VERSION "2021.24.4"

NS_ :

BS_:

BU_: VEH CH Receiver X

BO_ 22 DI_bmsRequest: 1 VEH
 SG_ DI_bmsOpenContactorsRequest : 4|1@1+ (1,0) [0|1] ""  Receiver
 SG_ DI_bmsRequestInterfaceVersion : 0|4@1+ (1,0) [0|15] ""  Receiver

BO_ 470 DIR_limits: 8 Vector__XXX
 SG_ DIR_pstgDisableSW3PS : 63|1@1+ (1,0) [0|0] "" Vector__XXX
 SG_ DIR_pstgDisableHW3PS : 62|1@1+ (1,0) [0|0] "" Vector__XXX
 SG_ DIR_currentLimit : 46|16@1+ (0.1,0) [0|0] "" Vector__XXX
 SG_ DIR_magnetFluxError : 38|8@1- (8e-05,0) [0|0] "" Vector__XXX
 SG_ DIR_statorTempFromResist : 30|8@1+ (1,-40) [0|0] "" Vector__XXX
 SG_ DIR_limitStatorHousingTemp : 29|1@1+ (1,0) [0|0] "" Vector__XXX
 SG_ DIR_limitUnitSpinDownLearning : 28|1@1+ (1,0) [0|0] "" Vector__XXX
 SG_ DIR_limithvDcCableTemp : 27|1@1+ (1,0) [0|0] "" Vector__XXX
 SG_ DIR_limitRotorTemp : 26|1@1+ (1,0) [0|0] "" Vector__XXX
 SG_ DIR_limitposDcBusbarTemp : 25|1@1+ (1,0) [0|0] "" Vector__XXX
 SG_ DIR_limitnegDcBusbarTemp : 24|1@1+ (1,0) [0|0] "" Vector__XXX
 SG_ DIR_limitdcLinkCapTemp : 23|1@1+ (1,0) [0|0] "" Vector__XXX
 SG_ DIR_limitphaseOutLugTemp : 22|1@1+ (1,0) [0|0] "" Vector__XXX
 SG_ DIR_limitphaseOutBusBarWeldTemp : 21|1@1+ (1,0) [0|0] "" Vector__XXX
 SG_ DIR_limitphaseOutBusbarTemp : 20|1@1+ (1,0) [0|0] "" Vector__XXX
 SG_ DIR_limitClutch : 19|1@1+ (1,0) [0|0] "" Vector__XXX
 SG_ DIR_limitStatorFrequency : 18|1@1+ (1,0) [0|0] "" Vector__XXX
 SG_ DIR_limitOilPumpFluidTemp : 17|1@1+ (1,0) [0|0] "" Vector__XXX
 SG_ DIR_limitShockTorque : 16|1@1+ (1,0) [0|0] "" Vector__XXX
 SG_ DIR_limitUnitGPO : 15|1@1+ (1,0) [0|0] "" Vector__XXX
 SG_ DIR_limitDiff : 14|1@1+ (1,0) [0|0] "" Vector__XXX
 SG_ DIR_limitMotorSpeed : 13|1@1+ (1,0) [0|0] "" Vector__XXX
 SG_ DIR_limitDcCapTemp : 12|1@1+ (1,0) [0|0] "" Vector__XXX
 SG_ DIR_limitBaseSpeed : 11|1@1+ (1,0) [0|0] "" Vector__XXX
 SG_ DIR_limitTCRegen : 10|1@1+ (1,0) [0|0] "" Vector__XXX
 SG_ DIR_limitTCDrive : 9|1@1+ (1,0) [0|0] "" Vector__XXX
 SG_ DIR_limitMotorVoltage : 8|1@1+ (1,0) [0|0] "" Vector__XXX
 SG_ DIR_limitMotorCurrent : 7|1@1+ (1,0) [0|0] "" Vector__XXX
 SG_ DIR_limitDischargePower : 6|1@1+ (1,0) [0|0] "" Vector__XXX
 SG_ DIR_limitDeltaFluidTemp : 5|1@1+ (1,0) [0|0] "" Vector__XXX
 SG_ DIR_limitUnitLimp : 4|1@1+ (1,0) [0|0] "" Vector__XXX
 SG_ DIR_limitPoleTemp : 3|1@1+ (1,0) [0|0] "" Vector__XXX
 SG_ DIR_limitStatorTemp : 2|1@1+ (1,0) [0|0] "" Vector__XXX
 SG_ DIR_limitInverterTemp : 1|1@1+ (1,0) [0|0] "" Vector__XXX
 SG_ DIR_limitPCBTemp : 0|1@1+ (1,0) [0|0] "" Vector__XXX

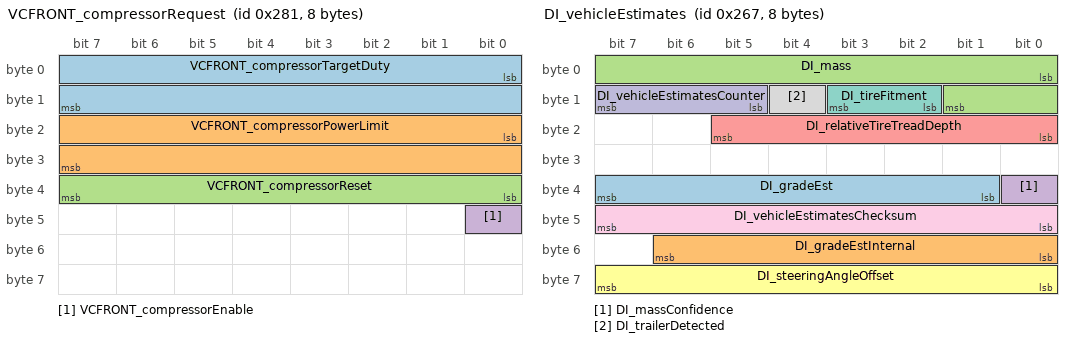
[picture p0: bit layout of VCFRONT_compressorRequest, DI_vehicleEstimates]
BO_ 641 VCFRONT_compressorRequest: 8 VEH
 SG_ VCFRONT_compressorTargetDuty : 0|16@1+ (0.1,0) [0|100] "%"  Receiver
 SG_ VCFRONT_compressorPowerLimit : 16|16@1+ (1,0) [0|65534] "W"  Receiver
 SG_ VCFRONT_compressorReset : 32|8@1+ (1,0) [0|255] ""  Receiver
 SG_ VCFRONT_compressorEnable : 40|1@1+ (1,0) [0|1] ""  Receiver

BO_ 603 APP_status: 8 Vector__XXX
 SG_ APP_statusChecksum : 56|8@1+ (1,0) [0|0] "" Vector__XXX
 SG_ APP_statusCounter : 52|4@1+ (1,0) [0|0] "" Vector__XXX
 SG_ APP_suspendResumeAvailable : 51|1@1+ (1,0) [0|0] "" Vector__XXX
 SG_ APP_uiEthFailoverDisabled : 50|1@1+ (1,0) [0|0] "" Vector__XXX
 SG_ APP_autonomySystemHealth : 49|1@1+ (1,0) [0|0] "" Vector__XXX
 SG_ APP_autoparkVersionIdentifier : 47|2@1+ (1,0) [0|0] "" Vector__XXX
 SG_ APP_sentryState : 44|3@1+ (1,0) [0|0] "" Vector__XXX
 SG_ APP_summonVersionIdentifier : 42|2@1+ (1,0) [0|0] "" Vector__XXX
 SG_ APP_socOperatingMode : 40|2@1+ (1,0) [0|0] "" Vector__XXX
 SG_ APP_DDAWSystemStatus : 37|3@1+ (1,0) [0|0] "" Vector__XXX
 SG_ APP_sendingBUCStream : 35|1@1+ (1,0) [0|0] "" Vector__XXX
 SG_ APP_unifiedObjectStackSupported : 33|2@1+ (1,0) [0|0] "" Vector__XXX
 SG_ APP_excessiveAccelPedalWarning : 32|1@1+ (1,0) [0|0] "" Vector__XXX
 SG_ APP_fsdRevokeCount : 29|3@1+ (1,0) [0|0] "" Vector__XXX
 SG_ APP_teslaVisionUnsupportedReason : 26|3@1+ (1,0) [0|0] "" Vector__XXX
 SG_ APP_teslaVisionSupported : 24|2@1+ (1,0) [0|0] "" Vector__XXX
 SG_ APP_fsdRevokeStrikeoutCount : 21|3@1+ (1,0) [0|0] "" Vector__XXX
 SG_ APP_fsdSuspendState : 19|2@1+ (1,0) [0|0] "" Vector__XXX
 SG_ APP_summonUnavailableReason : 14|5@1+ (1,0) [0|0] "" Vector__XXX
 SG_ APP_allowApActivationWithBrake : 13|1@1+ (1,0) [0|0] "" Vector__XXX
 SG_ APP_clipRecordingStatus : 10|3@1+ (1,0) [0|0] "" Vector__XXX
 SG_ APP_factorySummonStatus : 6|4@1+ (1,0) [0|0] "" Vector__XXX
 SG_ APP_cameraHeaterRequest : 5|1@1+ (1,0) [0|0] "" Vector__XXX
 SG_ APP_fusedState : 3|2@1+ (1,0) [0|0] "" Vector__XXX
 SG_ APP_watchdogState : 0|3@1+ (1,0) [0|0] "" Vector__XXX

BO_ 615 DI_vehicleEstimates: 8 VEH
 SG_ DI_gradeEst : 33|7@1- (1,0) [-40|40] "%"  Receiver
 SG_ DI_gradeEstInternal : 48|7@1- (1,0) [-40|40] "%"  Receiver
 SG_ DI_mass : 0|10@1+ (5,1900) [1900|7010] "kg"  Receiver
 SG_ DI_massConfidence : 32|1@1+ (1,0) [0|1] ""  Receiver
 SG_ DI_relativeTireTreadDepth : 16|6@1- (0.2,0) [-6.2|6.2] "mm"  Receiver
 SG_ DI_steeringAngleOffset : 56|8@1- (0.2,0) [-25.6|25.4] "Deg"  Receiver
 SG_ DI_tireFitment : 10|2@1+ (1,0) [0|3] ""  Receiver
 SG_ DI_trailerDetected : 12|1@1+ (1,0) [0|1] ""  Receiver
 SG_ DI_vehicleEstimatesChecksum : 40|8@1+ (1,0) [0|255] ""  Receiver
 SG_ DI_vehicleEstimatesCounter : 13|3@1+ (1,0) [0|7] ""  Receiver

BO_ 322 VCLEFT_liftgateStatus: 8 Vector__XXX
 SG_ VCLEFT_liftgateLatchRequest m0 : 61|3@1+ (1,0) [0|0] "" Vector__XXX
 SG_ VCLEFT_liftgateAboveCrossoverAng m0 : 59|1@1+ (1,0) [0|0] "" Vector__XXX
 SG_ VCLEFT_liftgateCloseWarnChimeReq m0 : 56|1@1+ (1,0) [0|0] "" Vector__XXX
 SG_ VCLEFT_liftgateGeofenceState m0 : 48|2@1+ (1,0) [0|0] "" Vector__XXX
 SG_ VCLEFT_liftgateNewSaveHeight m0 : 40|8@1+ (1,0) [0|0] "" Vector__XXX
 SG_ VCLEFT_liftgateNewHeightNudge m0 : 39|1@1+ (1,0) [0|0] "" Vector__XXX
 SG_ VCLEFT_liftgateHeight m1 : 38|8@1+ (1,0) [0|0] "" Vector__XXX
 SG_ VCLEFT_liftgateRequestSource m0 : 35|4@1+ (1,0) [0|0] "" Vector__XXX
 SG_ VCLEFT_liftgateStaticStrutMode m0 : 32|3@1+ (1,0) [0|0] "" Vector__XXX
 SG_ VCLEFT_liftgateSpeed m1 : 28|10@1- (0.1,0) [0|0] "" Vector__XXX
 SG_ VCLEFT_liftgateEstimatedStrutTem m0 : 24|8@1+ (1,-60) [0|0] "" Vector__XXX
 SG_ VCLEFT_liftgatePhysicalChimeRequ m0 : 21|3@1+ (1,0) [0|0] "" Vector__XXX
 SG_ VCLEFT_liftgatePosition m1 : 21|7@1- (1,46) [0|0] "" Vector__XXX
 SG_ VCLEFT_liftgateUIChimeRequest m0 : 18|3@1+ (1,0) [0|0] "" Vector__XXX
 SG_ VCLEFT_liftgatePositionCalibrate m0 : 17|1@1+ (1,0) [0|0] "" Vector__XXX
 SG_ VCLEFT_liftgateMvmntNotAllowedCo m0 : 14|3@1+ (1,0) [0|0] "" Vector__XXX
 SG_ VCLEFT_liftgateStrutCurrent m1 : 11|10@1- (0.1,0) [0|0] "" Vector__XXX
 SG_ VCLEFT_liftgateStoppingCondition m0 : 10|4@1+ (1,0) [0|0] "" Vector__XXX
 SG_ VCLEFT_liftgateState m0 : 3|4@1+ (1,0) [0|0] "" Vector__XXX
 SG_ VCLEFT_liftgateStrutDutyCycle m1 : 3|8@1- (1,0) [0|0] "" Vector__XXX
 SG_ VCLEFT_liftgateStatusIndex M : 0|2@1+ (1,0) [0|0] "" Vector__XXX

BO_ 537 VCSEC_TPMSData: 7 CH
 SG_ VCSEC_TPMSDataIndex M : 0|3@1+ (1,0) [0|5] ""  Receiver
 SG_ VCSEC_TPMSPressureFL m5 : 16|8@1+ (0.025,0) [0|6.375] "bar" X
 SG_ VCSEC_TPMSPressureFR m5 : 24|8@1+ (0.025,0) [0|6.375] "bar" X
 SG_ VCSEC_TPMSPressureRL m5 : 32|8@1+ (0.025,0) [0|6.375] "bar" X
 SG_ VCSEC_TPMSPressureRR m5 : 40|8@1+ (0.025,0) [0|6.375] "bar" X
 SG_ VCSEC_TPMSPressure0 m0 : 16|8@1+ (0.05,-1) [-1|11.75] "bar" X
 SG_ VCSEC_TPMSPressure1 m1 : 16|8@1+ (0.05,-1) [-1|11.75] "bar" X
 SG_ VCSEC_TPMSPressure2 m2 : 16|8@1+ (0.05,-1) [-1|11.75] "bar" X
 SG_ VCSEC_TPMSPressure3 m3 : 16|8@1+ (0.05,-1) [-1|11.75] "bar" X
 SG_ VCSEC_TPMSTemperature0 m0 : 24|8@1+ (1,-40) [-40|215] "C" X
 SG_ VCSEC_TPMSTemperature1 m1 : 24|8@1+ (1,-40) [-40|215] "C" X
 SG_ VCSEC_TPMSTemperature2 m2 : 24|8@1+ (1,-40) [-40|215] "C" X
 SG_ VCSEC_TPMSTemperature3 m3 : 24|8@1+ (1,-40) [-40|215] "C" X
 SG_ VCSEC_TPMSBatVoltage0 m0 : 32|8@1+ (0.01,1.5) [1.5|4.04] "V" X
 SG_ VCSEC_TPMSBatVoltage1 m1 : 32|8@1+ (0.01,1.5) [1.5|4.04] "V" X
 SG_ VCSEC_TPMSBatVoltage2 m2 : 32|8@1+ (0.01,1.5) [1.5|4.04] "V" X
 SG_ VCSEC_TPMSBatVoltage3 m3 : 32|8@1+ (0.01,1.5) [1.5|4.04] "V" X

BO_ 1066 VCSEC_TPMSConnectionData: 8 Vector__XXX
 SG_ VCSEC_TPMSSensorPresence3 : 62|2@1+ (1,0) [0|0] "" Vector__XXX
 SG_ VCSEC_TPMSSensorPresence2 : 60|2@1+ (1,0) [0|0] "" Vector__XXX
 SG_ VCSEC_TPMSSensorPresence1 : 58|2@1+ (1,0) [0|0] "" Vector__XXX
 SG_ VCSEC_TPMSSensorPresence0 : 56|2@1+ (1,0) [0|0] "" Vector__XXX
 SG_ VCSEC_TPMSConnectionTypeDesired3 : 54|2@1+ (1,0) [0|0] "" Vector__XXX
 SG_ VCSEC_TPMSConnectionTypeCurrent3 : 52|2@1+ (1,0) [0|0] "" Vector__XXX
 SG_ VCSEC_TPMSRSSI3 : 45|7@1+ (1,-127) [0|0] "" Vector__XXX
 SG_ VCSEC_TPMSSensorState3 : 42|3@1+ (1,0) [0|0] "" Vector__XXX
 SG_ VCSEC_TPMSConnectionTypeDesired2 : 40|2@1+ (1,0) [0|0] "" Vector__XXX
 SG_ VCSEC_TPMSConnectionTypeCurrent2 : 38|2@1+ (1,0) [0|0] "" Vector__XXX
 SG_ VCSEC_TPMSRSSI2 : 31|7@1+ (1,-127) [0|0] "" Vector__XXX
 SG_ VCSEC_TPMSSensorState2 : 28|3@1+ (1,0) [0|0] "" Vector__XXX
 SG_ VCSEC_TPMSConnectionTypeDesired1 : 26|2@1+ (1,0) [0|0] "" Vector__XXX
 SG_ VCSEC_TPMSConnectionTypeCurrent1 : 24|2@1+ (1,0) [0|0] "" Vector__XXX
 SG_ VCSEC_TPMSRSSI1 : 17|7@1+ (1,-127) [0|0] "" Vector__XXX
 SG_ VCSEC_TPMSSensorState1 : 14|3@1+ (1,0) [0|0] "" Vector__XXX
 SG_ VCSEC_TPMSConnectionTypeDesired0 : 12|2@1+ (1,0) [0|0] "" Vector__XXX
 SG_ VCSEC_TPMSConnectionTypeCurrent0 : 10|2@1+ (1,0) [0|0] "" Vector__XXX
 SG_ VCSEC_TPMSRSSI0 : 3|7@1+ (1,-127) [0|0] "" Vector__XXX
 SG_ VCSEC_TPMSSensorState0 : 0|3@1+ (1,0) [0|0] "" Vector__XXX

BO_ 994 VCLEFT_lightStatus: 8 Vector__XXX
 SG_ VCLEFT_tailLightOutageStatus : 51|1@1+ (1,0) [0|0] "" Vector__XXX
 SG_ VCLEFT_reverseTrailerLightStatus : 49|2@1+ (1,0) [0|0] "" Vector__XXX
 SG_ VCLEFT_rideHeightSensorFault : 48|1@1+ (1,0) [0|0] "" Vector__XXX
 SG_ VCLEFT_trailerDetected : 46|2@1+ (1,0) [0|0] "" Vector__XXX
 SG_ VCLEFT_rearRideHeight : 36|8@1- (1,0) [0|0] "" Vector__XXX
 SG_ VCLEFT_frontRideHeight : 28|8@1- (1,0) [0|0] "" Vector__XXX
 SG_ VCLEFT_fogTrailerLightStatus : 26|2@1+ (1,0) [0|0] "" Vector__XXX
 SG_ VCLEFT_tailTrailerLightStatus : 24|2@1+ (1,0) [0|0] "" Vector__XXX
 SG_ VCLEFT_brakeTrailerLightStatus : 22|2@1+ (1,0) [0|0] "" Vector__XXX
 SG_ VCLEFT_rightTrnTrailerLightStatu : 20|2@1+ (1,0) [0|0] "" Vector__XXX
 SG_ VCLEFT_leftTurnTrailerLightStatu : 18|2@1+ (1,0) [0|0] "" Vector__XXX
 SG_ VCLEFT_RRMapLightSwitchPressed : 17|1@1+ (1,0) [0|0] "" Vector__XXX
 SG_ VCLEFT_RLMapLightSwitchPressed : 16|1@1+ (1,0) [0|0] "" Vector__XXX
 SG_ VCLEFT_FRMapLightSwitchPressed : 15|1@1+ (1,0) [0|0] "" Vector__XXX
 SG_ VCLEFT_FLMapLightSwitchPressed : 14|1@1+ (1,0) [0|0] "" Vector__XXX
 SG_ VCLEFT_RRMapLightStatus : 12|2@1+ (1,0) [0|0] "" Vector__XXX
 SG_ VCLEFT_RLMapLightStatus : 10|2@1+ (1,0) [0|0] "" Vector__XXX
 SG_ VCLEFT_FRMapLightStatus : 8|2@1+ (1,0) [0|0] "" Vector__XXX
 SG_ VCLEFT_FLMapLightStatus : 6|2@1+ (1,0) [0|0] "" Vector__XXX
 SG_ VCLEFT_turnSignalStatus : 4|2@1+ (1,0) [0|0] "" Vector__XXX
 SG_ VCLEFT_tailLightStatus : 2|2@1+ (1,0) [0|0] "" Vector__XXX
 SG_ VCLEFT_brakeLightStatus : 0|2@1+ (1,0) [0|0] "" Vector__XXX

BO_ 513 VCFRONT_loggingAndVitals10Hz: 8 Vector__XXX
 SG_ VCFRONT_frunkSwitchGroupState m1 : 62|2@1+ (1,0) [0|0] "" Vector__XXX
 SG_ VCFRONT_ccrExvState m3 : 59|4@1+ (1,0) [0|0] "" Vector__XXX
 SG_ VCFRONT_recircExvState m2 : 59|4@1+ (1,0) [0|0] "" Vector__XXX
 SG_ VCFRONT_frunkStateDBG m1 : 58|4@1+ (1,0) [0|0] "" Vector__XXX
 SG_ VCFRONT_thermalHvPowerBudget m0 : 57|7@1+ (0.2,0) [0|0] "" Vector__XXX
 SG_ VCFRONT_compSleepRequest m0 : 56|1@1+ (1,0) [0|0] "" Vector__XXX
 SG_ VCFRONT_cclExvState m3 : 55|4@1+ (1,0) [0|0] "" Vector__XXX
 SG_ VCFRONT_compLiqPumpOutState m1 : 55|3@1+ (1,0) [0|0] "" Vector__XXX
 SG_ VCFRONT_evapExvState m2 : 55|4@1+ (1,0) [0|0] "" Vector__XXX
 SG_ VCFRONT_hpReqTransScavenge m1 : 54|1@1+ (1,0) [0|0] "" Vector__XXX
 SG_ VCFRONT_chillerExvState m2 : 51|4@1+ (1,0) [0|0] "" Vector__XXX
 SG_ VCFRONT_hpReqCoolantMode m1 : 51|3@1+ (1,0) [0|0] "" Vector__XXX
 SG_ VCFRONT_lccExvState m3 : 51|4@1+ (1,0) [0|0] "" Vector__XXX
 SG_ VCFRONT_hpBatteryLoadType m1 : 49|2@1+ (1,0) [0|0] "" Vector__XXX
 SG_ VCFRONT_hpCabinLoadType m1 : 47|2@1+ (1,0) [0|0] "" Vector__XXX
 SG_ VCFRONT_pressureRefrigLiquid m0 : 47|9@1+ (0.08,0) [0|0] "" Vector__XXX
 SG_ VCFRONT_hpQuietModeEnabled m1 : 46|1@1+ (1,0) [0|0] "" Vector__XXX
 SG_ VCFRONT_hpBlendType m1 : 44|2@1+ (1,0) [0|0] "" Vector__XXX
 SG_ VCFRONT_ccrExvFlow m2 : 43|8@1+ (0.5,0) [0|0] "" Vector__XXX
 SG_ VCFRONT_ccrExvFlowTarget m3 : 43|8@1+ (0.5,0) [0|0] "" Vector__XXX
 SG_ VCFRONT_hpDominantLoad m1 : 41|3@1+ (1,0) [0|0] "" Vector__XXX
 SG_ VCFRONT_activeLouverOpenPosTarg m0 : 40|7@1+ (1,0) [0|0] "" Vector__XXX
 SG_ VCFRONT_hpLowSideHX m1 : 39|2@1+ (1,0) [0|0] "" Vector__XXX
 SG_ VCFRONT_hpHighSideHX m1 : 37|2@1+ (1,0) [0|0] "" Vector__XXX
 SG_ VCFRONT_solenoidEngaged m1 : 36|1@1+ (1,0) [0|0] "" Vector__XXX
 SG_ VCFRONT_cclExvFlow m2 : 35|8@1+ (0.5,0) [0|0] "" Vector__XXX
 SG_ VCFRONT_cclExvFlowTarget m3 : 35|8@1+ (0.5,0) [0|0] "" Vector__XXX
 SG_ VCFRONT_compFaultSeverity m1 : 34|2@1+ (1,0) [0|0] "" Vector__XXX
 SG_ VCFRONT_coolantValveMode m1 : 32|2@1+ (1,0) [0|0] "" Vector__XXX
 SG_ VCFRONT_exvFlowTarget m0 : 32|8@1+ (0.5,0) [0|0] "" Vector__XXX
 SG_ VCFRONT_lccExvFlow m2 : 27|8@1+ (0.5,0) [0|0] "" Vector__XXX
 SG_ VCFRONT_lccExvFlowTarget m3 : 27|8@1+ (0.5,0) [0|0] "" Vector__XXX
 SG_ VCFRONT_compDemandChiller m1 : 25|7@1+ (1,0) [0|0] "" Vector__XXX
 SG_ VCFRONT_radiatorFanRPMActual m0 : 24|8@1+ (40,0) [0|0] "" Vector__XXX
 SG_ VCFRONT_solenoidEvapState m1 : 23|2@1+ (1,0) [0|0] "" Vector__XXX
 SG_ VCFRONT_exvState m1 : 19|4@1+ (1,0) [0|0] "" Vector__XXX
 SG_ VCFRONT_recircExvFlow m2 : 19|8@1+ (0.5,0) [0|0] "" Vector__XXX
 SG_ VCFRONT_recircExvFlowTarget m3 : 19|8@1+ (0.5,0) [0|0] "" Vector__XXX
 SG_ VCFRONT_pumpPowertrainRPMActual m0 : 16|8@1+ (30,0) [0|0] "" Vector__XXX
 SG_ VCFRONT_compDemandEvap m1 : 12|7@1+ (1,0) [0|0] "" Vector__XXX
 SG_ VCFRONT_evapExvFlow m2 : 11|8@1+ (0.5,0) [0|0] "" Vector__XXX
 SG_ VCFRONT_evapExvFlowTarget m3 : 11|8@1+ (0.5,0) [0|0] "" Vector__XXX
 SG_ VCFRONT_compressorState m1 : 10|2@1+ (1,0) [0|0] "" Vector__XXX
 SG_ VCFRONT_pumpBatteryRPMActual m0 : 8|8@1+ (30,0) [0|0] "" Vector__XXX
 SG_ VCFRONT_chillerExvFlow m2 : 3|8@1+ (0.5,0) [0|0] "" Vector__XXX
 SG_ VCFRONT_chillerExvFlowTarget m3 : 3|8@1+ (0.5,0) [0|0] "" Vector__XXX
 SG_ VCFRONT_fanDemand m1 : 3|7@1+ (1,0) [0|0] "" Vector__XXX
 SG_ VCFRONT_loggingAndVitals10HzIndex M : 0|3@1+ (1,0) [0|0] "" Vector__XXX

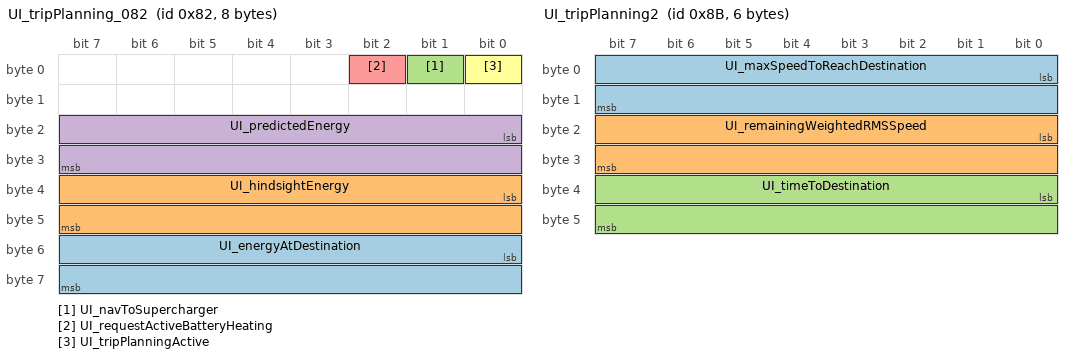
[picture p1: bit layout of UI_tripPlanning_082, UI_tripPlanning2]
BO_ 130 UI_tripPlanning_082: 8 VEH
 SG_ UI_energyAtDestination : 48|16@1- (0.01,0) [-327.67|327.67] "kWh" X
 SG_ UI_hindsightEnergy : 32|16@1- (0.01,0) [-327.67|327.67] "kWh" X
 SG_ UI_navToSupercharger : 1|1@1+ (1,0) [0|1] "" X
 SG_ UI_predictedEnergy : 16|16@1- (0.01,0) [-327.67|327.67] "kWh" X
 SG_ UI_requestActiveBatteryHeating : 2|1@1+ (1,0) [0|1] "" X
 SG_ UI_tripPlanningActive : 0|1@1+ (1,0) [0|1] "" X

BO_ 139 UI_tripPlanning2: 6 VEH
 SG_ UI_maxSpeedToReachDestination : 0|16@1+ (0.01,0) [0|655.34] "m/s" X
 SG_ UI_remainingWeightedRMSSpeed : 16|16@1+ (0.01,0) [0|655.34] "m/s" X
 SG_ UI_timeToDestination : 32|16@1+ (1,0) [0|65534] "s" X

BO_ 680 EPBL_status: 8 Vector__XXX
 SG_ EPBL_statusChecksum : 56|8@1+ (1,0) [0|0] "" Vector__XXX
 SG_ EPBL_statusCounter : 52|4@1+ (1,0) [0|0] "" Vector__XXX
 SG_ EPBL_blockDrive : 51|1@1+ (1,0) [0|0] "" Vector__XXX
 SG_ EPBL_bothDisconnected : 50|1@1+ (1,0) [0|0] "" Vector__XXX
 SG_ EPBL_winchModeAvailable : 49|1@1+ (1,0) [0|0] "" Vector__XXX
 SG_ EPBL_hornRequest : 48|1@1+ (1,0) [0|0] "" Vector__XXX
 SG_ EPBL_okToPark : 47|1@1+ (1,0) [0|0] "" Vector__XXX
 SG_ EPBL_espPowerRequest : 46|1@1+ (1,0) [0|0] "" Vector__XXX
 SG_ EPBL_showStalkFaultedOnUi : 45|1@1+ (1,0) [0|0] "" Vector__XXX
 SG_ EPBL_autonomyBehavior : 43|2@1+ (1,0) [0|0] "" Vector__XXX
 SG_ EPBL_uiWinchModeLvStatus : 33|2@1+ (1,0) [0|0] "" Vector__XXX
 SG_ EPBL_showUiGearShifter : 32|1@1+ (1,0) [0|0] "" Vector__XXX
 SG_ EPBL_brakeDiscWipeRequest : 30|2@1+ (1,0) [0|0] "" Vector__XXX
 SG_ EPBL_uiParkAvailable : 28|2@1+ (1,0) [0|0] "" Vector__XXX
 SG_ EPBL_cdpRequest : 27|1@1+ (1,0) [0|0] "" Vector__XXX
 SG_ EPBL_winchModePending : 26|1@1+ (1,0) [0|0] "" Vector__XXX
 SG_ EPBL_winchModePermissive : 25|1@1+ (1,0) [0|0] "" Vector__XXX
 SG_ EPBL_updateMode : 24|1@1+ (1,0) [0|0] "" Vector__XXX
 SG_ EPBL_winchModeActive : 23|1@1+ (1,0) [0|0] "" Vector__XXX
 SG_ EPBL_uiWinchModeMiscBlocking : 22|1@1+ (1,0) [0|0] "" Vector__XXX
 SG_ EPBL_requestUserConfirmation : 21|1@1+ (1,0) [0|0] "" Vector__XXX
 SG_ EPBL_brakeConfirmedPressed : 20|1@1+ (1,0) [0|0] "" Vector__XXX
 SG_ EPBL_epbConfigMismatch : 19|1@1+ (1,0) [0|0] "" Vector__XXX
 SG_ EPBL_brakeLight : 18|1@1+ (1,0) [0|0] "" Vector__XXX
 SG_ EPBL_summonEnabled : 17|1@1+ (1,0) [0|0] "" Vector__XXX
 SG_ EPBL_redundantBrakingEnabled : 16|1@1+ (1,0) [0|0] "" Vector__XXX
 SG_ EPBL_contactorCycleNotNeededForWinchEntry : 15|1@1+ (1,0) [0|0] "" Vector__XXX
 SG_ EPBL_telltale : 12|3@1+ (1,0) [0|0] "" Vector__XXX
 SG_ EPBL_chimeRequest : 9|3@1+ (1,0) [0|0] "" Vector__XXX
 SG_ EPBL_systemCdpAvailable : 8|1@1+ (1,0) [0|0] "" Vector__XXX
 SG_ EPBL_driverIsLeavingAnySpeed : 7|1@1+ (1,0) [0|0] "" Vector__XXX
 SG_ EPBL_driverIsLeaving : 6|1@1+ (1,0) [0|0] "" Vector__XXX
 SG_ EPBL_freeRollModeStatus : 4|2@1+ (1,0) [0|0] "" Vector__XXX
 SG_ EPBL_systemStatus : 0|4@1+ (1,0) [0|0] "" Vector__XXX

BO_ 1029 VIN_info: 8 VEH
 SG_ VIN_infoIndex M : 0|8@1+ (1,0) [0|255] "" X
 SG_ VIN_B405 m17 : 8|56@1+ (1,0) [0|7.2057594038E+016] "" X
 SG_ VIN_C405 m18 : 8|56@1+ (1,0) [0|7.2057594038E+016] "" X
 SG_ VIN_A405 m16 : 8|56@1+ (1,0) [0|7.2057594038E+016] "" X

BO_ 1025 BMS_brickVoltages: 8 VEH
 SG_ BMS_brickIndex M : 0|8@1+ (1,0) [0|0] ""  Receiver
 SG_ BMS_brickStatus : 8|8@1+ (1,0) [0|0] ""  Receiver
 SG_ BMS_brick0 m0 : 16|16@1+ (0.0001,0) [0|0] "V"  Receiver
 SG_ BMS_brick1 m0 : 32|16@1+ (0.0001,0) [0|0] "V"  Receiver
 SG_ BMS_brick2 m0 : 48|16@1+ (0.0001,0) [0|0] "V"  Receiver
 SG_ BMS_brick3 m1 : 16|16@1+ (0.0001,0) [0|0] "V"  Receiver
 SG_ BMS_brick4 m1 : 32|16@1+ (0.0001,0) [0|0] "V"  Receiver
 SG_ BMS_brick5 m1 : 48|16@1+ (0.0001,0) [0|0] "V"  Receiver
 SG_ BMS_brick6 m2 : 16|16@1+ (0.0001,0) [0|0] "V"  Receiver
 SG_ BMS_brick7 m2 : 32|16@1+ (0.0001,0) [0|0] "V"  Receiver
 SG_ BMS_brick8 m2 : 48|16@1+ (0.0001,0) [0|0] "V"  Receiver
 SG_ BMS_brick9 m3 : 16|16@1+ (0.0001,0) [0|0] "V"  Receiver
 SG_ BMS_brick10 m3 : 32|16@1+ (0.0001,0) [0|0] "V"  Receiver
 SG_ BMS_brick11 m3 : 48|16@1+ (0.0001,0) [0|0] "V"  Receiver
 SG_ BMS_brick12 m4 : 16|16@1+ (0.0001,0) [0|0] "V"  Receiver
 SG_ BMS_brick13 m4 : 32|16@1+ (0.0001,0) [0|0] "V"  Receiver
 SG_ BMS_brick14 m4 : 48|16@1+ (0.0001,0) [0|0] "V"  Receiver
 SG_ BMS_brick15 m5 : 16|16@1+ (0.0001,0) [0|0] "V"  Receiver
 SG_ BMS_brick16 m5 : 32|16@1+ (0.0001,0) [0|0] "V"  Receiver
 SG_ BMS_brick17 m5 : 48|16@1+ (0.0001,0) [0|0] "V"  Receiver
 SG_ BMS_brick18 m6 : 16|16@1+ (0.0001,0) [0|0] "V"  Receiver
 SG_ BMS_brick19 m6 : 32|16@1+ (0.0001,0) [0|0] "V"  Receiver
 SG_ BMS_brick20 m6 : 48|16@1+ (0.0001,0) [0|0] "V"  Receiver
 SG_ BMS_brick21 m7 : 16|16@1+ (0.0001,0) [0|0] "V"  Receiver
 SG_ BMS_brick22 m7 : 32|16@1+ (0.0001,0) [0|0] "V"  Receiver
 SG_ BMS_brick23 m7 : 48|16@1+ (0.0001,0) [0|0] "V"  Receiver
 SG_ BMS_brick24 m8 : 16|16@1+ (0.0001,0) [0|0] "V"  Receiver
 SG_ BMS_brick25 m8 : 32|16@1+ (0.0001,0) [0|0] "V"  Receiver
 SG_ BMS_brick26 m8 : 48|16@1+ (0.0001,0) [0|0] "V"  Receiver
 SG_ BMS_brick27 m9 : 16|16@1+ (0.0001,0) [0|0] "V"  Receiver
 SG_ BMS_brick28 m9 : 32|16@1+ (0.0001,0) [0|0] "V"  Receiver
 SG_ BMS_brick29 m9 : 48|16@1+ (0.0001,0) [0|0] "V"  Receiver
 SG_ BMS_brick30 m10 : 16|16@1+ (0.0001,0) [0|0] "V"  Receiver
 SG_ BMS_brick31 m10 : 32|16@1+ (0.0001,0) [0|0] "V"  Receiver
 SG_ BMS_brick32 m10 : 48|16@1+ (0.0001,0) [0|0] "V"  Receiver
 SG_ BMS_brick34 m11 : 16|16@1+ (0.0001,0) [0|0] "V"  Receiver
 SG_ BMS_brick33 m11 : 32|16@1+ (0.0001,0) [0|0] "V"  Receiver
 SG_ BMS_brick35 m11 : 48|16@1+ (0.0001,0) [0|0] "V"  Receiver
 SG_ BMS_brick36 m12 : 16|16@1+ (0.0001,0) [0|0] "V"  Receiver
 SG_ BMS_brick37 m12 : 32|16@1+ (0.0001,0) [0|0] "V"  Receiver
 SG_ BMS_brick38 m12 : 48|16@1+ (0.0001,0) [0|0] "V"  Receiver
 SG_ BMS_brick39 m13 : 16|16@1+ (0.0001,0) [0|0] "V"  Receiver
 SG_ BMS_brick40 m13 : 32|16@1+ (0.0001,0) [0|0] "V"  Receiver
 SG_ BMS_brick41 m13 : 48|16@1+ (0.0001,0) [0|0] "V"  Receiver
 SG_ BMS_brick42 m14 : 16|16@1+ (0.0001,0) [0|0] "V"  Receiver
 SG_ BMS_brick43 m14 : 32|16@1+ (0.0001,0) [0|0] "V"  Receiver
 SG_ BMS_brick44 m14 : 48|16@1+ (0.0001,0) [0|0] "V"  Receiver
 SG_ BMS_brick45 m15 : 16|16@1+ (0.0001,0) [0|0] "V"  Receiver
 SG_ BMS_brick46 m15 : 32|16@1+ (0.0001,0) [0|0] "V"  Receiver
 SG_ BMS_brick47 m15 : 48|16@1+ (0.0001,0) [0|0] "V"  Receiver
 SG_ BMS_brick48 m16 : 16|16@1+ (0.0001,0) [0|0] "V"  Receiver
 SG_ BMS_brick49 m16 : 32|16@1+ (0.0001,0) [0|0] "V"  Receiver
 SG_ BMS_brick50 m16 : 48|16@1+ (0.0001,0) [0|0] "V"  Receiver
 SG_ BMS_brick51 m17 : 16|16@1+ (0.0001,0) [0|0] "V"  Receiver
 SG_ BMS_brick52 m17 : 32|16@1+ (0.0001,0) [0|0] "V"  Receiver
 SG_ BMS_brick53 m17 : 48|16@1+ (0.0001,0) [0|0] "V"  Receiver
 SG_ BMS_brick54 m18 : 16|16@1+ (0.0001,0) [0|0] "V"  Receiver
 SG_ BMS_brick55 m18 : 32|16@1+ (0.0001,0) [0|0] "V"  Receiver
 SG_ BMS_brick56 m18 : 48|16@1+ (0.0001,0) [0|0] "V"  Receiver
 SG_ BMS_brick57 m19 : 16|16@1+ (0.0001,0) [0|0] "V"  Receiver
 SG_ BMS_brick58 m19 : 32|16@1+ (0.0001,0) [0|0] "V"  Receiver
 SG_ BMS_brick59 m19 : 48|16@1+ (0.0001,0) [0|0] "V"  Receiver
 SG_ BMS_brick60 m20 : 16|16@1+ (0.0001,0) [0|0] "V"  Receiver
 SG_ BMS_brick61 m20 : 32|16@1+ (0.0001,0) [0|0] "V"  Receiver
 SG_ BMS_brick62 m20 : 48|16@1+ (0.0001,0) [0|0] "V"  Receiver
 SG_ BMS_brick63 m21 : 16|16@1+ (0.0001,0) [0|0] "V"  Receiver
 SG_ BMS_brick64 m21 : 32|16@1+ (0.0001,0) [0|0] "V"  Receiver
 SG_ BMS_brick65 m21 : 48|16@1+ (0.0001,0) [0|0] "V"  Receiver
 SG_ BMS_brick66 m22 : 16|16@1+ (0.0001,0) [0|0] "V"  Receiver
 SG_ BMS_brick67 m22 : 32|16@1+ (0.0001,0) [0|0] "V"  Receiver
 SG_ BMS_brick68 m22 : 48|16@1+ (0.0001,0) [0|0] "V"  Receiver
 SG_ BMS_brick69 m23 : 16|16@1+ (0.0001,0) [0|0] "V"  Receiver
 SG_ BMS_brick70 m23 : 32|16@1+ (0.0001,0) [0|0] "V"  Receiver
 SG_ BMS_brick71 m23 : 48|16@1+ (0.0001,0) [0|0] "V"  Receiver
 SG_ BMS_brick72 m24 : 16|16@1+ (0.0001,0) [0|0] "V"  Receiver
 SG_ BMS_brick73 m24 : 32|16@1+ (0.0001,0) [0|0] "V"  Receiver
 SG_ BMS_brick74 m24 : 48|16@1+ (0.0001,0) [0|0] "V"  Receiver
 SG_ BMS_brick75 m25 : 16|16@1+ (0.0001,0) [0|0] "V"  Receiver
 SG_ BMS_brick76 m25 : 32|16@1+ (0.0001,0) [0|0] "V"  Receiver
 SG_ BMS_brick77 m25 : 48|16@1+ (0.0001,0) [0|0] "V"  Receiver
 SG_ BMS_brick78 m26 : 16|16@1+ (0.0001,0) [0|0] "V"  Receiver
 SG_ BMS_brick79 m26 : 32|16@1+ (0.0001,0) [0|0] "V"  Receiver
 SG_ BMS_brick80 m26 : 48|16@1+ (0.0001,0) [0|0] "V"  Receiver
 SG_ BMS_brick81 m27 : 16|16@1+ (0.0001,0) [0|0] "V"  Receiver
 SG_ BMS_brick82 m27 : 32|16@1+ (0.0001,0) [0|0] "V"  Receiver
 SG_ BMS_brick83 m27 : 48|16@1+ (0.0001,0) [0|0] "V"  Receiver
 SG_ BMS_brick84 m28 : 16|16@1+ (0.0001,0) [0|0] "V"  Receiver
 SG_ BMS_brick85 m28 : 32|16@1+ (0.0001,0) [0|0] "V"  Receiver
 SG_ BMS_brick86 m28 : 48|16@1+ (0.0001,0) [0|0] "V"  Receiver
 SG_ BMS_brick87 m29 : 16|16@1+ (0.0001,0) [0|0] "V"  Receiver
 SG_ BMS_brick88 m29 : 32|16@1+ (0.0001,0) [0|0] "V"  Receiver
 SG_ BMS_brick89 m29 : 48|16@1+ (0.0001,0) [0|0] "V"  Receiver
 SG_ BMS_brick90 m30 : 16|16@1+ (0.0001,0) [0|0] "V"  Receiver
 SG_ BMS_brick91 m30 : 32|16@1+ (0.0001,0) [0|0] "V"  Receiver
 SG_ BMS_brick92 m30 : 48|16@1+ (0.0001,0) [0|0] "V"  Receiver
 SG_ BMS_brick93 m31 : 16|16@1+ (0.0001,0) [0|0] "V"  Receiver
 SG_ BMS_brick94 m31 : 32|16@1+ (0.0001,0) [0|0] "V"  Receiver
 SG_ BMS_brick95 m31 : 48|16@1+ (0.0001,0) [0|0] "V"  Receiver
 SG_ BMS_brick96 m32 : 16|16@1+ (0.0001,0) [0|0] "V"  Receiver
 SG_ BMS_brick97 m32 : 32|16@1+ (0.0001,0) [0|0] "V"  Receiver
 SG_ BMS_brick98 m32 : 48|16@1+ (0.0001,0) [0|0] "V"  Receiver
 SG_ BMS_brick99 m33 : 16|16@1+ (0.0001,0) [0|0] "V"  Receiver
 SG_ BMS_brick100 m33 : 32|16@1+ (0.0001,0) [0|0] "V"  Receiver
 SG_ BMS_brick101 m33 : 48|16@1+ (0.0001,0) [0|0] "V"  Receiver
 SG_ BMS_brick102 m34 : 16|16@1+ (0.0001,0) [0|0] "V"  Receiver
 SG_ BMS_brick103 m34 : 32|16@1+ (0.0001,0) [0|0] "V"  Receiver
 SG_ BMS_brick104 m34 : 48|16@1+ (0.0001,0) [0|0] "V"  Receiver
 SG_ BMS_brick105 m35 : 16|16@1+ (0.0001,0) [0|0] "V"  Receiver
 SG_ BMS_brick106 m35 : 32|16@1+ (0.0001,0) [0|0] "V"  Receiver
 SG_ BMS_brick107 m35 : 48|16@1+ (0.0001,0) [0|0] "V"  Receiver

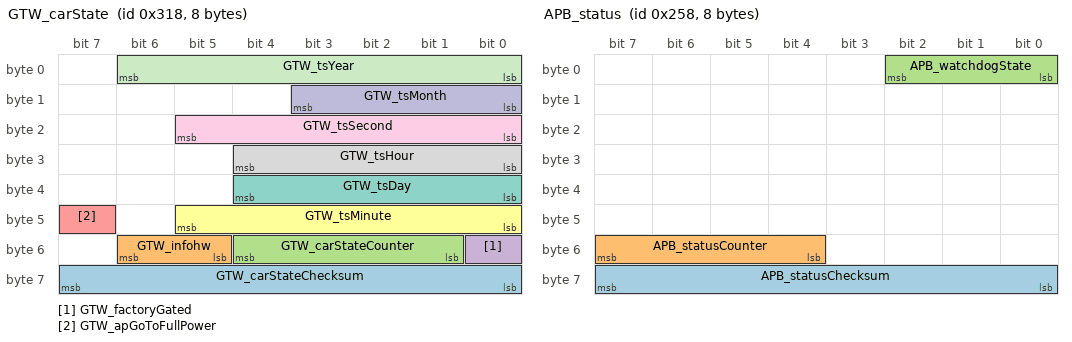
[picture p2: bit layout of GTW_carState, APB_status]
BO_ 792 GTW_carState: 8 Vector__XXX
 SG_ GTW_carStateChecksum : 56|8@1+ (1,0) [0|0] "" Vector__XXX
 SG_ GTW_infohw : 53|2@1+ (1,0) [0|0] "" Vector__XXX
 SG_ GTW_carStateCounter : 49|4@1+ (1,0) [0|0] "" Vector__XXX
 SG_ GTW_factoryGated : 48|1@1+ (1,0) [0|0] "" Vector__XXX
 SG_ GTW_apGoToFullPower : 47|1@1+ (1,0) [0|0] "" Vector__XXX
 SG_ GTW_tsMinute : 40|6@1+ (1,0) [0|0] "" Vector__XXX
 SG_ GTW_tsDay : 32|5@1+ (1,0) [0|0] "" Vector__XXX
 SG_ GTW_tsHour : 24|5@1+ (1,0) [0|0] "" Vector__XXX
 SG_ GTW_tsSecond : 16|6@1+ (1,0) [0|0] "" Vector__XXX
 SG_ GTW_tsMonth : 8|4@1+ (1,0) [0|0] "" Vector__XXX
 SG_ GTW_tsYear : 0|7@1+ (1,2000) [0|0] "" Vector__XXX

BO_ 1320 GTW_time: 4 Vector__XXX
 SG_ GTW_timeSecs : 7|32@0+ (1,0) [0|0] "" Vector__XXX

BO_ 600 APB_status: 8 CH
 SG_ APB_statusChecksum: 56|8@1+ (1,0) [0|0] "" X
 SG_ APB_statusCounter: 52|4@1+ (1,0) [0|0] "" X
 SG_ APB_watchdogState: 0|3@1+ (1,0) [0|0] "" X

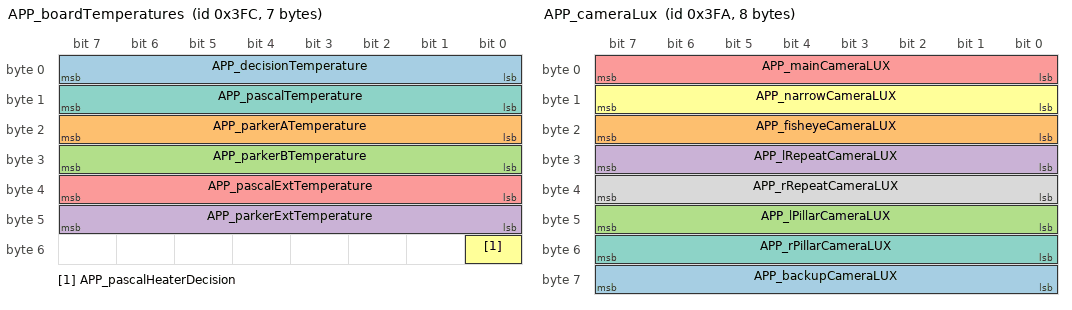
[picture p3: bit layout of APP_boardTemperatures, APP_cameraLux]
BO_ 1020 APP_boardTemperatures: 7 CH
 SG_ APP_decisionTemperature: 0|8@1+ (1,-128) [0|0] "C" X
 SG_ APP_parkerATemperature: 16|8@1+ (1,-128) [0|0] "C" X
 SG_ APP_parkerBTemperature: 24|8@1+ (1,-128) [0|0] "C" X
 SG_ APP_parkerExtTemperature: 40|8@1+ (1,-128) [0|0] "C" X
 SG_ APP_pascalExtTemperature: 32|8@1+ (1,-128) [0|0] "C" X
 SG_ APP_pascalHeaterDecision: 48|1@1+ (1,0) [0|0] "" X
 SG_ APP_pascalTemperature: 8|8@1+ (1,-128) [0|0] "C" X

BO_ 1012 APP_camCalibrationStatus: 6 CH
 SG_ APP_cameraPosition M: 0|4@1+ (1,0) [0|0] "" X
 SG_ APP_mainCamExtPitchCal m1: 8|9@1+ (0.05,-12.5) [0|0] "deg" X
 SG_ APP_mainCamExtYawCal m1: 17|9@1+ (0.05,-12.5) [0|0] "deg" X
 SG_ APP_mainCalibTime m1: 26|7@1+ (1,0) [0|0] "min" X
 SG_ APP_mainCalibProgress m1: 33|7@1+ (1,0) [0|0] "percent" X
 SG_ APP_mainCalibrated m1: 40|1@1+ (1,0) [0|0] "" X
 SG_ APP_narrowCamExtPitchCal m2: 8|9@1+ (0.05,-12.5) [0|0] "deg" X
 SG_ APP_narrowCamExtYawCal m2: 17|9@1+ (0.05,-12.5) [0|0] "deg" X
 SG_ APP_narrowCalibTime m2: 26|7@1+ (1,0) [0|0] "min" X
 SG_ APP_narrowCalibProgress m2: 33|7@1+ (1,0) [0|0] "percent" X
 SG_ APP_narrowCalibrated m2: 40|1@1+ (1,0) [0|0] "" X
 SG_ APP_fisheyeCamExtPitchCal m3: 8|9@1+ (0.05,-12.5) [0|0] "deg" X
 SG_ APP_fisheyeCamExtYawCal m3: 17|9@1+ (0.05,-12.5) [0|0] "deg" X
 SG_ APP_fisheyeCalibTime m3: 26|7@1+ (1,0) [0|0] "min" X
 SG_ APP_fisheyeCalibProgress m3: 33|7@1+ (1,0) [0|0] "percent" X
 SG_ APP_fisheyeCalibrated m3: 40|1@1+ (1,0) [0|0] "" X
 SG_ APP_lPillarCamExtPitchCal m4: 8|9@1+ (0.05,-12.5) [0|0] "deg" X
 SG_ APP_lPillarCamExtYawCal m4: 17|9@1+ (0.05,-12.5) [0|0] "deg" X
 SG_ APP_lPillarCalibTime m4: 26|7@1+ (1,0) [0|0] "min" X
 SG_ APP_lPillarCalibProgress m4: 33|7@1+ (1,0) [0|0] "percent" X
 SG_ APP_lPillarCalibrated m4: 40|1@1+ (1,0) [0|0] "" X
 SG_ APP_rPillarCamExtPitchCal m5: 8|9@1+ (0.05,-12.5) [0|0] "deg" X
 SG_ APP_rPillarCamExtYawCal m5: 17|9@1+ (0.05,-12.5) [0|0] "deg" X
 SG_ APP_rPillarCalibTime m5: 26|7@1+ (1,0) [0|0] "min" X
 SG_ APP_rPillarCalibProgress m5: 33|7@1+ (1,0) [0|0] "percent" X
 SG_ APP_rPillarCalibrated m5: 40|1@1+ (1,0) [0|0] "" X
 SG_ APP_lRepeatCamExtPitchCal m6: 8|9@1+ (0.05,-12.5) [0|0] "deg" X
 SG_ APP_lRepeatCamExtYawCal m6: 17|9@1+ (0.05,-12.5) [0|0] "deg" X
 SG_ APP_lRepeatCalibTime m6: 26|7@1+ (1,0) [0|0] "min" X
 SG_ APP_lRepeatCalibProgress m6: 33|7@1+ (1,0) [0|0] "percent" X
 SG_ APP_lRepeatCalibrated m6: 40|1@1+ (1,0) [0|0] "" X
 SG_ APP_rRepeatCamExtPitchCal m7: 8|9@1+ (0.05,-12.5) [0|0] "deg" X
 SG_ APP_rRepeatCamExtYawCal m7: 17|9@1+ (0.05,-12.5) [0|0] "deg" X
 SG_ APP_rRepeatCalibTime m7: 26|7@1+ (1,0) [0|0] "min" X
 SG_ APP_rRepeatCalibProgress m7: 33|7@1+ (1,0) [0|0] "percent" X
 SG_ APP_rRepeatCalibrated m7: 40|1@1+ (1,0) [0|0] "" X
 SG_ APP_backupCamExtPitchCal m8: 8|9@1+ (0.05,-12.5) [0|0] "deg" X
 SG_ APP_backupCamExtYawCal m8: 17|9@1+ (0.05,-12.5) [0|0] "deg" X
 SG_ APP_backupCalibTime m8: 26|7@1+ (1,0) [0|0] "min" X
 SG_ APP_backupCalibProgress m8: 33|7@1+ (1,0) [0|0] "percent" X
 SG_ APP_backupCalibrated m8: 40|1@1+ (1,0) [0|0] "" X

BO_ 1018 APP_cameraLux: 8 CH
 SG_ APP_backupCameraLUX: 56|8@1+ (50,0) [0|0] "lux" X
 SG_ APP_fisheyeCameraLUX: 16|8@1+ (50,0) [0|0] "lux" X
 SG_ APP_lPillarCameraLUX: 40|8@1+ (50,0) [0|0] "lux" X
 SG_ APP_lRepeatCameraLUX: 24|8@1+ (50,0) [0|0] "lux" X
 SG_ APP_mainCameraLUX: 0|8@1+ (50,0) [0|0] "lux" X
 SG_ APP_narrowCameraLUX: 8|8@1+ (50,0) [0|0] "lux" X
 SG_ APP_rPillarCameraLUX: 48|8@1+ (50,0) [0|0] "lux" X
 SG_ APP_rRepeatCameraLUX: 32|8@1+ (50,0) [0|0] "lux" X

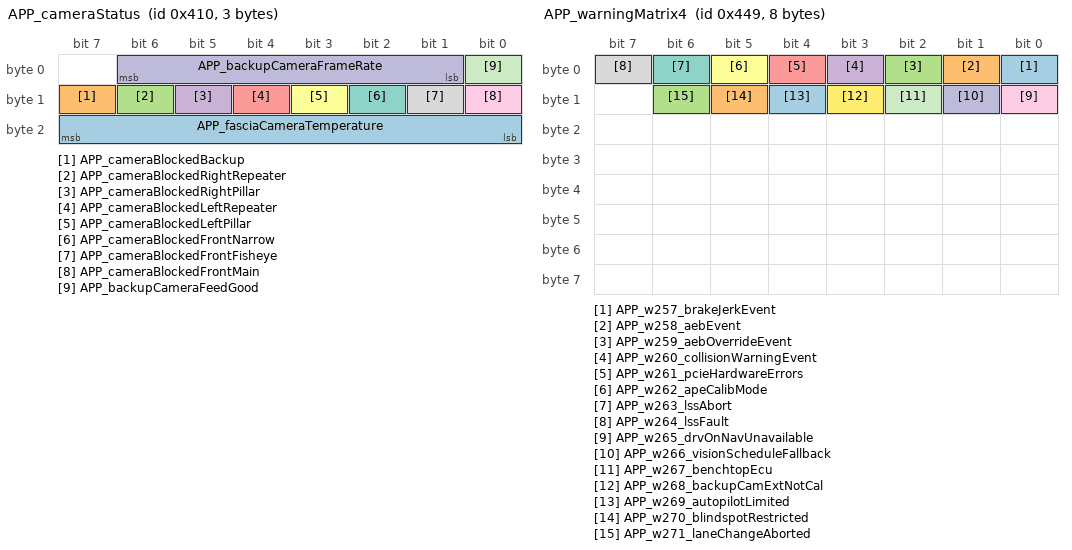
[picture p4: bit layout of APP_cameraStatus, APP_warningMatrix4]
BO_ 1040 APP_cameraStatus: 3 Vector__XXX
 SG_ APP_fasciaCameraTemperature : 16|8@1+ (1,-60) [0|0] "" Vector__XXX
 SG_ APP_cameraBlockedBackup : 15|1@1+ (1,0) [0|0] "" Vector__XXX
 SG_ APP_cameraBlockedRightRepeater : 14|1@1+ (1,0) [0|0] "" Vector__XXX
 SG_ APP_cameraBlockedRightPillar : 13|1@1+ (1,0) [0|0] "" Vector__XXX
 SG_ APP_cameraBlockedLeftRepeater : 12|1@1+ (1,0) [0|0] "" Vector__XXX
 SG_ APP_cameraBlockedLeftPillar : 11|1@1+ (1,0) [0|0] "" Vector__XXX
 SG_ APP_cameraBlockedFrontNarrow : 10|1@1+ (1,0) [0|0] "" Vector__XXX
 SG_ APP_cameraBlockedFrontFisheye : 9|1@1+ (1,0) [0|0] "" Vector__XXX
 SG_ APP_cameraBlockedFrontMain : 8|1@1+ (1,0) [0|0] "" Vector__XXX
 SG_ APP_backupCameraFrameRate : 1|6@1+ (1,0) [0|0] "" Vector__XXX
 SG_ APP_backupCameraFeedGood : 0|1@1+ (1,0) [0|0] "" Vector__XXX

BO_ 1353 APP_info: 8 Vector__XXX
 SG_ APP_bootCount m3 : 8|32@1+ (1,0) [0|0] "" Vector__XXX
 SG_ APP_buildType m0 : 8|8@1+ (1,0) [0|0] "" Vector__XXX
 SG_ APP_infoAppApGitHashBytes m2 : 8|56@1+ (1,0) [0|0] "" Vector__XXX
 SG_ APP_infoAppFwGitHashBytes m1 : 8|56@1+ (1,0) [0|0] "" Vector__XXX
 SG_ APP_infoIndex M : 0|8@1+ (1,0) [0|0] "" Vector__XXX

BO_ 601 APP_status_259: 8 Vector__XXX
 SG_ APP_statusChecksum : 56|8@1+ (1,0) [0|0] "" Vector__XXX
 SG_ APP_statusCounter : 52|4@1+ (1,0) [0|0] "" Vector__XXX
 SG_ APP_suspendResumeAvailable : 51|1@1+ (1,0) [0|0] "" Vector__XXX
 SG_ APP_uiEthFailoverDisabled : 50|1@1+ (1,0) [0|0] "" Vector__XXX
 SG_ APP_autonomySystemHealth : 49|1@1+ (1,0) [0|0] "" Vector__XXX
 SG_ APP_autoparkVersionIdentifier : 47|2@1+ (1,0) [0|0] "" Vector__XXX
 SG_ APP_sentryState : 44|3@1+ (1,0) [0|0] "" Vector__XXX
 SG_ APP_summonVersionIdentifier : 42|2@1+ (1,0) [0|0] "" Vector__XXX
 SG_ APP_socOperatingMode : 40|2@1+ (1,0) [0|0] "" Vector__XXX
 SG_ APP_DDAWSystemStatus : 37|3@1+ (1,0) [0|0] "" Vector__XXX
 SG_ APP_sendingBUCStream : 35|1@1+ (1,0) [0|0] "" Vector__XXX
 SG_ APP_unifiedObjectStackSupported : 33|2@1+ (1,0) [0|0] "" Vector__XXX
 SG_ APP_excessiveAccelPedalWarning : 32|1@1+ (1,0) [0|0] "" Vector__XXX
 SG_ APP_fsdRevokeCount : 29|3@1+ (1,0) [0|0] "" Vector__XXX
 SG_ APP_teslaVisionUnsupportedReason : 26|3@1+ (1,0) [0|0] "" Vector__XXX
 SG_ APP_teslaVisionSupported : 24|2@1+ (1,0) [0|0] "" Vector__XXX
 SG_ APP_fsdRevokeStrikeoutCount : 21|3@1+ (1,0) [0|0] "" Vector__XXX
 SG_ APP_fsdSuspendState : 19|2@1+ (1,0) [0|0] "" Vector__XXX
 SG_ APP_summonUnavailableReason : 14|5@1+ (1,0) [0|0] "" Vector__XXX
 SG_ APP_allowApActivationWithBrake : 13|1@1+ (1,0) [0|0] "" Vector__XXX
 SG_ APP_clipRecordingStatus : 10|3@1+ (1,0) [0|0] "" Vector__XXX
 SG_ APP_factorySummonStatus : 6|4@1+ (1,0) [0|0] "" Vector__XXX
 SG_ APP_cameraHeaterRequest : 5|1@1+ (1,0) [0|0] "" Vector__XXX
 SG_ APP_fusedState : 3|2@1+ (1,0) [0|0] "" Vector__XXX
 SG_ APP_watchdogState : 0|3@1+ (1,0) [0|0] "" Vector__XXX

BO_ 809 APP_warningMatrix0: 8 CH
 SG_ APP_w001_DEPRECATED: 0|1@1+ (1,0) [0|0] "" X
 SG_ APP_w002_ldwDisabled: 1|1@1+ (1,0) [0|0] "" X
 SG_ APP_w003_isaDisabled: 2|1@1+ (1,0) [0|0] "" X
 SG_ APP_w004_accDisabled: 3|1@1+ (1,0) [0|0] "" X
 SG_ APP_w005_fcwCancelled: 4|1@1+ (1,0) [0|0] "" X
 SG_ APP_w006_aebCancelled: 5|1@1+ (1,0) [0|0] "" X
 SG_ APP_w007_ahlbDisabled: 6|1@1+ (1,0) [0|0] "" X
 SG_ APP_w008_parkDisabled: 7|1@1+ (1,0) [0|0] "" X
 SG_ APP_w009_aebFault: 8|1@1+ (1,0) [0|0] "" X
 SG_ APP_w010_radcCalibIssue: 9|1@1+ (1,0) [0|0] "" X
 SG_ APP_w011_scaEvent: 10|1@1+ (1,0) [0|0] "" X
 SG_ APP_w012_Cam_BootFailure: 11|1@1+ (1,0) [0|0] "" X
 SG_ APP_w013_Cam_Watchdog: 12|1@1+ (1,0) [0|0] "" X
 SG_ APP_w014_swAssert: 13|1@1+ (1,0) [0|0] "" X
 SG_ APP_w015_Camera_Failsafes: 14|1@1+ (1,0) [0|0] "" X
 SG_ APP_w016_aeb_e_event: 15|1@1+ (1,0) [0|0] "" X
 SG_ APP_w017_Cam_Msg_MIA: 16|1@1+ (1,0) [0|0] "" X
 SG_ APP_w018_ECU_Power_Issue: 17|1@1+ (1,0) [0|0] "" X
 SG_ APP_w019_ECU_Stack_Overflow: 18|1@1+ (1,0) [0|0] "" X
 SG_ APP_w020_ECU_checkstopError: 19|1@1+ (1,0) [0|0] "" X
 SG_ APP_w021_ECU_Temperature_Issue: 20|1@1+ (1,0) [0|0] "" X
 SG_ APP_w022_ECU_EEPROM_Failure: 21|1@1+ (1,0) [0|0] "" X
 SG_ APP_w023_ECU_Cam_Statemismatc: 22|1@1+ (1,0) [0|0] "" X
 SG_ APP_w024_ECU_Watchdog_Reset: 23|1@1+ (1,0) [0|0] "" X
 SG_ APP_w025_LC_Steering_Override: 24|1@1+ (1,0) [0|0] "" X
 SG_ APP_w026_ECU_timingIssue: 25|1@1+ (1,0) [0|0] "" X
 SG_ APP_w027_ECU_Reset_Fault: 26|1@1+ (1,0) [0|0] "" X
 SG_ APP_w028_spi_rx_error: 27|1@1+ (1,0) [0|0] "" X
 SG_ APP_w029_spi_tx_error: 28|1@1+ (1,0) [0|0] "" X
 SG_ APP_w030_Heater_Issue: 29|1@1+ (1,0) [0|0] "" X
 SG_ APP_w031_canRxError: 30|1@1+ (1,0) [0|0] "" X
 SG_ APP_w032_canTxError: 31|1@1+ (1,0) [0|0] "" X
 SG_ APP_w033_gtwMia: 32|1@1+ (1,0) [0|0] "" X
 SG_ APP_w034_sccmMia: 33|1@1+ (1,0) [0|0] "" X
 SG_ APP_w035_espMia: 34|1@1+ (1,0) [0|0] "" X
 SG_ APP_w036_bdyMia: 35|1@1+ (1,0) [0|0] "" X
 SG_ APP_w037_camTacIssue: 36|1@1+ (1,0) [0|0] "" X
 SG_ APP_w038_camFailure: 37|1@1+ (1,0) [0|0] "" X
 SG_ APP_w039_sdm_rcm_Mia: 38|1@1+ (1,0) [0|0] "" X
 SG_ APP_w040_autopilotAngleSaturated: 39|1@1+ (1,0) [0|0] "" X
 SG_ APP_w041_autopilotRateSaturated: 40|1@1+ (1,0) [0|0] "" X
 SG_ APP_w042_autopilotAborting: 41|1@1+ (1,0) [0|0] "" X
 SG_ APP_w043_camLongRunTime: 42|1@1+ (1,0) [0|0] "" X
 SG_ APP_w044_appMobileyeFailure: 43|1@1+ (1,0) [0|0] "" X
 SG_ APP_w045_radMia: 44|1@1+ (1,0) [0|0] "" X
 SG_ APP_w046_eepromRecordAbsent: 45|1@1+ (1,0) [0|0] "" X
 SG_ APP_w047_edrEvent: 46|1@1+ (1,0) [0|0] "" X
 SG_ APP_w048_APP_Features_Disabled: 47|1@1+ (1,0) [0|0] "" X
 SG_ APP_w049_eyeqVersionMismatch: 48|1@1+ (1,0) [0|0] "" X
 SG_ APP_w050_aeb_event: 49|1@1+ (1,0) [0|0] "" X
 SG_ APP_w051_radcEcuIssue: 50|1@1+ (1,0) [0|0] "" X
 SG_ APP_w052_radcSensorIssue: 51|1@1+ (1,0) [0|0] "" X
 SG_ APP_w053_radcCommIssue: 52|1@1+ (1,0) [0|0] "" X
 SG_ APP_w054_camAutofix: 53|1@1+ (1,0) [0|0] "" X
 SG_ APP_w055_radcVersionMismatch: 54|1@1+ (1,0) [0|0] "" X
 SG_ APP_w056_diMia: 55|1@1+ (1,0) [0|0] "" X
 SG_ APP_w057_mcuMia: 56|1@1+ (1,0) [0|0] "" X
 SG_ APP_w058_epbMia: 57|1@1+ (1,0) [0|0] "" X
 SG_ APP_w059_parkMia: 58|1@1+ (1,0) [0|0] "" X
 SG_ APP_w060_fcw_event: 59|1@1+ (1,0) [0|0] "" X
 SG_ APP_w061_airSuspensionMia: 60|1@1+ (1,0) [0|0] "" X
 SG_ APP_w062_radcAlignment: 61|1@1+ (1,0) [0|0] "" X
 SG_ APP_w063_parkVersionMismatch: 62|1@1+ (1,0) [0|0] "" X
 SG_ APP_w064_epasMia: 63|1@1+ (1,0) [0|0] "" X

BO_ 873 APP_warningMatrix1: 8 CH
 SG_ APP_w065_deserializerOvercurrent: 0|1@1+ (1,0) [0|0] "" X
 SG_ APP_w066_deserializerLockLost: 1|1@1+ (1,0) [0|0] "" X
 SG_ APP_w067_steeringAlignment: 2|1@1+ (1,0) [0|0] "" X
 SG_ APP_w068_vlInconsistency: 3|1@1+ (1,0) [0|0] "" X
 SG_ APP_w069_apcSpaceMasked: 4|1@1+ (1,0) [0|0] "" X
 SG_ APP_w070_apcIncompleteCal: 5|1@1+ (1,0) [0|0] "" X
 SG_ APP_w071_selfparkStarted: 6|1@1+ (1,0) [0|0] "" X
 SG_ APP_w072_selfparkComplete: 7|1@1+ (1,0) [0|0] "" X
 SG_ APP_w073_issueEscalatedLDW: 8|1@1+ (1,0) [0|0] "" X
 SG_ APP_w074_inPathStationaryObst: 9|1@1+ (1,0) [0|0] "" X
 SG_ APP_w075_scMia: 10|1@1+ (1,0) [0|0] "" X
 SG_ APP_w076_mobilEyeSetC: 11|1@1+ (1,0) [0|0] "" X
 SG_ APP_w077_pmmActive: 12|1@1+ (1,0) [0|0] "" X
 SG_ APP_w078_pmmActive2: 13|1@1+ (1,0) [0|0] "" X
 SG_ APP_w079_edrAvailable: 14|1@1+ (1,0) [0|0] "" X
 SG_ APP_w080_accFailedActivation: 15|1@1+ (1,0) [0|0] "" X
 SG_ APP_w081_pmmActiveBraking: 16|1@1+ (1,0) [0|0] "" X
 SG_ APP_w082_inPathFSviolation: 17|1@1+ (1,0) [0|0] "" X
 SG_ APP_w083_inPathRADObject: 18|1@1+ (1,0) [0|0] "" X
 SG_ APP_w084_pmmIPSO: 19|1@1+ (1,0) [0|0] "" X
 SG_ APP_w085_pmmSteering: 20|1@1+ (1,0) [0|0] "" X
 SG_ APP_w086_robCollision: 21|1@1+ (1,0) [0|0] "" X
 SG_ APP_w087_DEPRECATED: 22|1@1+ (1,0) [0|0] "" X
 SG_ APP_w088_DEPRECATED: 23|1@1+ (1,0) [0|0] "" X
 SG_ APP_w089_DEPRECATED: 24|1@1+ (1,0) [0|0] "" X
 SG_ APP_w090_DEPRECATED: 25|1@1+ (1,0) [0|0] "" X
 SG_ APP_w091_DEPRECATED: 26|1@1+ (1,0) [0|0] "" X
 SG_ APP_w092_DEPRECATED: 27|1@1+ (1,0) [0|0] "" X
 SG_ APP_w093_DEPRECATED: 28|1@1+ (1,0) [0|0] "" X
 SG_ APP_w094_DEPRECATED: 29|1@1+ (1,0) [0|0] "" X
 SG_ APP_w095_DEPRECATED: 30|1@1+ (1,0) [0|0] "" X
 SG_ APP_w096_DEPRECATED: 31|1@1+ (1,0) [0|0] "" X
 SG_ APP_w097_DEPRECATED: 32|1@1+ (1,0) [0|0] "" X
 SG_ APP_w098_DEPRECATED: 33|1@1+ (1,0) [0|0] "" X
 SG_ APP_w099_DEPRECATED: 34|1@1+ (1,0) [0|0] "" X
 SG_ APP_w100_DEPRECATED: 35|1@1+ (1,0) [0|0] "" X
 SG_ APP_w101_DEPRECATED: 36|1@1+ (1,0) [0|0] "" X
 SG_ APP_w102_DEPRECATED: 37|1@1+ (1,0) [0|0] "" X
 SG_ APP_w103_robExperimentalAEB: 38|1@1+ (1,0) [0|0] "" X
 SG_ APP_w104_DEPRECATED: 39|1@1+ (1,0) [0|0] "" X
 SG_ APP_w105_DEPRECATED: 40|1@1+ (1,0) [0|0] "" X
 SG_ APP_w106_torsionBarOffset: 41|1@1+ (1,0) [0|0] "" X

BO_ 1065 APP_warningMatrix2: 8 CH
 SG_ APP_w129_mainCamExtNotCal: 0|1@1+ (1,0) [0|0] "" X
 SG_ APP_w130_narrowCamExtNotCal: 1|1@1+ (1,0) [0|0] "" X
 SG_ APP_w131_mainCamCalSaved: 2|1@1+ (1,0) [0|0] "" X
 SG_ APP_w132_narrowCamCalSaved: 3|1@1+ (1,0) [0|0] "" X
 SG_ APP_w133_mainCamInitFault: 4|1@1+ (1,0) [0|0] "" X
 SG_ APP_w134_narrowCamInitFault: 5|1@1+ (1,0) [0|0] "" X
 SG_ APP_w135_fisheyeCamInitFault: 6|1@1+ (1,0) [0|0] "" X
 SG_ APP_w136_lPillarCamInitFault: 7|1@1+ (1,0) [0|0] "" X
 SG_ APP_w137_rPillarCamInitFault: 8|1@1+ (1,0) [0|0] "" X
 SG_ APP_w138_lRepeatCamInitFault: 9|1@1+ (1,0) [0|0] "" X
 SG_ APP_w139_rRepeatCamInitFault: 10|1@1+ (1,0) [0|0] "" X
 SG_ APP_w140_backupCamInitFault: 11|1@1+ (1,0) [0|0] "" X
 SG_ APP_w141_ECU_Thermal_Issue: 12|1@1+ (1,0) [0|0] "" X
 SG_ APP_w142_fwdCamPitchProblem: 13|1@1+ (1,0) [0|0] "" X
 SG_ APP_w143_IDF_event: 14|1@1+ (1,0) [0|0] "" X
 SG_ APP_w144_fanctrldError: 15|1@1+ (1,0) [0|0] "" X
 SG_ APP_w145_camSelfCalIssue: 16|1@1+ (1,0) [0|0] "" X
 SG_ APP_w146_telemetryProblem: 17|1@1+ (1,0) [0|0] "" X
 SG_ APP_w147_selfieCamInitFault: 18|1@1+ (1,0) [0|0] "" X
 SG_ APP_w148_overlayActive: 19|1@1+ (1,0) [0|0] "" X
 SG_ APP_w149_diskFull: 20|1@1+ (1,0) [0|0] "" X
 SG_ APP_w150_diMiaPartyBus: 21|1@1+ (1,0) [0|0] "" X
 SG_ APP_w151_epasMiaPartyBus: 22|1@1+ (1,0) [0|0] "" X
 SG_ APP_w152_espMiaPartyBus: 23|1@1+ (1,0) [0|0] "" X
 SG_ APP_w153_rcmMiaPartyBus: 24|1@1+ (1,0) [0|0] "" X
 SG_ APP_w154_vcleftMiaPartyBus: 25|1@1+ (1,0) [0|0] "" X
 SG_ APP_w155_vcrightMiaPartyBus: 26|1@1+ (1,0) [0|0] "" X
 SG_ APP_w156_epblMiaVehBus: 27|1@1+ (1,0) [0|0] "" X
 SG_ APP_w157_sccmMiaVehBus: 28|1@1+ (1,0) [0|0] "" X
 SG_ APP_w158_vcfrontMiaVehBus: 29|1@1+ (1,0) [0|0] "" X
 SG_ APP_w159_vcleftMiaVehBus: 30|1@1+ (1,0) [0|0] "" X
 SG_ APP_w160_vcrightMiaVehBus: 31|1@1+ (1,0) [0|0] "" X
 SG_ APP_w161_backupCameraUnavailable: 32|1@1+ (1,0) [0|0] "" X
 SG_ APP_w162_mainCameraTypeError: 33|1@1+ (1,0) [0|0] "" X
 SG_ APP_w163_narrowCameraTypeError: 34|1@1+ (1,0) [0|0] "" X
 SG_ APP_w164_fisheyeCameraTypeError: 35|1@1+ (1,0) [0|0] "" X
 SG_ APP_w165_lPillarCameraTypeError: 36|1@1+ (1,0) [0|0] "" X
 SG_ APP_w166_rPillarCameraTypeError: 37|1@1+ (1,0) [0|0] "" X
 SG_ APP_w167_lRepeatCameraTypeError: 38|1@1+ (1,0) [0|0] "" X
 SG_ APP_w168_rRepeatCameraTypeError: 39|1@1+ (1,0) [0|0] "" X
 SG_ APP_w169_backupCameraTypeError: 40|1@1+ (1,0) [0|0] "" X
 SG_ APP_w170_selfieCameraTypeError: 41|1@1+ (1,0) [0|0] "" X
 SG_ APP_w171_appHighCoolantFlowReq: 42|1@1+ (1,0) [0|0] "" X
 SG_ APP_w172_fisheyeCamExtNotCal: 43|1@1+ (1,0) [0|0] "" X
 SG_ APP_w173_lPillarCamExtNotCal: 44|1@1+ (1,0) [0|0] "" X
 SG_ APP_w174_rPillarCamExtNotCal: 45|1@1+ (1,0) [0|0] "" X
 SG_ APP_w175_lRepeatCamExtNotCal: 46|1@1+ (1,0) [0|0] "" X
 SG_ APP_w176_rRepeatCamExtNotCal: 47|1@1+ (1,0) [0|0] "" X
 SG_ APP_w177_fisheyeCamCalSaved: 48|1@1+ (1,0) [0|0] "" X
 SG_ APP_w178_lPillarCamCalSaved: 49|1@1+ (1,0) [0|0] "" X
 SG_ APP_w179_rPillarCamCalSaved: 50|1@1+ (1,0) [0|0] "" X
 SG_ APP_w180_lRepeatCamCalSaved: 51|1@1+ (1,0) [0|0] "" X
 SG_ APP_w181_rRepeatCamCalSaved: 52|1@1+ (1,0) [0|0] "" X
 SG_ APP_w182_mainCameraStreamExit: 53|1@1+ (1,0) [0|0] "" X
 SG_ APP_w183_narrowCameraStreamExit: 54|1@1+ (1,0) [0|0] "" X
 SG_ APP_w184_fisheyeCameraStreamExit: 55|1@1+ (1,0) [0|0] "" X
 SG_ APP_w185_lPillarCameraStreamExit: 56|1@1+ (1,0) [0|0] "" X
 SG_ APP_w186_rPillarCameraStreamExit: 57|1@1+ (1,0) [0|0] "" X
 SG_ APP_w187_lRepeatCameraStreamExit: 58|1@1+ (1,0) [0|0] "" X
 SG_ APP_w188_rRepeatCameraStreamExit: 59|1@1+ (1,0) [0|0] "" X
 SG_ APP_w189_backupCameraStreamExit: 60|1@1+ (1,0) [0|0] "" X
 SG_ APP_w190_selfieCameraStreamExit: 61|1@1+ (1,0) [0|0] "" X
 SG_ APP_w191_autopilotAborting: 62|1@1+ (1,0) [0|0] "" X
 SG_ APP_w192_emergencySpeakerFail: 63|1@1+ (1,0) [0|0] "" X

BO_ 1081 APP_warningMatrix3: 8 CH
 SG_ APP_w193_camWindshieldUnclean: 0|1@1+ (1,0) [0|0] "" X
 SG_ APP_w194_accDriverResumeRqrd: 1|1@1+ (1,0) [0|0] "" X
 SG_ APP_w195_scwUnavailable: 2|1@1+ (1,0) [0|0] "" X
 SG_ APP_w196_stopSignWarning: 3|1@1+ (1,0) [0|0] "" X
 SG_ APP_w197_redLightWarning: 4|1@1+ (1,0) [0|0] "" X
 SG_ APP_w198_tsrUnavailable: 5|1@1+ (1,0) [0|0] "" X
 SG_ APP_w199_apcAbort: 6|1@1+ (1,0) [0|0] "" X
 SG_ APP_w200_lcSlowdown: 7|1@1+ (1,0) [0|0] "" X
 SG_ APP_w201_lcAborting: 8|1@1+ (1,0) [0|0] "" X
 SG_ APP_w202_scwNoisyEnvironment: 9|1@1+ (1,0) [0|0] "" X
 SG_ APP_w203_apcActivation: 10|1@1+ (1,0) [0|0] "" X
 SG_ APP_w204_apcFinalFront: 11|1@1+ (1,0) [0|0] "" X
 SG_ APP_w205_apcFinalRear: 12|1@1+ (1,0) [0|0] "" X
 SG_ APP_w206_autosteerNotEnabled: 13|1@1+ (1,0) [0|0] "" X
 SG_ APP_w207_autosteerUnavailable: 14|1@1+ (1,0) [0|0] "" X
 SG_ APP_w208_rackDetected: 15|1@1+ (1,0) [0|0] "" X
 SG_ APP_w209_autoSummonRequest: 16|1@1+ (1,0) [0|0] "" X
 SG_ APP_w210_camObstrcted: 17|1@1+ (1,0) [0|0] "" X
 SG_ APP_w211_accNoSeatBelt: 18|1@1+ (1,0) [0|0] "" X
 SG_ APP_w212_lcUnavailableStrikeOut: 19|1@1+ (1,0) [0|0] "" X
 SG_ APP_w213_autosteerStruckOut: 20|1@1+ (1,0) [0|0] "" X
 SG_ APP_w214_driverNotIntracting: 21|1@1+ (1,0) [0|0] "" X
 SG_ APP_w215_contDriverNotIntracting: 22|1@1+ (1,0) [0|0] "" X
 SG_ APP_w216_driverOverriding: 23|1@1+ (1,0) [0|0] "" X
 SG_ APP_w217_lcUnavailableSpeeding: 24|1@1+ (1,0) [0|0] "" X
 SG_ APP_w218_lcSpeedExceededLimit: 25|1@1+ (1,0) [0|0] "" X
 SG_ APP_w219_lcTempUnavailableSpeed: 26|1@1+ (1,0) [0|0] "" X
 SG_ APP_w220_lcTempUnavailableRoad: 27|1@1+ (1,0) [0|0] "" X
 SG_ APP_w221_accRadarBlind: 28|1@1+ (1,0) [0|0] "" X
 SG_ APP_w222_accCameraBlind: 29|1@1+ (1,0) [0|0] "" X
 SG_ APP_w223_accObjectInPath: 30|1@1+ (1,0) [0|0] "" X
 SG_ APP_w224_accCameraCalibration: 31|1@1+ (1,0) [0|0] "" X
 SG_ APP_w225_lcDegradedVisSpeedLmt: 32|1@1+ (1,0) [0|0] "" X
 SG_ APP_w226_lcCamCalNeededSpeedLmt: 33|1@1+ (1,0) [0|0] "" X
 SG_ APP_w227_virtualWallBlocked: 34|1@1+ (1,0) [0|0] "" X
 SG_ APP_w228_DEPRECATED: 35|1@1+ (1,0) [0|0] "" X
 SG_ APP_w229_alcUltrasoundDamaged: 36|1@1+ (1,0) [0|0] "" X
 SG_ APP_w230_alcUltrasoundBlocked: 37|1@1+ (1,0) [0|0] "" X

BO_ 1097 APP_warningMatrix4: 8 CH
 SG_ APP_w257_brakeJerkEvent: 0|1@1+ (1,0) [0|0] "" X
 SG_ APP_w258_aebEvent: 1|1@1+ (1,0) [0|0] "" X
 SG_ APP_w259_aebOverrideEvent: 2|1@1+ (1,0) [0|0] "" X
 SG_ APP_w260_collisionWarningEvent: 3|1@1+ (1,0) [0|0] "" X
 SG_ APP_w261_pcieHardwareErrors: 4|1@1+ (1,0) [0|0] "" X
 SG_ APP_w262_apeCalibMode: 5|1@1+ (1,0) [0|0] "" X
 SG_ APP_w263_lssAbort: 6|1@1+ (1,0) [0|0] "" X
 SG_ APP_w264_lssFault: 7|1@1+ (1,0) [0|0] "" X
 SG_ APP_w265_drvOnNavUnavailable: 8|1@1+ (1,0) [0|0] "" X
 SG_ APP_w266_visionScheduleFallback: 9|1@1+ (1,0) [0|0] "" X
 SG_ APP_w267_benchtopEcu: 10|1@1+ (1,0) [0|0] "" X
 SG_ APP_w268_backupCamExtNotCal: 11|1@1+ (1,0) [0|0] "" X
 SG_ APP_w269_autopilotLimited: 12|1@1+ (1,0) [0|0] "" X
 SG_ APP_w270_blindspotRestricted: 13|1@1+ (1,0) [0|0] "" X
 SG_ APP_w271_laneChangeAborted: 14|1@1+ (1,0) [0|0] "" X

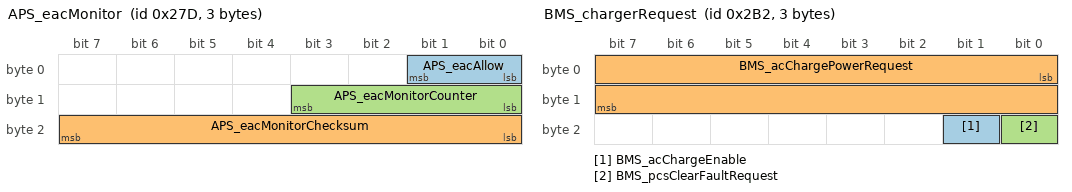
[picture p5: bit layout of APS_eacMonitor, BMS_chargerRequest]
BO_ 637 APS_eacMonitor: 3 VEH
 SG_ APS_eacAllow: 0|2@1+ (1,0) [0|0] "" X
 SG_ APS_eacMonitorChecksum: 16|8@1+ (1,0) [0|0] "" X
 SG_ APS_eacMonitorCounter: 8|4@1+ (1,0) [0|0] "" X

BO_ 970 DAS_gpsStatus: 8 Vector__XXX
 SG_ DAS_gpsRawxEnabled m0 : 62|1@1+ (1,0) [0|0] "" Vector__XXX
 SG_ DAS_gpsNmeaDispatchFailureCount m1 : 60|4@1+ (5,0) [0|0] "" Vector__XXX
 SG_ DAS_gpsFixTypeHardware m0 : 59|3@1+ (1,0) [0|0] "" Vector__XXX
 SG_ DAS_gnssAvgInstantaneousCnorBdsLowBand m3 : 58|6@1+ (1,0) [0|0] "" Vector__XXX
 SG_ DAS_gpsWheelsOffMotionDetected m0 : 58|1@1+ (1,0) [0|0] "" Vector__XXX
 SG_ DAS_gpsRejectingSatData m0 : 57|1@1+ (1,0) [0|0] "" Vector__XXX
 SG_ DAS_gpsPreviousPositionDeltaSw m1 : 54|6@1+ (3,0) [0|0] "" Vector__XXX
 SG_ DAS_gnssAvgInstantaneousCnorGalLowBand m3 : 52|6@1+ (1,0) [0|0] "" Vector__XXX
 SG_ DAS_gpsPreviousPositionDeltaHw m1 : 48|6@1+ (3,0) [0|0] "" Vector__XXX
 SG_ DAS_gpsSatsInUseSoftwareSocB m2 : 48|4@1+ (1,0) [0|0] "" Vector__XXX
 SG_ DAS_gnssAvgInstantaneousCnorGpsLowBand m3 : 46|6@1+ (1,0) [0|0] "" Vector__XXX
 SG_ DAS_gpsFixTypeSoftwareSocB m2 : 45|3@1+ (1,0) [0|0] "" Vector__XXX
 SG_ DAS_gpsRedundancyActive m2 : 44|1@1+ (1,0) [0|0] "" Vector__XXX
 SG_ DAS_gpsSolutionSoc m2 : 42|2@1+ (1,0) [0|0] "" Vector__XXX
 SG_ DAS_gnssAvgInstantCnorBdsSocB m3 : 40|6@1+ (1,0) [0|0] "" Vector__XXX
 SG_ DAS_gpsAutomaticGainControl m1 : 40|8@1+ (32,0) [0|0] "" Vector__XXX
 SG_ DAS_gpsToMcuSource m2 : 39|3@1+ (1,0) [0|0] "" Vector__XXX
 SG_ DAS_gpsSolutionFallback m2 : 38|1@1+ (1,0) [0|0] "" Vector__XXX
 SG_ DAS_gnssAvgInstantCnorGpsSocB m3 : 34|6@1+ (1,0) [0|0] "" Vector__XXX
 SG_ DAS_gpsReceiverNoiseLevel m1 : 34|6@1+ (8,0) [0|0] "" Vector__XXX
 SG_ DAS_gnssConstellationsState m1 : 32|2@1+ (1,0) [0|0] "" Vector__XXX
 SG_ DAS_gpsAccuracyVertical m2 : 32|6@1+ (1,0) [0|0] "" Vector__XXX
 SG_ DAS_gnssAvgInstantaneousCnorBds m3 : 28|6@1+ (1,0) [0|0] "" Vector__XXX
 SG_ DAS_gpsInvalidMsgPercentage m1 : 28|4@1+ (6,0) [0|0] "" Vector__XXX
 SG_ DAS_gpsAccuracyHorizontal m2 : 26|6@1+ (1,0) [0|0] "" Vector__XXX
 SG_ DAS_gpsSpoofDetectorState m1 : 26|2@1+ (1,0) [0|0] "" Vector__XXX
 SG_ DAS_gpsWheeltickPulsePeriod m0 : 25|32@1+ (1,0) [0|0] "" Vector__XXX
 SG_ DAS_gpsJammingState m1 : 24|2@1+ (1,0) [0|0] "" Vector__XXX
 SG_ DAS_gnssAvgInstantaneousCnorGal m3 : 22|6@1+ (1,0) [0|0] "" Vector__XXX
 SG_ DAS_gpsResetReason m2 : 22|4@1+ (1,0) [0|0] "" Vector__XXX
 SG_ DAS_gpsCWJammingInidcator m1 : 19|5@1+ (8,0) [0|0] "" Vector__XXX
 SG_ DAS_gnssAvgInstantaneousCnorGps m3 : 16|6@1+ (1,0) [0|0] "" Vector__XXX
 SG_ DAS_gnssMaxInstantaneousCnorBds m2 : 16|6@1+ (1,0) [0|0] "" Vector__XXX
 SG_ DAS_gpsFixTypeSoftware m1 : 16|3@1+ (1,0) [0|0] "" Vector__XXX
 SG_ DAS_gnssNumSatsBds m3 : 12|4@1+ (1,0) [0|0] "" Vector__XXX
 SG_ DAS_gpsSatsInUseSoftware m1 : 12|4@1+ (1,0) [0|0] "" Vector__XXX
 SG_ DAS_gpsSoftwareFastStartReady m1 : 11|1@1+ (1,0) [0|0] "" Vector__XXX
 SG_ DAS_gnssMaxInstantaneousCnorGal m2 : 10|6@1+ (1,0) [0|0] "" Vector__XXX
 SG_ DAS_gpsSoftwareUsed m1 : 10|1@1+ (1,0) [0|0] "" Vector__XXX
 SG_ DAS_gpsSoftwareConfigured m1 : 9|1@1+ (1,0) [0|0] "" Vector__XXX
 SG_ DAS_gpsWheeltickCounter m0 : 9|16@1+ (1,0) [0|0] "" Vector__XXX
 SG_ DAS_gnssNumSatsGal m3 : 8|4@1+ (1,0) [0|0] "" Vector__XXX
 SG_ DAS_gpsNavStatusMia m1 : 8|1@1+ (1,0) [0|0] "" Vector__XXX
 SG_ DAS_gpsEsfRawMia m1 : 7|1@1+ (1,0) [0|0] "" Vector__XXX
 SG_ DAS_gpsEsfMeasMia m1 : 6|1@1+ (1,0) [0|0] "" Vector__XXX
 SG_ DAS_gpsRxmSfrbxMia m1 : 5|1@1+ (1,0) [0|0] "" Vector__XXX
 SG_ DAS_gpsSatsInUseHardware m0 : 5|4@1+ (1,0) [0|0] "" Vector__XXX
 SG_ DAS_gnssMaxInstantaneousCnorGps m2 : 4|6@1+ (1,0) [0|0] "" Vector__XXX
 SG_ DAS_gnssNumSatsGps m3 : 4|4@1+ (1,0) [0|0] "" Vector__XXX
 SG_ DAS_gpsRxmRawxMia m1 : 4|1@1+ (1,0) [0|0] "" Vector__XXX
 SG_ DAS_gpsTransportModeState m0 : 4|1@1+ (1,0) [0|0] "" Vector__XXX
 SG_ DAS_gpsStatusMultiplexer M : 0|4@1+ (1,0) [0|0] "" Vector__XXX

BO_ 811 APS_warningMatrix0: 8 CH
 SG_ APS_w001_DEPRECATED: 0|1@1+ (1,0) [0|0] "" X
 SG_ APS_w002_ldwDisabled: 1|1@1+ (1,0) [0|0] "" X
 SG_ APS_w003_isaDisabled: 2|1@1+ (1,0) [0|0] "" X
 SG_ APS_w004_accDisabled: 3|1@1+ (1,0) [0|0] "" X
 SG_ APS_w005_fcwCancelled: 4|1@1+ (1,0) [0|0] "" X
 SG_ APS_w006_aebCancelled: 5|1@1+ (1,0) [0|0] "" X
 SG_ APS_w007_ahlbDisabled: 6|1@1+ (1,0) [0|0] "" X
 SG_ APS_w008_parkDisabled: 7|1@1+ (1,0) [0|0] "" X
 SG_ APS_w009_aebFault: 8|1@1+ (1,0) [0|0] "" X
 SG_ APS_w010_radcCalibIssue: 9|1@1+ (1,0) [0|0] "" X
 SG_ APS_w011_scaEvent: 10|1@1+ (1,0) [0|0] "" X
 SG_ APS_w012_Cam_BootFailure: 11|1@1+ (1,0) [0|0] "" X
 SG_ APS_w013_Cam_Watchdog: 12|1@1+ (1,0) [0|0] "" X
 SG_ APS_w014_swAssert: 13|1@1+ (1,0) [0|0] "" X
 SG_ APS_w015_Camera_Failsafes: 14|1@1+ (1,0) [0|0] "" X
 SG_ APS_w016_aeb_e_event: 15|1@1+ (1,0) [0|0] "" X
 SG_ APS_w017_Cam_Msg_MIA: 16|1@1+ (1,0) [0|0] "" X
 SG_ APS_w018_ECU_Power_Issue: 17|1@1+ (1,0) [0|0] "" X
 SG_ APS_w019_ECU_Stack_Overflow: 18|1@1+ (1,0) [0|0] "" X
 SG_ APS_w020_ECU_checkstopError: 19|1@1+ (1,0) [0|0] "" X
 SG_ APS_w021_ECU_Temperature_Issue: 20|1@1+ (1,0) [0|0] "" X
 SG_ APS_w022_ECU_EEPROM_Failure: 21|1@1+ (1,0) [0|0] "" X
 SG_ APS_w023_ECU_Cam_Statemismatc: 22|1@1+ (1,0) [0|0] "" X
 SG_ APS_w024_ECU_Watchdog_Reset: 23|1@1+ (1,0) [0|0] "" X
 SG_ APS_w025_LC_Steering_Override: 24|1@1+ (1,0) [0|0] "" X
 SG_ APS_w026_ECU_timingIssue: 25|1@1+ (1,0) [0|0] "" X
 SG_ APS_w027_ECU_Reset_Fault: 26|1@1+ (1,0) [0|0] "" X
 SG_ APS_w028_spi_rx_error: 27|1@1+ (1,0) [0|0] "" X
 SG_ APS_w029_spi_tx_error: 28|1@1+ (1,0) [0|0] "" X
 SG_ APS_w030_Heater_Issue: 29|1@1+ (1,0) [0|0] "" X
 SG_ APS_w031_canRxError: 30|1@1+ (1,0) [0|0] "" X
 SG_ APS_w032_canTxError: 31|1@1+ (1,0) [0|0] "" X
 SG_ APS_w033_gtwMia: 32|1@1+ (1,0) [0|0] "" X
 SG_ APS_w034_sccmMia: 33|1@1+ (1,0) [0|0] "" X
 SG_ APS_w035_espMia: 34|1@1+ (1,0) [0|0] "" X
 SG_ APS_w036_bdyMia: 35|1@1+ (1,0) [0|0] "" X
 SG_ APS_w037_camTacIssue: 36|1@1+ (1,0) [0|0] "" X
 SG_ APS_w038_camFailure: 37|1@1+ (1,0) [0|0] "" X
 SG_ APS_w039_sdm_rcm_Mia: 38|1@1+ (1,0) [0|0] "" X
 SG_ APS_w040_autopilotAngleSaturated: 39|1@1+ (1,0) [0|0] "" X
 SG_ APS_w041_autopilotRateSaturated: 40|1@1+ (1,0) [0|0] "" X
 SG_ APS_w042_autopilotAborting: 41|1@1+ (1,0) [0|0] "" X
 SG_ APS_w043_camLongRunTime: 42|1@1+ (1,0) [0|0] "" X
 SG_ APS_w044_appMobileyeFailure: 43|1@1+ (1,0) [0|0] "" X
 SG_ APS_w045_radMia: 44|1@1+ (1,0) [0|0] "" X
 SG_ APS_w046_eepromRecordAbsent: 45|1@1+ (1,0) [0|0] "" X
 SG_ APS_w047_edrEvent: 46|1@1+ (1,0) [0|0] "" X
 SG_ APS_w048_DAS_Features_Disabled: 47|1@1+ (1,0) [0|0] "" X
 SG_ APS_w049_eyeqVersionMismatch: 48|1@1+ (1,0) [0|0] "" X
 SG_ APS_w050_aeb_event: 49|1@1+ (1,0) [0|0] "" X
 SG_ APS_w051_radcEcuIssue: 50|1@1+ (1,0) [0|0] "" X
 SG_ APS_w052_radcSensorIssue: 51|1@1+ (1,0) [0|0] "" X
 SG_ APS_w053_radcCommIssue: 52|1@1+ (1,0) [0|0] "" X
 SG_ APS_w054_camAutofix: 53|1@1+ (1,0) [0|0] "" X
 SG_ APS_w055_radcVersionMismatch: 54|1@1+ (1,0) [0|0] "" X
 SG_ APS_w056_diMia: 55|1@1+ (1,0) [0|0] "" X
 SG_ APS_w057_mcuMia: 56|1@1+ (1,0) [0|0] "" X
 SG_ APS_w058_epbMia: 57|1@1+ (1,0) [0|0] "" X
 SG_ APS_w059_parkMia: 58|1@1+ (1,0) [0|0] "" X
 SG_ APS_w060_fcw_event: 59|1@1+ (1,0) [0|0] "" X
 SG_ APS_w061_tasMia: 60|1@1+ (1,0) [0|0] "" X
 SG_ APS_w062_radcAlignment: 61|1@1+ (1,0) [0|0] "" X
 SG_ APS_w063_parkVersionMismatch: 62|1@1+ (1,0) [0|0] "" X
 SG_ APS_w064_epasMia: 63|1@1+ (1,0) [0|0] "" X

BO_ 876 APS_warningMatrix1: 8 CH
 SG_ APS_w065_deserializerOvercurrent: 0|1@1+ (1,0) [0|0] "" X
 SG_ APS_w066_deserializerLockLost: 1|1@1+ (1,0) [0|0] "" X
 SG_ APS_w067_steeringAlignment: 2|1@1+ (1,0) [0|0] "" X
 SG_ APS_w068_vlInconsistency: 3|1@1+ (1,0) [0|0] "" X
 SG_ APS_w069_apcSpaceMasked: 4|1@1+ (1,0) [0|0] "" X
 SG_ APS_w070_apcIncompleteCal: 5|1@1+ (1,0) [0|0] "" X
 SG_ APS_w071_selfparkStarted: 6|1@1+ (1,0) [0|0] "" X
 SG_ APS_w072_selfparkComplete: 7|1@1+ (1,0) [0|0] "" X
 SG_ APS_w073_issueEscalatedLDW: 8|1@1+ (1,0) [0|0] "" X
 SG_ APS_w074_inPathStationaryObst: 9|1@1+ (1,0) [0|0] "" X
 SG_ APS_w075_scMia: 10|1@1+ (1,0) [0|0] "" X
 SG_ APS_w076_mobilEyeSetC: 11|1@1+ (1,0) [0|0] "" X
 SG_ APS_w077_pmmActive: 12|1@1+ (1,0) [0|0] "" X
 SG_ APS_w078_pmmActive2: 13|1@1+ (1,0) [0|0] "" X
 SG_ APS_w079_edrAvailable: 14|1@1+ (1,0) [0|0] "" X
 SG_ APS_w080_accFailedActivation: 15|1@1+ (1,0) [0|0] "" X
 SG_ APS_w081_pmmActiveBraking: 16|1@1+ (1,0) [0|0] "" X
 SG_ APS_w082_inPathFSviolation: 17|1@1+ (1,0) [0|0] "" X
 SG_ APS_w083_inPathRADObject: 18|1@1+ (1,0) [0|0] "" X
 SG_ APS_w084_pmmIPSO: 19|1@1+ (1,0) [0|0] "" X
 SG_ APS_w085_pmmSteering: 20|1@1+ (1,0) [0|0] "" X
 SG_ APS_w086_robCollision: 21|1@1+ (1,0) [0|0] "" X
 SG_ APS_w087_DEPRECATED: 22|1@1+ (1,0) [0|0] "" X
 SG_ APS_w088_DEPRECATED: 23|1@1+ (1,0) [0|0] "" X
 SG_ APS_w089_DEPRECATED: 24|1@1+ (1,0) [0|0] "" X
 SG_ APS_w090_DEPRECATED: 25|1@1+ (1,0) [0|0] "" X
 SG_ APS_w091_DEPRECATED: 26|1@1+ (1,0) [0|0] "" X
 SG_ APS_w092_DEPRECATED: 27|1@1+ (1,0) [0|0] "" X
 SG_ APS_w093_DEPRECATED: 28|1@1+ (1,0) [0|0] "" X
 SG_ APS_w094_DEPRECATED: 29|1@1+ (1,0) [0|0] "" X
 SG_ APS_w095_DEPRECATED: 30|1@1+ (1,0) [0|0] "" X
 SG_ APS_w096_DEPRECATED: 31|1@1+ (1,0) [0|0] "" X
 SG_ APS_w097_DEPRECATED: 32|1@1+ (1,0) [0|0] "" X
 SG_ APS_w098_DEPRECATED: 33|1@1+ (1,0) [0|0] "" X
 SG_ APS_w099_DEPRECATED: 34|1@1+ (1,0) [0|0] "" X
 SG_ APS_w100_DEPRECATED: 35|1@1+ (1,0) [0|0] "" X
 SG_ APS_w101_DEPRECATED: 36|1@1+ (1,0) [0|0] "" X
 SG_ APS_w102_DEPRECATED: 37|1@1+ (1,0) [0|0] "" X
 SG_ APS_w103_robExperimentalAEB: 38|1@1+ (1,0) [0|0] "" X
 SG_ APS_w104_DEPRECATED: 39|1@1+ (1,0) [0|0] "" X
 SG_ APS_w105_DEPRECATED: 40|1@1+ (1,0) [0|0] "" X
 SG_ APS_w106_torsionBarOffset: 41|1@1+ (1,0) [0|0] "" X

BO_ 1113 APS_warningMatrix2: 8 Vector__XXX
 SG_ APS_w192_CANFault : 63|1@1+ (1,0) [0|0] "" Vector__XXX
 SG_ APS_w191_timesyncError : 62|1@1+ (1,0) [0|0] "" Vector__XXX
 SG_ APS_w190_iboosterMia : 61|1@1+ (1,0) [0|0] "" Vector__XXX
 SG_ APS_w189_vcfrontMiaPartyBus : 60|1@1+ (1,0) [0|0] "" Vector__XXX
 SG_ APS_w188_otherTurboUartMIA : 59|1@1+ (1,0) [0|0] "" Vector__XXX
 SG_ APS_w187_TurboB_SMS_taskUtilErr : 58|1@1+ (1,0) [0|0] "" Vector__XXX
 SG_ APS_w186_TurboB_A72_watchdog : 57|1@1+ (1,0) [0|0] "" Vector__XXX
 SG_ APS_w185_TurboB_SCS_LKUP : 56|1@1+ (1,0) [0|0] "" Vector__XXX
 SG_ APS_w184_TurboB_SMS_WDOG : 55|1@1+ (1,0) [0|0] "" Vector__XXX
 SG_ APS_w183_TurboB_TMU_Throttle : 54|1@1+ (1,0) [0|0] "" Vector__XXX
 SG_ APS_w182_TurboB_SMSLockStepErr : 53|1@1+ (1,0) [0|0] "" Vector__XXX
 SG_ APS_w181_TurboB_Temp_NOS : 52|1@1+ (1,0) [0|0] "" Vector__XXX
 SG_ APS_w180_TurboB_12VFuseFault : 51|1@1+ (1,0) [0|0] "" Vector__XXX
 SG_ APS_w179_TurboB_DisRegNFault : 50|1@1+ (1,0) [0|0] "" Vector__XXX
 SG_ APS_w178_TurboB_DisRegPgoodErr : 49|1@1+ (1,0) [0|0] "" Vector__XXX
 SG_ APS_w172_apFeaturesUnavailable : 43|1@1+ (1,0) [0|0] "" Vector__XXX
 SG_ APS_w171_TurboA_SMS_taskUtilErr : 42|1@1+ (1,0) [0|0] "" Vector__XXX
 SG_ APS_w170_TurboA_A72_watchdog : 41|1@1+ (1,0) [0|0] "" Vector__XXX
 SG_ APS_w169_TurboA_SCS_LKUP : 40|1@1+ (1,0) [0|0] "" Vector__XXX
 SG_ APS_w168_TurboA_SMS_WDOG : 39|1@1+ (1,0) [0|0] "" Vector__XXX
 SG_ APS_w167_TurboA_TMU_Throttle : 38|1@1+ (1,0) [0|0] "" Vector__XXX
 SG_ APS_w166_TurboA_SMSLockStepErr : 37|1@1+ (1,0) [0|0] "" Vector__XXX
 SG_ APS_w165_TurboA_Temp_NOS : 36|1@1+ (1,0) [0|0] "" Vector__XXX
 SG_ APS_w164_TurboA_12VFuseFault : 35|1@1+ (1,0) [0|0] "" Vector__XXX
 SG_ APS_w163_TurboA_DisRegNFault : 34|1@1+ (1,0) [0|0] "" Vector__XXX
 SG_ APS_w162_TurboA_DisRegPgoodErr : 33|1@1+ (1,0) [0|0] "" Vector__XXX
 SG_ APS_w161_gpsAntennaDisconnected : 32|1@1+ (1,0) [0|0] "" Vector__XXX
 SG_ APS_w160_apbVersionMismatch : 31|1@1+ (1,0) [0|0] "" Vector__XXX
 SG_ APS_w159_apbCritical : 30|1@1+ (1,0) [0|0] "" Vector__XXX
 SG_ APS_w158_apbMia : 29|1@1+ (1,0) [0|0] "" Vector__XXX
 SG_ APS_w157_autopilotReboot : 28|1@1+ (1,0) [0|0] "" Vector__XXX
 SG_ APS_w156_lwipAssert : 27|1@1+ (1,0) [0|0] "" Vector__XXX
 SG_ APS_w155_ethLwipError : 26|1@1+ (1,0) [0|0] "" Vector__XXX
 SG_ APS_w153_eacInhibit : 24|1@1+ (1,0) [0|0] "" Vector__XXX
 SG_ APS_w152_gpsFusionStatus : 23|1@1+ (1,0) [0|0] "" Vector__XXX
 SG_ APS_w151_apRecovered : 22|1@1+ (1,0) [0|0] "" Vector__XXX
 SG_ APS_w150_sccmMiaVehBus : 21|1@1+ (1,0) [0|0] "" Vector__XXX
 SG_ APS_w149_epblMiaVehBus : 20|1@1+ (1,0) [0|0] "" Vector__XXX
 SG_ APS_w148_vcrightMiaVehBus : 19|1@1+ (1,0) [0|0] "" Vector__XXX
 SG_ APS_w147_vcleftMiaVehBus : 18|1@1+ (1,0) [0|0] "" Vector__XXX
 SG_ APS_w146_epas3pMiaPartyBus : 17|1@1+ (1,0) [0|0] "" Vector__XXX
 SG_ APS_w145_vcrightMiaPartyBus : 16|1@1+ (1,0) [0|0] "" Vector__XXX
 SG_ APS_w144_vcleftMiaPartyBus : 15|1@1+ (1,0) [0|0] "" Vector__XXX
 SG_ APS_w143_espMiaPartyBus : 14|1@1+ (1,0) [0|0] "" Vector__XXX
 SG_ APS_w142_diMiaPartyBus : 13|1@1+ (1,0) [0|0] "" Vector__XXX
 SG_ APS_w141_rcmMiaPartyBus : 12|1@1+ (1,0) [0|0] "" Vector__XXX
 SG_ APS_w140_vcfrontMiaVehicleBus : 11|1@1+ (1,0) [0|0] "" Vector__XXX
 SG_ APS_w139_udpBufferOverflow : 10|1@1+ (1,0) [0|0] "" Vector__XXX
 SG_ APS_w138_gpsComIssue : 9|1@1+ (1,0) [0|0] "" Vector__XXX
 SG_ APS_w137_gpsFaultReset : 8|1@1+ (1,0) [0|0] "" Vector__XXX
 SG_ APS_w136_gpsDisabled : 7|1@1+ (1,0) [0|0] "" Vector__XXX
 SG_ APS_w135_appCritical : 6|1@1+ (1,0) [0|0] "" Vector__XXX
 SG_ APS_w134_appMia : 5|1@1+ (1,0) [0|0] "" Vector__XXX
 SG_ APS_w133_ETHSwitchError : 4|1@1+ (1,0) [0|0] "" Vector__XXX
 SG_ APS_w132_appVersionMismatch : 3|1@1+ (1,0) [0|0] "" Vector__XXX
 SG_ APS_w131_trap_exception : 2|1@1+ (1,0) [0|0] "" Vector__XXX
 SG_ APS_w130_ECU_Thermal_Issue : 1|1@1+ (1,0) [0|0] "" Vector__XXX
 SG_ APS_w129_ECU_Power_Issue : 0|1@1+ (1,0) [0|0] "" Vector__XXX

BO_ 848 APS_warningMatrix3: 8 CH
 SG_ APS_w193_camWindshieldUnclean: 0|1@1+ (1,0) [0|0] "" X
 SG_ APS_w194_accDriverResumeRqrd: 1|1@1+ (1,0) [0|0] "" X
 SG_ APS_w195_scwUnavailable: 2|1@1+ (1,0) [0|0] "" X
 SG_ APS_w196_stopSignWarning: 3|1@1+ (1,0) [0|0] "" X
 SG_ APS_w197_redLightWarning: 4|1@1+ (1,0) [0|0] "" X
 SG_ APS_w198_tsrUnavailable: 5|1@1+ (1,0) [0|0] "" X
 SG_ APS_w199_apcAbort: 6|1@1+ (1,0) [0|0] "" X
 SG_ APS_w200_lcSlowdown: 7|1@1+ (1,0) [0|0] "" X
 SG_ APS_w201_lcAborting: 8|1@1+ (1,0) [0|0] "" X
 SG_ APS_w202_scwNoisyEnvironment: 9|1@1+ (1,0) [0|0] "" X
 SG_ APS_w203_apcActivation: 10|1@1+ (1,0) [0|0] "" X
 SG_ APS_w204_apcFinalFront: 11|1@1+ (1,0) [0|0] "" X
 SG_ APS_w205_apcFinalRear: 12|1@1+ (1,0) [0|0] "" X
 SG_ APS_w206_autosteerNotEnabled: 13|1@1+ (1,0) [0|0] "" X
 SG_ APS_w207_autosteerUnavailable: 14|1@1+ (1,0) [0|0] "" X
 SG_ APS_w208_rackDetected: 15|1@1+ (1,0) [0|0] "" X
 SG_ APS_w209_autoSummonRequest: 16|1@1+ (1,0) [0|0] "" X
 SG_ APS_w210_camObstrcted: 17|1@1+ (1,0) [0|0] "" X
 SG_ APS_w211_accNoSeatBelt: 18|1@1+ (1,0) [0|0] "" X
 SG_ APS_w212_lcUnavailableStrikeOut: 19|1@1+ (1,0) [0|0] "" X
 SG_ APS_w213_autosteerStruckOut: 20|1@1+ (1,0) [0|0] "" X
 SG_ APS_w214_driverNotIntracting: 21|1@1+ (1,0) [0|0] "" X
 SG_ APS_w215_contDriverNotIntracting: 22|1@1+ (1,0) [0|0] "" X
 SG_ APS_w216_driverOverriding: 23|1@1+ (1,0) [0|0] "" X
 SG_ APS_w217_lcUnavailableSpeeding: 24|1@1+ (1,0) [0|0] "" X
 SG_ APS_w218_lcSpeedExceededLimit: 25|1@1+ (1,0) [0|0] "" X
 SG_ APS_w219_lcTempUnavailableSpeed: 26|1@1+ (1,0) [0|0] "" X
 SG_ APS_w220_lcTempUnavailableRoad: 27|1@1+ (1,0) [0|0] "" X
 SG_ APS_w221_accRadarBlind: 28|1@1+ (1,0) [0|0] "" X
 SG_ APS_w222_accCameraBlind: 29|1@1+ (1,0) [0|0] "" X
 SG_ APS_w223_accObjectInPath: 30|1@1+ (1,0) [0|0] "" X
 SG_ APS_w224_accCameraCalibration: 31|1@1+ (1,0) [0|0] "" X
 SG_ APS_w225_lcDegradedVisSpeedLmt: 32|1@1+ (1,0) [0|0] "" X
 SG_ APS_w226_lcCamCalNeededSpeedLmt: 33|1@1+ (1,0) [0|0] "" X
 SG_ APS_w227_virtualWallBlocked: 34|1@1+ (1,0) [0|0] "" X
 SG_ APS_w228_DEPRECATED: 35|1@1+ (1,0) [0|0] "" X
 SG_ APS_w229_alcUltrasoundDamaged: 36|1@1+ (1,0) [0|0] "" X
 SG_ APS_w230_alcUltrasoundBlocked: 37|1@1+ (1,0) [0|0] "" X

BO_ 800 BMS_alertMatrix: 8 Vector__XXX
 SG_ BMS_a060_SW_Leakage_Test_Failure m0 : 63|1@1+ (1,0) [0|0] "" Vector__XXX
 SG_ BMS_a180_SW_ECU_reset_blocked m2 : 63|1@1+ (1,0) [0|0] "" Vector__XXX
 SG_ BMS_a059_SW_Pack_Voltage_Sensing m0 : 62|1@1+ (1,0) [0|0] "" Vector__XXX
 SG_ BMS_a119_Fast_Open_Vsh_Detected m1 : 62|1@1+ (1,0) [0|0] "" Vector__XXX
 SG_ BMS_a179_HvpGpoRequestActive m2 : 62|1@1+ (1,0) [0|0] "" Vector__XXX
 SG_ BMS_a058_SW_Bandolier_Model_Rese m0 : 61|1@1+ (1,0) [0|0] "" Vector__XXX
 SG_ BMS_a178_SW_Uncontrolled_Regen_P m2 : 61|1@1+ (1,0) [0|0] "" Vector__XXX
 SG_ BMS_a057_SW_Bandolier_Model_Warn m0 : 60|1@1+ (1,0) [0|0] "" Vector__XXX
 SG_ BMS_a117_SW_Delta_SOC_Weak_Short m1 : 60|1@1+ (1,0) [0|0] "" Vector__XXX
 SG_ BMS_a177_SW_Energy_Buffer_Size m2 : 60|1@1+ (1,0) [0|0] "" Vector__XXX
 SG_ BMS_a056_SW_Standby_Supply_Fault m0 : 59|1@1+ (1,0) [0|0] "" Vector__XXX
 SG_ BMS_a176_SW_GracefulPowerOff m2 : 59|1@1+ (1,0) [0|0] "" Vector__XXX
 SG_ BMS_a055_SW_HvChain_Model_Fault m0 : 58|1@1+ (1,0) [0|0] "" Vector__XXX
 SG_ BMS_a115_Energy_Rubberbanding_Re m1 : 58|1@1+ (1,0) [0|0] "" Vector__XXX
 SG_ BMS_a175_Charge_Failure_External m2 : 58|1@1+ (1,0) [0|0] "" Vector__XXX
 SG_ BMS_a054_SW_Ver_Supply_Fault m0 : 57|1@1+ (1,0) [0|0] "" Vector__XXX
 SG_ BMS_a174_SW_Charge_Failure m2 : 57|1@1+ (1,0) [0|0] "" Vector__XXX
 SG_ BMS_a173_FullPackEnergyDegraded m2 : 56|1@1+ (1,0) [0|0] "" Vector__XXX
 SG_ BMS_a052_SW_PCS_MIA m0 : 55|1@1+ (1,0) [0|0] "" Vector__XXX
 SG_ BMS_a112_LifeModel_Discontinuity m1 : 55|1@1+ (1,0) [0|0] "" Vector__XXX
 SG_ BMS_a172_SW_Isolation_Failure_In m2 : 55|1@1+ (1,0) [0|0] "" Vector__XXX
 SG_ BMS_a051_SW_HVC_Vref_Bad m0 : 54|1@1+ (1,0) [0|0] "" Vector__XXX
 SG_ BMS_a111_LifeModel_Spread_Change m1 : 54|1@1+ (1,0) [0|0] "" Vector__XXX
 SG_ BMS_a171_SW_Stack_Voltage_Sense m2 : 54|1@1+ (1,0) [0|0] "" Vector__XXX
 SG_ BMS_a050_SW_Brick_Voltage_MIA m0 : 53|1@1+ (1,0) [0|0] "" Vector__XXX
 SG_ BMS_a110_LifeModel_AvgOffset_Cha m1 : 53|1@1+ (1,0) [0|0] "" Vector__XXX
 SG_ BMS_a170_SW_Limp_Mode m2 : 53|1@1+ (1,0) [0|0] "" Vector__XXX
 SG_ BMS_d290_batteryPackTempSensorAC m4 : 53|1@1+ (1,0) [0|0] "" Vector__XXX
 SG_ BMS_a049_SW_Thermal_Event m0 : 52|1@1+ (1,0) [0|0] "" Vector__XXX
 SG_ BMS_a109_HW_BMB_Mute_Status_Mism m1 : 52|1@1+ (1,0) [0|0] "" Vector__XXX
 SG_ BMS_a169_SW_FC_Pack_Weld m2 : 52|1@1+ (1,0) [0|0] "" Vector__XXX
 SG_ BMS_d289_batteryPackAOverTempera m4 : 52|1@1+ (1,0) [0|0] "" Vector__XXX
 SG_ BMS_a048_SW_Watch_Dog_Warning m0 : 51|1@1+ (1,0) [0|0] "" Vector__XXX
 SG_ BMS_a108_SW_BMB_Device_OT m1 : 51|1@1+ (1,0) [0|0] "" Vector__XXX
 SG_ BMS_a168_SW_FC_Full_Weld m2 : 51|1@1+ (1,0) [0|0] "" Vector__XXX
 SG_ BMS_d288_batteryPackCellVoltageL m4 : 51|1@1+ (1,0) [0|0] "" Vector__XXX
 SG_ BMS_a047_SW_Task_Stack_Overflow m0 : 50|1@1+ (1,0) [0|0] "" Vector__XXX
 SG_ BMS_a107_SW_Stack_Voltage_MIA m1 : 50|1@1+ (1,0) [0|0] "" Vector__XXX
 SG_ BMS_a167_SW_FC_Partial_Weld m2 : 50|1@1+ (1,0) [0|0] "" Vector__XXX
 SG_ BMS_d287_systemIsolationWarning m4 : 50|1@1+ (1,0) [0|0] "" Vector__XXX
 SG_ BMS_a046_SW_Task_Stack_Usage m0 : 49|1@1+ (1,0) [0|0] "" Vector__XXX
 SG_ BMS_a106_SW_All_Module_Tsense m1 : 49|1@1+ (1,0) [0|0] "" Vector__XXX
 SG_ BMS_a166_SW_Pack_Full_Weld m2 : 49|1@1+ (1,0) [0|0] "" Vector__XXX
 SG_ BMS_d286_dcLinkVoltageHigh m4 : 49|1@1+ (1,0) [0|0] "" Vector__XXX
 SG_ BMS_a045_SW_Exception m0 : 48|1@1+ (1,0) [0|0] "" Vector__XXX
 SG_ BMS_a105_SW_One_Module_Tsense m1 : 48|1@1+ (1,0) [0|0] "" Vector__XXX
 SG_ BMS_a165_SW_Pack_Partial_Weld m2 : 48|1@1+ (1,0) [0|0] "" Vector__XXX
 SG_ BMS_d285_packVoltageSensorACircu m4 : 48|1@1+ (1,0) [0|0] "" Vector__XXX
 SG_ BMS_a044_SW_Assertion m0 : 47|1@1+ (1,0) [0|0] "" Vector__XXX
 SG_ BMS_a164_SW_Uncontrolled_Regen m2 : 47|1@1+ (1,0) [0|0] "" Vector__XXX
 SG_ BMS_d284_fastChargeNegContactorA m4 : 47|1@1+ (1,0) [0|0] "" Vector__XXX
 SG_ BMS_a043_SW_Watch_Dog_Reset m0 : 46|1@1+ (1,0) [0|0] "" Vector__XXX
 SG_ BMS_a163_GridFormAborted m2 : 46|1@1+ (1,0) [0|0] "" Vector__XXX
 SG_ BMS_d283_fastChargeNegContactorA m4 : 46|1@1+ (1,0) [0|0] "" Vector__XXX
 SG_ BMS_a042_SW_MPU_Error m0 : 45|1@1+ (1,0) [0|0] "" Vector__XXX
 SG_ BMS_a162_SW_No_Power_For_Support m2 : 45|1@1+ (1,0) [0|0] "" Vector__XXX
 SG_ BMS_d282_fastChargeNegContactorA m4 : 45|1@1+ (1,0) [0|0] "" Vector__XXX
 SG_ BMS_a041_SW_Destructive_Reset_So m0 : 44|1@1+ (1,0) [0|0] "" Vector__XXX
 SG_ BMS_a161_SW_BMB_Vref_warning m2 : 44|1@1+ (1,0) [0|0] "" Vector__XXX
 SG_ BMS_d281_fastChargePosContactorA m4 : 44|1@1+ (1,0) [0|0] "" Vector__XXX
 SG_ BMS_a040_SW_Watch_Dog_HW_Trigger m0 : 43|1@1+ (1,0) [0|0] "" Vector__XXX
 SG_ BMS_a100_ThermalEventSuspected m1 : 43|1@1+ (1,0) [0|0] "" Vector__XXX
 SG_ BMS_a160_SW_FC_Ctr_Clean_Failed m2 : 43|1@1+ (1,0) [0|0] "" Vector__XXX
 SG_ BMS_d280_fastChargePosContactorA m4 : 43|1@1+ (1,0) [0|0] "" Vector__XXX
 SG_ BMS_a039_SW_DC_Link_Over_Voltage m0 : 42|1@1+ (1,0) [0|0] "" Vector__XXX
 SG_ BMS_a099_SW_BMB_Communication m1 : 42|1@1+ (1,0) [0|0] "" Vector__XXX
 SG_ BMS_a159_SW_HVP_ECU_Error m2 : 42|1@1+ (1,0) [0|0] "" Vector__XXX
 SG_ BMS_d279_fastChargePosContactorA m4 : 42|1@1+ (1,0) [0|0] "" Vector__XXX
 SG_ BMS_a098_SW_BMB_Data_Integrity_L m1 : 41|1@1+ (1,0) [0|0] "" Vector__XXX
 SG_ BMS_a158_SW_HVP_HVI_Comms m2 : 41|1@1+ (1,0) [0|0] "" Vector__XXX
 SG_ BMS_d278_packNegContactorAStuckC m4 : 41|1@1+ (1,0) [0|0] "" Vector__XXX
 SG_ BMS_a037_SW_Flood_Port_Open m0 : 40|1@1+ (1,0) [0|0] "" Vector__XXX
 SG_ BMS_a097_SW_BMB_Over_CAN_Communi m1 : 40|1@1+ (1,0) [0|0] "" Vector__XXX
 SG_ BMS_a157_SW_Hist_Update_Missed m2 : 40|1@1+ (1,0) [0|0] "" Vector__XXX
 SG_ BMS_d277_packNegContactorACircui m4 : 40|1@1+ (1,0) [0|0] "" Vector__XXX
 SG_ BMS_a036_SW_HvpHvilFault m0 : 39|1@1+ (1,0) [0|0] "" Vector__XXX
 SG_ BMS_a156_SW_BMB_Vref_bad m2 : 39|1@1+ (1,0) [0|0] "" Vector__XXX
 SG_ BMS_d276_packPosContactorAStuckC m4 : 39|1@1+ (1,0) [0|0] "" Vector__XXX
 SG_ BMS_a035_SW_Isolation m0 : 38|1@1+ (1,0) [0|0] "" Vector__XXX
 SG_ BMS_a095_SW_UI_MIA m1 : 38|1@1+ (1,0) [0|0] "" Vector__XXX
 SG_ BMS_a155_SW_Weak_short_impedence m2 : 38|1@1+ (1,0) [0|0] "" Vector__XXX
 SG_ BMS_d275_packPosContactorACircui m4 : 38|1@1+ (1,0) [0|0] "" Vector__XXX
 SG_ BMS_a034_SW_Passive_Isolation m0 : 37|1@1+ (1,0) [0|0] "" Vector__XXX
 SG_ BMS_a094_SW_Drive_Inverter_MIA m1 : 37|1@1+ (1,0) [0|0] "" Vector__XXX
 SG_ BMS_a154_SW_Brick_OV_Warning_Sto m2 : 37|1@1+ (1,0) [0|0] "" Vector__XXX
 SG_ BMS_d274_packCurrentSensorACircu m4 : 37|1@1+ (1,0) [0|0] "" Vector__XXX
 SG_ BMS_a033_VoltageDeviation m0 : 36|1@1+ (1,0) [0|0] "" Vector__XXX
 SG_ BMS_a153_GridFormFaulted m2 : 36|1@1+ (1,0) [0|0] "" Vector__XXX
 SG_ BMS_d273_vcFrontCommsLost m4 : 36|1@1+ (1,0) [0|0] "" Vector__XXX
 SG_ BMS_a032_VoltageLoss m0 : 35|1@1+ (1,0) [0|0] "" Vector__XXX
 SG_ BMS_a092_SW_ChargePort_Mia_On_Hv m1 : 35|1@1+ (1,0) [0|0] "" Vector__XXX
 SG_ BMS_a152_Isolation_In_Dc_Charge m2 : 35|1@1+ (1,0) [0|0] "" Vector__XXX
 SG_ BMS_d272_batteryPackSensorCommsL m4 : 35|1@1+ (1,0) [0|0] "" Vector__XXX
 SG_ BMS_a031_AlertsSetDuringSleep m0 : 34|1@1+ (1,0) [0|0] "" Vector__XXX
 SG_ BMS_a091_SW_ChargePort_MIA m1 : 34|1@1+ (1,0) [0|0] "" Vector__XXX
 SG_ BMS_a151_SW_external_isolation m2 : 34|1@1+ (1,0) [0|0] "" Vector__XXX
 SG_ BMS_d271_batteryPackSensorFailur m4 : 34|1@1+ (1,0) [0|0] "" Vector__XXX
 SG_ BMS_a030_Impedance_Deviation m0 : 33|1@1+ (1,0) [0|0] "" Vector__XXX
 SG_ BMS_a090_SW_Gateway_MIA m1 : 33|1@1+ (1,0) [0|0] "" Vector__XXX
 SG_ BMS_a150_SW_Missing_Part_Number m2 : 33|1@1+ (1,0) [0|0] "" Vector__XXX
 SG_ BMS_d270_hvpCommsLost m4 : 33|1@1+ (1,0) [0|0] "" Vector__XXX
 SG_ BMS_a029_dSoc_Limiting m0 : 32|1@1+ (1,0) [0|0] "" Vector__XXX
 SG_ BMS_a089_SW_VcFront_MIA m1 : 32|1@1+ (1,0) [0|0] "" Vector__XXX
 SG_ BMS_a149_SW_Missing_Config_Block m2 : 32|1@1+ (1,0) [0|0] "" Vector__XXX
 SG_ BMS_d269_highVoltageFuseABlown m4 : 32|1@1+ (1,0) [0|0] "" Vector__XXX
 SG_ BMS_a028_ShuntAsicCurrentOffsetD m0 : 31|1@1+ (1,0) [0|0] "" Vector__XXX
 SG_ BMS_a088_SW_VcFront_MIA_InDrive m1 : 31|1@1+ (1,0) [0|0] "" Vector__XXX
 SG_ BMS_a148_SW_Unsupported_BMB_ASIC m2 : 31|1@1+ (1,0) [0|0] "" Vector__XXX
 SG_ BMS_d268_hvpInvalidFirmwareConfi m4 : 31|1@1+ (1,0) [0|0] "" Vector__XXX
 SG_ BMS_a027_SW_Repeated_Isolation_F m0 : 30|1@1+ (1,0) [0|0] "" Vector__XXX
 SG_ BMS_a087_SW_Feim_Test_Blocked m1 : 30|1@1+ (1,0) [0|0] "" Vector__XXX
 SG_ BMS_a147_SW_SOC_High_Ah_Error m2 : 30|1@1+ (1,0) [0|0] "" Vector__XXX
 SG_ BMS_d267_batteryPackCellVoltageS m4 : 30|1@1+ (1,0) [0|0] "" Vector__XXX
 SG_ BMS_a026_SW_HFCurrent_Anomaly m0 : 29|1@1+ (1,0) [0|0] "" Vector__XXX
 SG_ BMS_a086_SW_FC_Contactor_Mismatc m1 : 29|1@1+ (1,0) [0|0] "" Vector__XXX
 SG_ BMS_a146_SW_Brick_Overdischarged m2 : 29|1@1+ (1,0) [0|0] "" Vector__XXX
 SG_ BMS_d266_energyReserveVoltageLow m4 : 29|1@1+ (1,0) [0|0] "" Vector__XXX
 SG_ BMS_a025_SW_PwrBalance_Anomaly m0 : 28|1@1+ (1,0) [0|0] "" Vector__XXX
 SG_ BMS_a085_SW_Pack_Contactor_Misma m1 : 28|1@1+ (1,0) [0|0] "" Vector__XXX
 SG_ BMS_a145_SW_SOC_Change m2 : 28|1@1+ (1,0) [0|0] "" Vector__XXX
 SG_ BMS_d265_replaceBatteryPack m4 : 28|1@1+ (1,0) [0|0] "" Vector__XXX
 SG_ BMS_a024_SW_Islanded_Brick m0 : 27|1@1+ (1,0) [0|0] "" Vector__XXX
 SG_ BMS_a084_SW_Sleep_Wake_Aborted m1 : 27|1@1+ (1,0) [0|0] "" Vector__XXX
 SG_ BMS_a144_Hvp_Config_Mismatch m2 : 27|1@1+ (1,0) [0|0] "" Vector__XXX
 SG_ BMS_d264_invalidFirmwareConfig m4 : 27|1@1+ (1,0) [0|0] "" Vector__XXX
 SG_ BMS_a023_SW_Stack_OV m0 : 26|1@1+ (1,0) [0|0] "" Vector__XXX
 SG_ BMS_a083_SW_Ctr_Close_Failure m1 : 26|1@1+ (1,0) [0|0] "" Vector__XXX
 SG_ BMS_a143_SW_CAC_Change m2 : 26|1@1+ (1,0) [0|0] "" Vector__XXX
 SG_ BMS_d263_batterySystemCurrentHig m4 : 26|1@1+ (1,0) [0|0] "" Vector__XXX
 SG_ BMS_a022_SW_Over_Current m0 : 25|1@1+ (1,0) [0|0] "" Vector__XXX
 SG_ BMS_a082_SW_Ctr_Force_Open m1 : 25|1@1+ (1,0) [0|0] "" Vector__XXX
 SG_ BMS_a142_SW_Isolation_Degradatio m2 : 25|1@1+ (1,0) [0|0] "" Vector__XXX
 SG_ BMS_d262_batteryPackLowStateOfCh m4 : 25|1@1+ (1,0) [0|0] "" Vector__XXX
 SG_ BMS_a021_SW_Dr_Limits_Regulation m0 : 24|1@1+ (1,0) [0|0] "" Vector__XXX
 SG_ BMS_a081_SW_Ctr_Close_Blocked m1 : 24|1@1+ (1,0) [0|0] "" Vector__XXX
 SG_ BMS_a141_SW_BMB_Status_Warning m2 : 24|1@1+ (1,0) [0|0] "" Vector__XXX
 SG_ BMS_d261_batteryPackCellVoltageH m4 : 24|1@1+ (1,0) [0|0] "" Vector__XXX
 SG_ BMS_a020_SW_Brick_Instability m0 : 23|1@1+ (1,0) [0|0] "" Vector__XXX
 SG_ BMS_a080_SW_Pack_Ctr_Impedance m1 : 23|1@1+ (1,0) [0|0] "" Vector__XXX
 SG_ BMS_a140_HW_BMB_Status_Fault m2 : 23|1@1+ (1,0) [0|0] "" Vector__XXX
 SG_ BMS_d260_chargePortInterlockFail m4 : 23|1@1+ (1,0) [0|0] "" Vector__XXX
 SG_ BMS_a019_SW_Module_OT m0 : 22|1@1+ (1,0) [0|0] "" Vector__XXX
 SG_ BMS_a079_Max_Charge_Level_Exceed m1 : 22|1@1+ (1,0) [0|0] "" Vector__XXX
 SG_ BMS_a139_SW_DC_Link_V_Irrational m2 : 22|1@1+ (1,0) [0|0] "" Vector__XXX
 SG_ BMS_d259_highVoltageInterlockFai m4 : 22|1@1+ (1,0) [0|0] "" Vector__XXX
 SG_ BMS_a018_SW_Brick_UV m0 : 21|1@1+ (1,0) [0|0] "" Vector__XXX
 SG_ BMS_a078_Rapid_Dch_While_Chargin m1 : 21|1@1+ (1,0) [0|0] "" Vector__XXX
 SG_ BMS_a138_SW_Brick_OV_Warning m2 : 21|1@1+ (1,0) [0|0] "" Vector__XXX
 SG_ BMS_a198_SW_SOC_Abrupt_Change m3 : 21|1@1+ (1,0) [0|0] "" Vector__XXX
 SG_ BMS_d258_externalIsolationFault m4 : 21|1@1+ (1,0) [0|0] "" Vector__XXX
 SG_ BMS_a017_SW_Brick_OV m0 : 20|1@1+ (1,0) [0|0] "" Vector__XXX
 SG_ BMS_a077_SW_Charger_Regulation m1 : 20|1@1+ (1,0) [0|0] "" Vector__XXX
 SG_ BMS_a137_SW_Brick_UV_Warning m2 : 20|1@1+ (1,0) [0|0] "" Vector__XXX
 SG_ BMS_a197_SW_High_SOC_OV m3 : 20|1@1+ (1,0) [0|0] "" Vector__XXX
 SG_ BMS_d257_internalIsolationFault m4 : 20|1@1+ (1,0) [0|0] "" Vector__XXX
 SG_ BMS_a016_Pack_Module_Id_Mismatch m0 : 19|1@1+ (1,0) [0|0] "" Vector__XXX
 SG_ BMS_a076_SW_Dch_While_Charging m1 : 19|1@1+ (1,0) [0|0] "" Vector__XXX
 SG_ BMS_a136_SW_Module_OT_Warning m2 : 19|1@1+ (1,0) [0|0] "" Vector__XXX
 SG_ BMS_a196_SW_PackVoltageUnderThre m3 : 19|1@1+ (1,0) [0|0] "" Vector__XXX
 SG_ BMS_a075_SW_Chg_Disable_Failure m1 : 18|1@1+ (1,0) [0|0] "" Vector__XXX
 SG_ BMS_a135_HW_BMB_Diagnostics_Fail m2 : 18|1@1+ (1,0) [0|0] "" Vector__XXX
 SG_ BMS_a195_SW_DeltaTempOverThresho m3 : 18|1@1+ (1,0) [0|0] "" Vector__XXX
 SG_ BMS_a074_Max_Charge_Level_Reduce m1 : 17|1@1+ (1,0) [0|0] "" Vector__XXX
 SG_ BMS_a134_SW_Delayed_Ctr_Off m2 : 17|1@1+ (1,0) [0|0] "" Vector__XXX
 SG_ BMS_a194_PowershareLimitViolatio m3 : 17|1@1+ (1,0) [0|0] "" Vector__XXX
 SG_ BMS_a073_Unexpected_Loss_Of_Lv m1 : 16|1@1+ (1,0) [0|0] "" Vector__XXX
 SG_ BMS_a133_IO_CAN_Bus_Off m2 : 16|1@1+ (1,0) [0|0] "" Vector__XXX
 SG_ BMS_a193_PowershareMaxBrickVolta m3 : 16|1@1+ (1,0) [0|0] "" Vector__XXX
 SG_ BMS_a072_Module_Brick_Split m1 : 15|1@1+ (1,0) [0|0] "" Vector__XXX
 SG_ BMS_a132_HW_BMB_OTP_Uncorrctbl m2 : 15|1@1+ (1,0) [0|0] "" Vector__XXX
 SG_ BMS_a192_PowershareExternalCharg m3 : 15|1@1+ (1,0) [0|0] "" Vector__XXX
 SG_ BMS_a071_SW_SM_TransCon_Not_Met m1 : 14|1@1+ (1,0) [0|0] "" Vector__XXX
 SG_ BMS_a131_Bleed_FET_Failure m2 : 14|1@1+ (1,0) [0|0] "" Vector__XXX
 SG_ BMS_a191_PowershareMinVoltageVio m3 : 14|1@1+ (1,0) [0|0] "" Vector__XXX
 SG_ BMS_a070_BrickV_Imbalance_Limiti m1 : 13|1@1+ (1,0) [0|0] "" Vector__XXX
 SG_ BMS_a130_IO_CAN_Error m2 : 13|1@1+ (1,0) [0|0] "" Vector__XXX
 SG_ BMS_a190_PowershareMaxVoltageVio m3 : 13|1@1+ (1,0) [0|0] "" Vector__XXX
 SG_ BMS_a069_SW_Low_Power m1 : 12|1@1+ (1,0) [0|0] "" Vector__XXX
 SG_ BMS_a129_SW_VSH_Failure m2 : 12|1@1+ (1,0) [0|0] "" Vector__XXX
 SG_ BMS_a189_PowershareDischargeCurr m3 : 12|1@1+ (1,0) [0|0] "" Vector__XXX
 SG_ BMS_a068_CAC_Imbalance_Limp m1 : 11|1@1+ (1,0) [0|0] "" Vector__XXX
 SG_ BMS_a128_SW_shunt_MIA m2 : 11|1@1+ (1,0) [0|0] "" Vector__XXX
 SG_ BMS_a188_PowershareChargeCurrent m3 : 11|1@1+ (1,0) [0|0] "" Vector__XXX
 SG_ BMS_a067_CAC_Imbalance_Limiting m1 : 10|1@1+ (1,0) [0|0] "" Vector__XXX
 SG_ BMS_a127_SW_shunt_SNA m2 : 10|1@1+ (1,0) [0|0] "" Vector__XXX
 SG_ BMS_a187_RippleHeatingEmergencyS m3 : 10|1@1+ (1,0) [0|0] "" Vector__XXX
 SG_ BMS_a066_SOC_Imbalance_Warning m1 : 9|1@1+ (1,0) [0|0] "" Vector__XXX
 SG_ BMS_a126_SW_Thermistor_Failure m2 : 9|1@1+ (1,0) [0|0] "" Vector__XXX
 SG_ BMS_a186_RippleHeatingChargeFaul m3 : 9|1@1+ (1,0) [0|0] "" Vector__XXX
 SG_ BMS_a065_SW_CAC_Imbalance m1 : 8|1@1+ (1,0) [0|0] "" Vector__XXX
 SG_ BMS_a185_LifeModel_CyclingDcrGro m3 : 8|1@1+ (1,0) [0|0] "" Vector__XXX
 SG_ BMS_a004_Cal_Vs_Serial_Birth_Dat m0 : 7|1@1+ (1,0) [0|0] "" Vector__XXX
 SG_ BMS_a064_SW_SOC_Imbalance m1 : 7|1@1+ (1,0) [0|0] "" Vector__XXX
 SG_ BMS_a124_Battery_Coolant_Flood m2 : 7|1@1+ (1,0) [0|0] "" Vector__XXX
 SG_ BMS_a184_LifeModel_CyclingLoss_C m3 : 7|1@1+ (1,0) [0|0] "" Vector__XXX
 SG_ BMS_a003_SW_Pack_Birth_Date_Miss m0 : 6|1@1+ (1,0) [0|0] "" Vector__XXX
 SG_ BMS_a063_SW_ChargePort_Fault m1 : 6|1@1+ (1,0) [0|0] "" Vector__XXX
 SG_ BMS_a123_SW_Internal_Isolation m2 : 6|1@1+ (1,0) [0|0] "" Vector__XXX
 SG_ BMS_a183_LifeModel_StoDcrGrowth_ m3 : 6|1@1+ (1,0) [0|0] "" Vector__XXX
 SG_ BMS_a002_Pack_Performance_Config m0 : 5|1@1+ (1,0) [0|0] "" Vector__XXX
 SG_ BMS_a062_SW_BrickV_Imbalance m1 : 5|1@1+ (1,0) [0|0] "" Vector__XXX
 SG_ BMS_a122_SW_BMS_Therm_Irrational m2 : 5|1@1+ (1,0) [0|0] "" Vector__XXX
 SG_ BMS_a182_LifeModel_NoCurrentLoss m3 : 5|1@1+ (1,0) [0|0] "" Vector__XXX
 SG_ BMS_a001_Pack_Config_Mismatch m0 : 4|1@1+ (1,0) [0|0] "" Vector__XXX
 SG_ BMS_a061_SW_BrickV_Change m1 : 4|1@1+ (1,0) [0|0] "" Vector__XXX
 SG_ BMS_a121_SW_NVRAM_Config_Error m2 : 4|1@1+ (1,0) [0|0] "" Vector__XXX
 SG_ BMS_a181_SW_Shunt_Over_Temperatu m3 : 4|1@1+ (1,0) [0|0] "" Vector__XXX
 SG_ BMS_matrixIndex M : 0|4@1+ (1,0) [0|0] "" Vector__XXX

BO_ 818 BMS_bmbMinMax: 6 VEH
 SG_ BMS_bmbMinMaxMultiplexer M: 0|2@1+ (1,0) [0|0] "" X
 SG_ BMS_thermistorNumTMax m0: 2|4@1+ (1,0) [0|0] "" X
 SG_ BMS_thermistorNumTMin m0: 8|4@1+ (1,0) [0|0] "" X
 SG_ BMS_thermistorTMax m0: 16|8@1+ (0.5,-40) [0|0] "DegC" X
 SG_ BMS_thermistorTMin m0: 24|8@1+ (0.5,-40) [0|0] "DegC" X
 SG_ BMS_modelTMax m0: 32|8@1+ (0.5,-40) [0|0] "DegC" X
 SG_ BMS_modelTMin m0: 40|8@1+ (0.5,-40) [0|0] "DegC" X
 SG_ BMS_brickVoltageMax m1: 2|12@1+ (0.002,0) [0|0] "V" X
 SG_ BMS_brickVoltageMin m1: 16|12@1+ (0.002,0) [0|0] "V" X
 SG_ BMS_brickNumVoltageMax m1: 32|7@1+ (1,1) [0|0] "" X
 SG_ BMS_brickNumVoltageMin m1: 40|7@1+ (1,1) [0|0] "" X

BO_ 690 BMS_chargerRequest: 3 VEH
 SG_ BMS_acChargeEnable: 17|1@1+ (1,0) [0|0] "" X
 SG_ BMS_acChargePowerRequest: 0|16@1+ (0.001,0) [0|0] "kW" X
 SG_ BMS_pcsClearFaultRequest: 16|1@1+ (1,0) [0|0] "" X

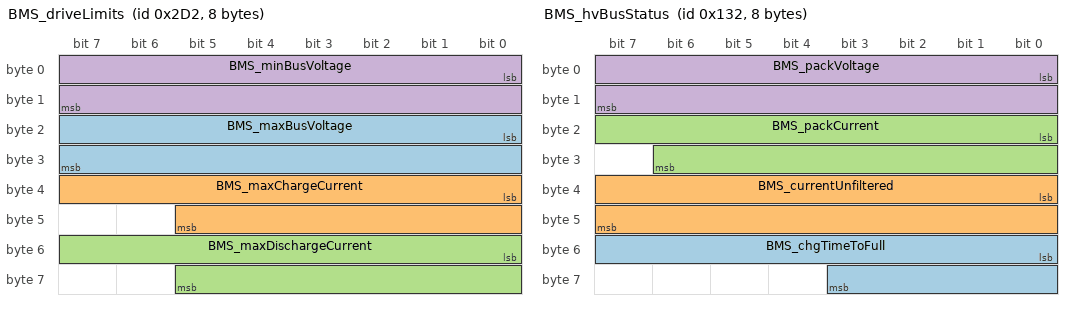
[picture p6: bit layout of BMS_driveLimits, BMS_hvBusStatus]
BO_ 722 BMS_driveLimits: 8 VEH
 SG_ BMS_maxBusVoltage: 16|16@1+ (0.01,0) [0|0] "V" X
 SG_ BMS_maxChargeCurrent: 32|14@1+ (0.1,0) [0|0] "A" X
 SG_ BMS_maxDischargeCurrent: 48|14@1+ (0.128,0) [0|0] "A" X
 SG_ BMS_minBusVoltage: 0|16@1+ (0.01,0) [0|0] "V" X

BO_ 850 BMS_energyStatus: 8 VEH
 SG_ BMS_energyStatusIndex M : 0|2@1+ (1,0) [0|0] "" X
 SG_ BMS_nominalFullPackEnergy m0 : 16|16@1+ (0.02,0) [0|0] "kWh" X
 SG_ BMS_nominalEnergyRemaining m0 : 32|16@1+ (0.02,0) [0|0] "kWh" X
 SG_ BMS_idealEnergyRemaining m0 : 48|16@1+ (0.02,0) [0|0] "kWh" X
 SG_ BMS_fullyCharged m1 : 15|1@1+ (1,0) [0|1] "" X
 SG_ BMS_energyBuffer m1 : 16|16@1+ (0.01,0) [0|0] "kWh" X
 SG_ BMS_expectedEnergyRemaining m1 : 32|16@1+ (0.02,0) [0|0] "kWh" X
 SG_ BMS_energyToChargeComplete m1 : 48|16@1+ (0.02,0) [0|0] "kWh" X

BO_ 306 BMS_hvBusStatus: 8 VEH
 SG_ BMS_chgTimeToFull: 48|12@1+ (0.0166667,0) [0|0] "Hours" X
 SG_ BMS_currentUnfiltered: 32|16@1- (-0.05,822) [0|0] "A" X
 SG_ BMS_packCurrent: 16|15@1- (-0.1,0) [0|0] "A" X
 SG_ BMS_packVoltage: 0|16@1+ (0.01,0) [0|0] "V" X

BO_ 768 BMS_info: 8 VEH
 SG_ BMS_infoIndex M: 0|8@1+ (1,0) [0|0] "" X
 SG_ BMS_buildType m10: 8|3@1+ (1,0) [0|0] "" X
 SG_ BMS_buildConfigId m10: 16|16@1+ (1,0) [0|0] "" X
 SG_ BMS_hardwareId m10: 32|16@1+ (1,0) [0|0] "" X
 SG_ BMS_componentId m10: 48|16@1+ (1,0) [0|0] "" X
 SG_ BMS_pcbaId m11: 16|8@1+ (1,0) [0|0] "" X
 SG_ BMS_assemblyId m11: 24|8@1+ (1,0) [0|0] "" X
 SG_ BMS_usageId m11: 32|16@1+ (1,0) [0|0] "" X
 SG_ BMS_subUsageId m11: 48|16@1+ (1,0) [0|0] "" X
 SG_ BMS_platformType m13: 8|8@1+ (1,0) [0|0] "" X
 SG_ BMS_appCrc m13: 32|32@1+ (1,0) [0|0] "" X
 SG_ BMS_appGitHash m17: 10|54@1+ (4,0) [0|0] "" X
 SG_ BMS_bootGitHash m18: 10|54@1+ (4,0) [0|0] "" X
 SG_ BMS_bootUdsProtoVersion m20: 8|8@1+ (1,0) [0|0] "" X
 SG_ BMS_bootCrc m20: 32|32@1+ (1,0) [0|0] "" X

BO_ 978 BMS_kwhCounter: 8 VEH
 SG_ BMS_kwhChargeTotal: 32|32@1+ (0.001,0) [0|0] "KWh" X
 SG_ BMS_kwhDischargeTotal: 0|32@1+ (0.001,0) [0|0] "KWh" X

BO_ 1010 BMS_kwhCountersMultiplexed: 8 Vector__XXX
 SG_ BMS_kwhChargeTotalModule1 m4 : 36|28@1+ (0.001,0) [0|0] "" Vector__XXX
 SG_ BMS_kwhChargeTotalModule2 m6 : 36|28@1+ (0.001,0) [0|0] "" Vector__XXX
 SG_ BMS_kwhChargeTotalModule3 m8 : 36|28@1+ (0.001,0) [0|0] "" Vector__XXX
 SG_ BMS_kwhChargeTotalModule4 m10 : 36|28@1+ (0.001,0) [0|0] "" Vector__XXX
 SG_ BMS_kwhDcChargeTotalModule1 m5 : 36|28@1+ (0.001,0) [0|0] "" Vector__XXX
 SG_ BMS_kwhDcChargeTotalModule2 m7 : 36|28@1+ (0.001,0) [0|0] "" Vector__XXX
 SG_ BMS_kwhDcChargeTotalModule3 m9 : 36|28@1+ (0.001,0) [0|0] "" Vector__XXX
 SG_ BMS_kwhDcChargeTotalModule4 m11 : 36|28@1+ (0.001,0) [0|0] "" Vector__XXX
 SG_ BMS_acChargerKwhTotal m0 : 8|32@1+ (0.001,0) [0|0] "" Vector__XXX
 SG_ BMS_dcChargerKwhTotal m1 : 8|32@1+ (0.001,0) [0|0] "" Vector__XXX
 SG_ BMS_kwhAcChargeTotalModule1 m5 : 8|28@1+ (0.001,0) [0|0] "" Vector__XXX
 SG_ BMS_kwhAcChargeTotalModule2 m7 : 8|28@1+ (0.001,0) [0|0] "" Vector__XXX
 SG_ BMS_kwhAcChargeTotalModule3 m9 : 8|28@1+ (0.001,0) [0|0] "" Vector__XXX
 SG_ BMS_kwhAcChargeTotalModule4 m11 : 8|28@1+ (0.001,0) [0|0] "" Vector__XXX
 SG_ BMS_kwhDischargeTotalModule1 m4 : 8|28@1+ (0.001,0) [0|0] "" Vector__XXX
 SG_ BMS_kwhDischargeTotalModule2 m6 : 8|28@1+ (0.001,0) [0|0] "" Vector__XXX
 SG_ BMS_kwhDischargeTotalModule3 m8 : 8|28@1+ (0.001,0) [0|0] "" Vector__XXX
 SG_ BMS_kwhDischargeTotalModule4 m10 : 8|28@1+ (0.001,0) [0|0] "" Vector__XXX
 SG_ BMS_kwhDriveDischargeTotal m3 : 8|32@1+ (0.001,0) [0|0] "" Vector__XXX
 SG_ BMS_kwhRegenChargeTotal m2 : 8|32@1+ (0.001,0) [0|0] "" Vector__XXX
 SG_ BMS_kwhCounter_Id M : 0|4@1+ (1,0) [0|0] "" Vector__XXX

BO_ 594 BMS_powerAvailable: 8 VEH
 SG_ BMS_hvacPowerBudget: 50|10@1+ (0.02,0) [0|0] "kW" X
 SG_ BMS_maxDischargePower: 16|16@1+ (0.01,0) [0|0] "kW" X
 SG_ BMS_maxRegenPower: 0|16@1+ (0.01,0) [0|0] "kW" X
 SG_ BMS_maxStationaryHeatPower: 32|10@1+ (0.01,0) [0|0] "kW" X
 SG_ BMS_powerLimitsState: 48|1@1+ (1,0) [0|0] "" X
 SG_ BMS_inverterTQF : 56|2@1+ (1,0) [0|3] "" X

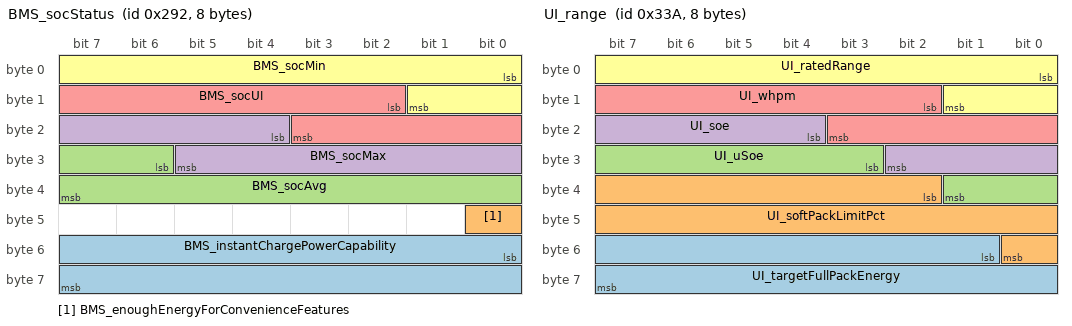
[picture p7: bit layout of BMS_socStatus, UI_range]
BO_ 658 BMS_socStatus: 8 Vector__XXX
 SG_ BMS_instantChargePowerCapability : 48|16@1+ (0.05,0) [0|0] "" Vector__XXX
 SG_ BMS_enoughEnergyForConvenienceFeatures : 40|1@1+ (1,0) [0|0] "" Vector__XXX
 SG_ BMS_socAvg : 30|10@1+ (0.1,0) [0|0] "" Vector__XXX
 SG_ BMS_socMax : 20|10@1+ (0.1,0) [0|0] "" Vector__XXX
 SG_ BMS_socUI : 10|10@1+ (0.1,0) [0|0] "" Vector__XXX
 SG_ BMS_socMin : 0|10@1+ (0.1,0) [0|0] "" Vector__XXX

BO_ 826 UI_range: 8 Vector__XXX
 SG_ UI_targetFullPackEnergy : 49|15@1+ (0.0061037018951994385,0) [0|0] "" Vector__XXX
 SG_ UI_softPackLimitPct : 34|15@1+ (0.0030518509475997192,0) [0|0] "" Vector__XXX
 SG_ UI_uSoe : 27|7@1+ (1,0) [0|0] "" Vector__XXX
 SG_ UI_soe : 20|7@1+ (1,0) [0|0] "" Vector__XXX
 SG_ UI_whpm : 10|10@1+ (1,0) [0|0] "" Vector__XXX
 SG_ UI_ratedRange : 0|10@1+ (1,0) [0|0] "" Vector__XXX

BO_ 530 BMS_status: 8 Vector__XXX
 SG_ BMS_hvState : 60|3@1+ (1,0) [0|0] "" Vector__XXX
 SG_ BMS_smStateRequest : 56|4@1+ (1,0) [0|0] "" Vector__XXX
 SG_ BMS_conditioningRequest : 55|1@1+ (1,0) [0|0] "" Vector__XXX
 SG_ BMS_chargeRetryCount : 52|3@1+ (1,0) [0|0] "" Vector__XXX
 SG_ BMS_chgPowerAvailable : 39|12@1+ (0.125,0) [0|0] "" Vector__XXX
 SG_ BMS_okToShipByLand : 38|1@1+ (1,0) [0|0] "" Vector__XXX
 SG_ BMS_okToShipByAir : 37|1@1+ (1,0) [0|0] "" Vector__XXX
 SG_ BMS_diLimpRequest : 36|1@1+ (1,0) [0|0] "" Vector__XXX
 SG_ BMS_state : 32|4@1+ (1,0) [0|0] "" Vector__XXX
 SG_ BMS_chargeRequest : 30|1@1+ (1,0) [0|0] "" Vector__XXX
 SG_ BMS_batteryInputPower : 14|16@1+ (0.05,0) [0|0] "" Vector__XXX
 SG_ BMS_userChargeStatus : 11|3@1+ (1,0) [0|0] "" Vector__XXX
 SG_ BMS_contactorState : 8|3@1+ (1,0) [0|0] "" Vector__XXX
 SG_ BMS_pcsPwmEnabled : 6|1@1+ (1,0) [0|0] "" Vector__XXX
 SG_ BMS_cpMiaOnHvs : 5|1@1+ (1,0) [0|0] "" Vector__XXX
 SG_ BMS_updateAllowed : 4|1@1+ (1,0) [0|0] "" Vector__XXX
 SG_ BMS_preconditionAllowed : 3|1@1+ (1,0) [0|0] "" Vector__XXX
 SG_ BMS_notEnoughPowerForSupport : 2|1@1+ (1,0) [0|0] "" Vector__XXX
 SG_ BMS_notEnoughPowerForDrive : 1|1@1+ (1,0) [0|0] "" Vector__XXX
 SG_ BMS_hvacPowerRequest : 0|1@1+ (1,0) [0|0] "" Vector__XXX

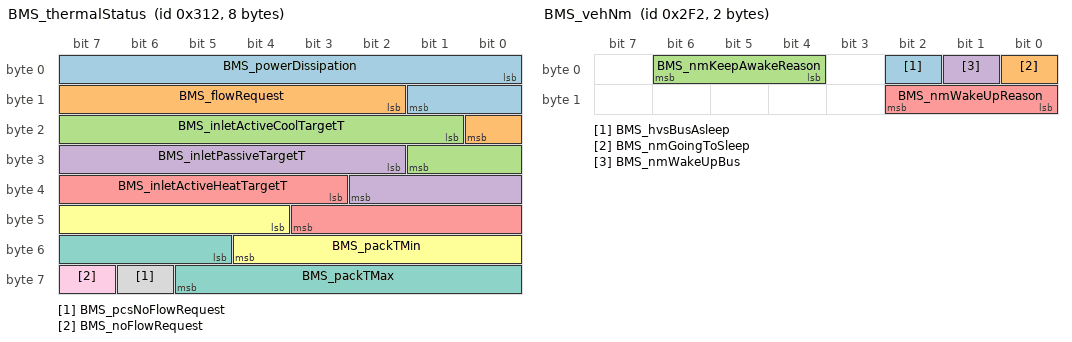
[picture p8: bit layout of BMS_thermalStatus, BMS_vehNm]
BO_ 786 BMS_thermalStatus: 8 VEH
 SG_ BMS_powerDissipation: 0|10@1+ (0.02,0) [0|0] "kW" X
 SG_ BMS_flowRequest: 10|7@1+ (0.3,0) [0|0] "LPM" X
 SG_ BMS_inletActiveCoolTargetT: 17|9@1+ (0.25,-25) [0|0] "DegC" X
 SG_ BMS_inletPassiveTargetT: 26|9@1+ (0.25,-25) [0|0] "DegC" X
 SG_ BMS_inletActiveHeatTargetT: 35|9@1+ (0.25,-25) [0|0] "DegC" X
 SG_ BMS_packTMin : 44|9@1+ (0.25,-25) [-25|100] "DegC" X
 SG_ BMS_packTMax : 53|9@1+ (0.25,-25) [-25|100] "DegC" X
 SG_ BMS_pcsNoFlowRequest: 62|1@1+ (1,0) [0|0] "" X
 SG_ BMS_noFlowRequest: 63|1@1+ (1,0) [0|0] "" X

BO_ 754 BMS_vehNm: 2 VEH
 SG_ BMS_hvsBusAsleep: 2|1@1+ (1,0) [0|0] "" X
 SG_ BMS_nmGoingToSleep: 0|1@1+ (1,0) [0|0] "" X
 SG_ BMS_nmKeepAwakeReason: 4|3@1+ (1,0) [0|0] "" X
 SG_ BMS_nmWakeUpBus: 1|1@1+ (1,0) [0|0] "" X
 SG_ BMS_nmWakeUpReason: 8|3@1+ (1,0) [0|0] "" X

BO_ 1132 CC_alertMatrix1: 8 VEH
 SG_ CC_a001_gndMonIntrptLineSide: 0|1@1+ (1,0) [0|0] "" X
 SG_ CC_a002_gndMonIntrptLoadSide: 1|1@1+ (1,0) [0|0] "" X
 SG_ CC_a003_CCIDTripped: 2|1@1+ (1,0) [0|0] "" X
 SG_ CC_a004_CCIDSelfTestFault: 3|1@1+ (1,0) [0|0] "" X
 SG_ CC_a005_groundedNeutral: 4|1@1+ (1,0) [0|0] "" X
 SG_ CC_a006_inputOverCurrent: 5|1@1+ (1,0) [0|0] "" X
 SG_ CC_a007_inputOverVoltage: 6|1@1+ (1,0) [0|0] "" X
 SG_ CC_a008_inputUnderVoltage: 7|1@1+ (1,0) [0|0] "" X
 SG_ CC_a009_inputMiswired: 8|1@1+ (1,0) [0|0] "" X
 SG_ CC_a010_contactorWelded: 9|1@1+ (1,0) [0|0] "" X
 SG_ CC_a011_ambientOT: 10|1@1+ (1,0) [0|0] "" X
 SG_ CC_a012_wallPlugOT: 11|1@1+ (1,0) [0|0] "" X
 SG_ CC_a013_vehConnOT: 12|1@1+ (1,0) [0|0] "" X
 SG_ CC_a014_mcuSelfTestFault: 13|1@1+ (1,0) [0|0] "" X
 SG_ CC_a015_PilotAFault: 14|1@1+ (1,0) [0|0] "" X
 SG_ CC_a016_PilotBFault: 15|1@1+ (1,0) [0|0] "" X
 SG_ CC_a017_PilotCFault: 16|1@1+ (1,0) [0|0] "" X
 SG_ CC_a018_PilotDFault: 17|1@1+ (1,0) [0|0] "" X
 SG_ CC_a019_proxDisconnected: 18|1@1+ (1,0) [0|0] "" X
 SG_ CC_a020_3vRailIncorrect: 19|1@1+ (1,0) [0|0] "" X
 SG_ CC_a021_CB_noMaster: 20|1@1+ (1,0) [0|0] "" X
 SG_ CC_a022_CB_tooManyMasters: 21|1@1+ (1,0) [0|0] "" X
 SG_ CC_a023_CB_tooManySlaves: 22|1@1+ (1,0) [0|0] "" X
 SG_ CC_a024_CB_masterISetTooLow: 23|1@1+ (1,0) [0|0] "" X
 SG_ CC_a025_evseTemp: 24|1@1+ (1,0) [0|0] "" X
 SG_ CC_a026_wallPlugTemp: 25|1@1+ (1,0) [0|0] "" X
 SG_ CC_a027_vehicleHandleTemp: 26|1@1+ (1,0) [0|0] "" X
 SG_ CC_a028_CB_rotarySelect: 27|1@1+ (1,0) [0|0] "" X
 SG_ CC_a029_PilotFFault: 28|1@1+ (1,0) [0|0] "" X
 SG_ CC_a030_masterSlaveMismatch: 29|1@1+ (1,0) [0|0] "" X

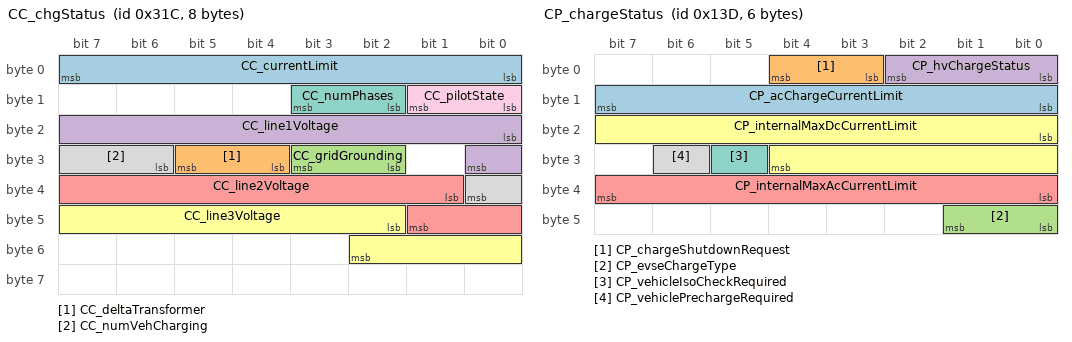
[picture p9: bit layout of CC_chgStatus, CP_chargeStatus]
BO_ 796 CC_chgStatus: 8 VEH
 SG_ CC_currentLimit: 0|8@1+ (0.5,0) [0|0] "A" X
 SG_ CC_deltaTransformer: 28|2@1+ (1,0) [0|0] "" X
 SG_ CC_gridGrounding: 26|2@1+ (1,0) [0|0] "" X
 SG_ CC_line1Voltage: 16|9@1+ (1,0) [0|0] "V" X
 SG_ CC_line2Voltage: 33|9@1+ (1,0) [0|0] "V" X
 SG_ CC_line3Voltage: 42|9@1+ (1,0) [0|0] "V" X
 SG_ CC_numPhases: 10|2@1+ (1,0) [0|0] "" X
 SG_ CC_numVehCharging: 30|3@1+ (1,0) [0|0] "" X
 SG_ CC_pilotState: 8|2@1+ (1,0) [0|0] "" X

BO_ 797 CC_chgStatus2: 8 VEH
 SG_ CC_chgStatus2Index M: 0|8@1+ (1,0) [0|0] "" X
 SG_ CC_buttonState m0: 8|1@1+ (1,0) [0|0] "" X

BO_ 812 CC_logData: 8 VEH
 SG_ CC_logIndex M: 0|8@1+ (1,0) [0|0] "" X
 SG_ CC_activeConnectorID m0: 8|8@1+ (1,0) [0|0] "" X
 SG_ CC_temperature1 m0: 16|8@1- (1,88) [0|0] "DegC" X
 SG_ CC_temperature2 m0: 24|8@1- (1,88) [0|0] "DegC" X
 SG_ CC_temperature3 m0: 32|8@1- (1,88) [0|0] "DegC" X
 SG_ CC_contactor1Closed m0: 40|2@1+ (1,0) [0|0] "" X
 SG_ CC_contactor2Closed m0: 42|2@1+ (1,0) [0|0] "" X
 SG_ CC_temperature4 m0: 44|8@1- (1,88) [0|0] "DegC" X
 SG_ CC_conn1Current m1: 8|8@1+ (0.5,0) [0|0] "A" X
 SG_ CC_conn2Current m2: 8|8@1+ (0.5,0) [0|0] "A" X
 SG_ CC_conn3Current m3: 8|8@1+ (0.5,0) [0|0] "A" X
 SG_ CC_conn4Current m4: 8|8@1+ (0.5,0) [0|0] "A" X
 SG_ CC_lifetimei2t m10: 32|32@1+ (0.1,0) [0|0] "A2h" X
 SG_ CC_lifetimeCtrCycles m11: 8|28@1+ (1,0) [0|0] "" X
 SG_ CC_lifetimeCtrCyclesLoaded m11: 36|28@1+ (1,0) [0|0] "" X
 SG_ CC_lifetimeAlertCount m12: 8|28@1+ (1,0) [0|0] "" X
 SG_ CC_lifetimVEHermalFoldbacks m12: 36|28@1+ (1,0) [0|0] "" X
 SG_ CC_lifetimeAvgStartupTemp m13: 36|28@1- (0.1,0) [0|0] "degC" X

BO_ 867 CMP_info: 8 VEH
 SG_ CMP_infoIndex M: 0|8@1+ (1,0) [0|0] "" X
 SG_ CMP_infoBuildType m10: 8|8@1+ (1,0) [0|0] "" X
 SG_ CMP_infoBuildConfigId m10: 16|16@1+ (1,0) [0|0] "" X
 SG_ CMP_infoHardwareId m10: 32|16@1+ (1,0) [0|0] "" X
 SG_ CMP_infoComponentId m10: 48|16@1+ (1,0) [0|0] "" X
 SG_ CMP_infoPcbaId m11: 16|8@1+ (1,0) [0|0] "" X
 SG_ CMP_infoAssemblyId m11: 24|8@1+ (1,0) [0|0] "" X
 SG_ CMP_infoUsageId m11: 32|16@1+ (1,0) [0|0] "" X
 SG_ CMP_infoSubUsageId m11: 48|16@1+ (1,0) [0|0] "" X
 SG_ CMP_infoBootUdsProtoVersion m20: 8|8@1+ (1,0) [0|0] "" X
 SG_ CMP_infoBootCrc m20: 32|32@1+ (1,0) [0|0] "" X
 SG_ CMP_infoPlatformType m13: 8|8@1+ (1,0) [0|0] "" X
 SG_ CMP_infoAppCrc m13: 32|32@1+ (1,0) [0|0] "" X

BO_ 798 CP_alertMatrix: 8 Vector__XXX
 SG_ CP_a060_lostCommsPCS m0 : 63|1@1+ (1,0) [0|0] "" Vector__XXX
 SG_ CP_a120_comboAdapterFoldback m1 : 63|1@1+ (1,0) [0|0] "" Vector__XXX
 SG_ CP_a059_swcanError m0 : 62|1@1+ (1,0) [0|0] "" Vector__XXX
 SG_ CP_a119_plcTransmitFailure m1 : 62|1@1+ (1,0) [0|0] "" Vector__XXX
 SG_ CP_a179_evseCommsTlsError m2 : 62|1@1+ (1,0) [0|0] "" Vector__XXX
 SG_ CP_a058_acChargeRetryPending m0 : 61|1@1+ (1,0) [0|0] "" Vector__XXX
 SG_ CP_a118_iecComboLockUp m1 : 61|1@1+ (1,0) [0|0] "" Vector__XXX
 SG_ CP_a178_v2xPlcCommsFault m2 : 61|1@1+ (1,0) [0|0] "" Vector__XXX
 SG_ CP_a057_ccs1AdapterBtnPress m0 : 60|1@1+ (1,0) [0|0] "" Vector__XXX
 SG_ CP_a117_inletHeaterUnableToRegul m1 : 60|1@1+ (1,0) [0|0] "" Vector__XXX
 SG_ CP_a177_incompatibleV2lDeviceDet m2 : 60|1@1+ (1,0) [0|0] "" Vector__XXX
 SG_ CP_a056_proxDisconnected m0 : 59|1@1+ (1,0) [0|0] "" Vector__XXX
 SG_ CP_a116_misconfigurationDetected m1 : 59|1@1+ (1,0) [0|0] "" Vector__XXX
 SG_ CP_a176_lostCommsV2l m2 : 59|1@1+ (1,0) [0|0] "" Vector__XXX
 SG_ CP_a055_chargeStoppedNoPilot m0 : 58|1@1+ (1,0) [0|0] "" Vector__XXX
 SG_ CP_a115_unexpectedTcan1145State m1 : 58|1@1+ (1,0) [0|0] "" Vector__XXX
 SG_ CP_a175_fwdedMsgDropped m2 : 58|1@1+ (1,0) [0|0] "" Vector__XXX
 SG_ CP_a054_cableNotSecured m0 : 57|1@1+ (1,0) [0|0] "" Vector__XXX
 SG_ CP_a114_ccsEvseFailed m1 : 57|1@1+ (1,0) [0|0] "" Vector__XXX
 SG_ CP_a174_fwdedMsgLoadWarning m2 : 57|1@1+ (1,0) [0|0] "" Vector__XXX
 SG_ CP_a053_proxLatchedNoPilot m0 : 56|1@1+ (1,0) [0|0] "" Vector__XXX
 SG_ CP_a113_inletHeaterShortCircuit m1 : 56|1@1+ (1,0) [0|0] "" Vector__XXX
 SG_ CP_a173_coverOpenAcChgBlocked m2 : 56|1@1+ (1,0) [0|0] "" Vector__XXX
 SG_ CP_a052_chademoNotSupported m0 : 55|1@1+ (1,0) [0|0] "" Vector__XXX
 SG_ CP_a112_inletHeaterIrrationalTem m1 : 55|1@1+ (1,0) [0|0] "" Vector__XXX
 SG_ CP_a172_triggerOdin m2 : 55|1@1+ (1,0) [0|0] "" Vector__XXX
 SG_ CP_a051_doorInductiveSensorMIA m0 : 54|1@1+ (1,0) [0|0] "" Vector__XXX
 SG_ CP_a111_inletHeaterUnableToHeat m1 : 54|1@1+ (1,0) [0|0] "" Vector__XXX
 SG_ CP_a050_latchNotConnected m0 : 53|1@1+ (1,0) [0|0] "" Vector__XXX
 SG_ CP_a110_thermalVelocityHigh m1 : 53|1@1+ (1,0) [0|0] "" Vector__XXX
 SG_ CP_a049_multipleCablesDetected m0 : 52|1@1+ (1,0) [0|0] "" Vector__XXX
 SG_ CP_a109_thermistorIrrational m1 : 52|1@1+ (1,0) [0|0] "" Vector__XXX
 SG_ CP_a048_lostCommsUI m0 : 51|1@1+ (1,0) [0|0] "" Vector__XXX
 SG_ CP_a108_chademoOvertempFault m1 : 51|1@1+ (1,0) [0|0] "" Vector__XXX
 SG_ CP_a168_pilotHSDFaulted m2 : 51|1@1+ (1,0) [0|0] "" Vector__XXX
 SG_ CP_a047_lostCommsVCFRONT m0 : 50|1@1+ (1,0) [0|0] "" Vector__XXX
 SG_ CP_a107_chademoFoldbackActive m1 : 50|1@1+ (1,0) [0|0] "" Vector__XXX
 SG_ CP_a167_doorIdIrrational m2 : 50|1@1+ (1,0) [0|0] "" Vector__XXX
 SG_ CP_a046_lostCommsEVSE m0 : 49|1@1+ (1,0) [0|0] "" Vector__XXX
 SG_ CP_a106_uhfReceiverReset m1 : 49|1@1+ (1,0) [0|0] "" Vector__XXX
 SG_ CP_a166_faultLineMismatchDetecte m2 : 49|1@1+ (1,0) [0|0] "" Vector__XXX
 SG_ CP_a045_lostCommsVCSEC m0 : 48|1@1+ (1,0) [0|0] "" Vector__XXX
 SG_ CP_a105_hwUnableToSleep m1 : 48|1@1+ (1,0) [0|0] "" Vector__XXX
 SG_ CP_a165_proxWiggleDetected m2 : 48|1@1+ (1,0) [0|0] "" Vector__XXX
 SG_ CP_a044_lostCommsHVP m0 : 47|1@1+ (1,0) [0|0] "" Vector__XXX
 SG_ CP_a104_uhfResetSuccessful m1 : 47|1@1+ (1,0) [0|0] "" Vector__XXX
 SG_ CP_a164_latchRedisengageRequeste m2 : 47|1@1+ (1,0) [0|0] "" Vector__XXX
 SG_ CP_a043_doorPotIrrational m0 : 46|1@1+ (1,0) [0|0] "" Vector__XXX
 SG_ CP_a103_proximityPeDisconnected m1 : 46|1@1+ (1,0) [0|0] "" Vector__XXX
 SG_ CP_a163_coverOpenDcChgBlocked m2 : 46|1@1+ (1,0) [0|0] "" Vector__XXX
 SG_ CP_a042_doorAssemblyBroken m0 : 45|1@1+ (1,0) [0|0] "" Vector__XXX
 SG_ CP_a102_wcOvertempFault m1 : 45|1@1+ (1,0) [0|0] "" Vector__XXX
 SG_ CP_a162_pilotEdgeDetectionFailed m2 : 45|1@1+ (1,0) [0|0] "" Vector__XXX
 SG_ CP_a041_doorSensorUnplugged m0 : 44|1@1+ (1,0) [0|0] "" Vector__XXX
 SG_ CP_a101_wcFoldbackActive m1 : 44|1@1+ (1,0) [0|0] "" Vector__XXX
 SG_ CP_a161_badPilotDiodeDetectedCN m2 : 44|1@1+ (1,0) [0|0] "" Vector__XXX
 SG_ CP_a040_doNotUse m0 : 43|1@1+ (1,0) [0|0] "" Vector__XXX
 SG_ CP_a100_inletHarnessIdIrrational m1 : 43|1@1+ (1,0) [0|0] "" Vector__XXX
 SG_ CP_a160_latchDisengageInDcCharge m2 : 43|1@1+ (1,0) [0|0] "" Vector__XXX
 SG_ CP_a039_latchMovement_2 m0 : 42|1@1+ (1,0) [0|0] "" Vector__XXX
 SG_ CP_a099_cableStateUnknown m1 : 42|1@1+ (1,0) [0|0] "" Vector__XXX
 SG_ CP_a159_swcanHealthCheckFailed m2 : 42|1@1+ (1,0) [0|0] "" Vector__XXX
 SG_ CP_a038_latchNotBlocking m0 : 41|1@1+ (1,0) [0|0] "" Vector__XXX
 SG_ CP_a098_proximityWake m1 : 41|1@1+ (1,0) [0|0] "" Vector__XXX
 SG_ CP_a158_doorCloseRateLimiter m2 : 41|1@1+ (1,0) [0|0] "" Vector__XXX
 SG_ CP_a037_latchNotEngaged m0 : 40|1@1+ (1,0) [0|0] "" Vector__XXX
 SG_ CP_a097_modeTransitionFailure m1 : 40|1@1+ (1,0) [0|0] "" Vector__XXX
 SG_ CP_a157_doorOpenRateLimiter m2 : 40|1@1+ (1,0) [0|0] "" Vector__XXX
 SG_ CP_a036_latchNotDisengaged m0 : 39|1@1+ (1,0) [0|0] "" Vector__XXX
 SG_ CP_a096_pilotWake m1 : 39|1@1+ (1,0) [0|0] "" Vector__XXX
 SG_ CP_a156_gbdcPrechargingConcern m2 : 39|1@1+ (1,0) [0|0] "" Vector__XXX
 SG_ CP_a035_latchMovement_1 m0 : 38|1@1+ (1,0) [0|0] "" Vector__XXX
 SG_ CP_a095_thermalDcLimitActive m1 : 38|1@1+ (1,0) [0|0] "" Vector__XXX
 SG_ CP_a155_hallPresenceRationality m2 : 38|1@1+ (1,0) [0|0] "" Vector__XXX
 SG_ CP_a034_calibrationIncomplete m0 : 37|1@1+ (1,0) [0|0] "" Vector__XXX
 SG_ CP_a094_inductiveResetSuccessful m1 : 37|1@1+ (1,0) [0|0] "" Vector__XXX
 SG_ CP_a154_acChargingStoppedOT m2 : 37|1@1+ (1,0) [0|0] "" Vector__XXX
 SG_ CP_a033_spiOpen m0 : 36|1@1+ (1,0) [0|0] "" Vector__XXX
 SG_ CP_a093_modemLoadedWithReset m1 : 36|1@1+ (1,0) [0|0] "" Vector__XXX
 SG_ CP_a153_thermalAcLimitActive m2 : 36|1@1+ (1,0) [0|0] "" Vector__XXX
 SG_ CP_a032_doorOpenExpectedClosed m0 : 35|1@1+ (1,0) [0|0] "" Vector__XXX
 SG_ CP_a092_modemAppLoadFailed m1 : 35|1@1+ (1,0) [0|0] "" Vector__XXX
 SG_ CP_a152_pilotEdgeDetectionFailed m2 : 35|1@1+ (1,0) [0|0] "" Vector__XXX
 SG_ CP_a031_doorClosedCommandedOpen m0 : 34|1@1+ (1,0) [0|0] "" Vector__XXX
 SG_ CP_a091_wrongSuperchargerHandle m1 : 34|1@1+ (1,0) [0|0] "" Vector__XXX
 SG_ CP_a151_badPilotDiodeDetected m2 : 34|1@1+ (1,0) [0|0] "" Vector__XXX
 SG_ CP_a030_busOff m0 : 33|1@1+ (1,0) [0|0] "" Vector__XXX
 SG_ CP_a090_ccsEvseLowIso m1 : 33|1@1+ (1,0) [0|0] "" Vector__XXX
 SG_ CP_a150_railToggleTimeout m2 : 33|1@1+ (1,0) [0|0] "" Vector__XXX
 SG_ CP_a029_doorClosedProxPilot m0 : 32|1@1+ (1,0) [0|0] "" Vector__XXX
 SG_ CP_a089_plcConfigMismatch m1 : 32|1@1+ (1,0) [0|0] "" Vector__XXX
 SG_ CP_a149_pilotPeriodInvalid m2 : 32|1@1+ (1,0) [0|0] "" Vector__XXX
 SG_ CP_a028_insertEnableMismatch m0 : 31|1@1+ (1,0) [0|0] "" Vector__XXX
 SG_ CP_a088_dcTempModelDeviation m1 : 31|1@1+ (1,0) [0|0] "" Vector__XXX
 SG_ CP_a148_bldcTachFeedbackMia m2 : 31|1@1+ (1,0) [0|0] "" Vector__XXX
 SG_ CP_a027_doorSensorOutOfSpec m0 : 30|1@1+ (1,0) [0|0] "" Vector__XXX
 SG_ CP_a087_dcTempModelFault m1 : 30|1@1+ (1,0) [0|0] "" Vector__XXX
 SG_ CP_a147_inductiveRecoveredMia m2 : 30|1@1+ (1,0) [0|0] "" Vector__XXX
 SG_ CP_a026_networkManagement m0 : 29|1@1+ (1,0) [0|0] "" Vector__XXX
 SG_ CP_a086_dcPinTempIrrational m1 : 29|1@1+ (1,0) [0|0] "" Vector__XXX
 SG_ CP_a146_ccsEvseMalfunction m2 : 29|1@1+ (1,0) [0|0] "" Vector__XXX
 SG_ CP_a206_peToChassisDisconnected m3 : 29|1@1+ (1,0) [0|0] "" Vector__XXX
 SG_ CP_a025_ledsOC m0 : 28|1@1+ (1,0) [0|0] "" Vector__XXX
 SG_ CP_a085_dcPinTempFaulted m1 : 28|1@1+ (1,0) [0|0] "" Vector__XXX
 SG_ CP_a145_modemAppLoadFailedNA m2 : 28|1@1+ (1,0) [0|0] "" Vector__XXX
 SG_ CP_a205_doorPositionUndetectable m3 : 28|1@1+ (1,0) [0|0] "" Vector__XXX
 SG_ CP_a024_ledsUC m0 : 27|1@1+ (1,0) [0|0] "" Vector__XXX
 SG_ CP_a084_proxPeDisconnected_gb m1 : 27|1@1+ (1,0) [0|0] "" Vector__XXX
 SG_ CP_a144_nvmInitFailed m2 : 27|1@1+ (1,0) [0|0] "" Vector__XXX
 SG_ CP_a204_sdpAttemptsFailed2 m3 : 27|1@1+ (1,0) [0|0] "" Vector__XXX
 SG_ CP_a023_gbdcSessionFailed m0 : 26|1@1+ (1,0) [0|0] "" Vector__XXX
 SG_ CP_a083_watchdogTraceData m1 : 26|1@1+ (1,0) [0|0] "" Vector__XXX
 SG_ CP_a143_unsupportedChargeAdapter m2 : 26|1@1+ (1,0) [0|0] "" Vector__XXX
 SG_ CP_a203_evseCommTimeout2 m3 : 26|1@1+ (1,0) [0|0] "" Vector__XXX
 SG_ CP_a022_zeroVuv m0 : 25|1@1+ (1,0) [0|0] "" Vector__XXX
 SG_ CP_a082_powerOnReset m1 : 25|1@1+ (1,0) [0|0] "" Vector__XXX
 SG_ CP_a142_gbdcScConnFault m2 : 25|1@1+ (1,0) [0|0] "" Vector__XXX
 SG_ CP_a202_failedToEstablishV2gComm m3 : 25|1@1+ (1,0) [0|0] "" Vector__XXX
 SG_ CP_a021_zeroVov m0 : 24|1@1+ (1,0) [0|0] "" Vector__XXX
 SG_ CP_a081_swException m1 : 24|1@1+ (1,0) [0|0] "" Vector__XXX
 SG_ CP_a141_chademoAdapterFault m2 : 24|1@1+ (1,0) [0|0] "" Vector__XXX
 SG_ CP_a201_uhfDoorOpenRepeatedlyOve m3 : 24|1@1+ (1,0) [0|0] "" Vector__XXX
 SG_ CP_a020_threeVuv m0 : 23|1@1+ (1,0) [0|0] "" Vector__XXX
 SG_ CP_a080_taskStackOverflow m1 : 23|1@1+ (1,0) [0|0] "" Vector__XXX
 SG_ CP_a140_superchargerFaulted m2 : 23|1@1+ (1,0) [0|0] "" Vector__XXX
 SG_ CP_d200_pilotCircuitIssue m3 : 23|1@1+ (1,0) [0|0] "" Vector__XXX
 SG_ CP_a019_threeVov m0 : 22|1@1+ (1,0) [0|0] "" Vector__XXX
 SG_ CP_a079_cableNotSecuredCold m1 : 22|1@1+ (1,0) [0|0] "" Vector__XXX
 SG_ CP_a139_pilotFaulted m2 : 22|1@1+ (1,0) [0|0] "" Vector__XXX
 SG_ CP_d199_hardwareConfigMismatch m3 : 22|1@1+ (1,0) [0|0] "" Vector__XXX
 SG_ CP_a018_fiveVuv m0 : 21|1@1+ (1,0) [0|0] "" Vector__XXX
 SG_ CP_a078_latchNotDisengagedCold m1 : 21|1@1+ (1,0) [0|0] "" Vector__XXX
 SG_ CP_a138_swcanCommsAcEvseFaulted m2 : 21|1@1+ (1,0) [0|0] "" Vector__XXX
 SG_ CP_d198_couplerTempSensorCircuit m3 : 21|1@1+ (1,0) [0|0] "" Vector__XXX
 SG_ CP_a017_fiveVov m0 : 20|1@1+ (1,0) [0|0] "" Vector__XXX
 SG_ CP_a077_invalidMacAddress m1 : 20|1@1+ (1,0) [0|0] "" Vector__XXX
 SG_ CP_a137_plcForwardError m2 : 20|1@1+ (1,0) [0|0] "" Vector__XXX
 SG_ CP_d197_doorSensorCircuitErratic m3 : 20|1@1+ (1,0) [0|0] "" Vector__XXX
 SG_ CP_a016_apsVuv m0 : 19|1@1+ (1,0) [0|0] "" Vector__XXX
 SG_ CP_a076_LDC1612errorWatchdog m1 : 19|1@1+ (1,0) [0|0] "" Vector__XXX
 SG_ CP_a136_sdpSideReqFailed m2 : 19|1@1+ (1,0) [0|0] "" Vector__XXX
 SG_ CP_d196_doorActuatorPerformanceI m3 : 19|1@1+ (1,0) [0|0] "" Vector__XXX
 SG_ CP_a015_apsVov m0 : 18|1@1+ (1,0) [0|0] "" Vector__XXX
 SG_ CP_a075_v2gCommsFailure m1 : 18|1@1+ (1,0) [0|0] "" Vector__XXX
 SG_ CP_a135_sdpAttemptsFailed m2 : 18|1@1+ (1,0) [0|0] "" Vector__XXX
 SG_ CP_d195_couplerLockActuatorIssue m3 : 18|1@1+ (1,0) [0|0] "" Vector__XXX
 SG_ CP_a014_lostCommsCHG m0 : 17|1@1+ (1,0) [0|0] "" Vector__XXX
 SG_ CP_a074_failedToEstablishV2gComm m1 : 17|1@1+ (1,0) [0|0] "" Vector__XXX
 SG_ CP_a134_plcModemNotExpected m2 : 17|1@1+ (1,0) [0|0] "" Vector__XXX
 SG_ CP_d194_proximityCircuitRangeIss m3 : 17|1@1+ (1,0) [0|0] "" Vector__XXX
 SG_ CP_a013_lostCommsGTW m0 : 16|1@1+ (1,0) [0|0] "" Vector__XXX
 SG_ CP_a073_iecComboShutdown m1 : 16|1@1+ (1,0) [0|0] "" Vector__XXX
 SG_ CP_a133_proxNeverLatched m2 : 16|1@1+ (1,0) [0|0] "" Vector__XXX
 SG_ CP_d193_proximityCircuitErratic m3 : 16|1@1+ (1,0) [0|0] "" Vector__XXX
 SG_ CP_a012_ledDriver m0 : 15|1@1+ (1,0) [0|0] "" Vector__XXX
 SG_ CP_a072_v2gEvccTimeout m1 : 15|1@1+ (1,0) [0|0] "" Vector__XXX
 SG_ CP_a132_contractAuthTimeout m2 : 15|1@1+ (1,0) [0|0] "" Vector__XXX
 SG_ CP_d192_couplerTempHigh m3 : 15|1@1+ (1,0) [0|0] "" Vector__XXX
 SG_ CP_a011_eeprom m0 : 14|1@1+ (1,0) [0|0] "" Vector__XXX
 SG_ CP_a071_exiDecodeFailure m1 : 14|1@1+ (1,0) [0|0] "" Vector__XXX
 SG_ CP_a131_evseCommTimeout m2 : 14|1@1+ (1,0) [0|0] "" Vector__XXX
 SG_ CP_d191_latchConnectionIssue m3 : 14|1@1+ (1,0) [0|0] "" Vector__XXX
 SG_ CP_a010_pilotRationality m0 : 13|1@1+ (1,0) [0|0] "" Vector__XXX
 SG_ CP_a070_doorInductiveSensorReset m1 : 13|1@1+ (1,0) [0|0] "" Vector__XXX
 SG_ CP_a130_bldcDriverCommsRecovered m2 : 13|1@1+ (1,0) [0|0] "" Vector__XXX
 SG_ CP_d190_backCoverCircuitIssue m3 : 13|1@1+ (1,0) [0|0] "" Vector__XXX
 SG_ CP_a009_coverOpenAllChgBlocked m0 : 12|1@1+ (1,0) [0|0] "" Vector__XXX
 SG_ CP_a069_doorInductiveSensorError m1 : 12|1@1+ (1,0) [0|0] "" Vector__XXX
 SG_ CP_a129_bldcDriverCommsFailed m2 : 12|1@1+ (1,0) [0|0] "" Vector__XXX
 SG_ CP_a189_resistivePresenceRationa m3 : 12|1@1+ (1,0) [0|0] "" Vector__XXX
 SG_ CP_a008_memoryError m0 : 11|1@1+ (1,0) [0|0] "" Vector__XXX
 SG_ CP_a068_doorSensorMismatch m1 : 11|1@1+ (1,0) [0|0] "" Vector__XXX
 SG_ CP_a128_lostCommsVC m2 : 11|1@1+ (1,0) [0|0] "" Vector__XXX
 SG_ CP_a188_v2lEvseRequiresUpdate m3 : 11|1@1+ (1,0) [0|0] "" Vector__XXX
 SG_ CP_a007_watchdog m0 : 10|1@1+ (1,0) [0|0] "" Vector__XXX
 SG_ CP_a067_gbdcConnFault m1 : 10|1@1+ (1,0) [0|0] "" Vector__XXX
 SG_ CP_a127_lostCommsHVLINK m2 : 10|1@1+ (1,0) [0|0] "" Vector__XXX
 SG_ CP_a187_highStackUsage m3 : 10|1@1+ (1,0) [0|0] "" Vector__XXX
 SG_ CP_a006_lostCommsBMS m0 : 9|1@1+ (1,0) [0|0] "" Vector__XXX
 SG_ CP_a066_proxLatchedIdlePilot m1 : 9|1@1+ (1,0) [0|0] "" Vector__XXX
 SG_ CP_a126_wakeOnUhfFault m2 : 9|1@1+ (1,0) [0|0] "" Vector__XXX
 SG_ CP_a186_spiDmaFailure m3 : 9|1@1+ (1,0) [0|0] "" Vector__XXX
 SG_ CP_a005_gbdcLiveDisconnect m0 : 8|1@1+ (1,0) [0|0] "" Vector__XXX
 SG_ CP_a065_selfTestFailed m1 : 8|1@1+ (1,0) [0|0] "" Vector__XXX
 SG_ CP_a125_unexpectedLVJuiceState m2 : 8|1@1+ (1,0) [0|0] "" Vector__XXX
 SG_ CP_a185_pncAuthRejection m3 : 8|1@1+ (1,0) [0|0] "" Vector__XXX
 SG_ CP_a004_proximityRationality m0 : 7|1@1+ (1,0) [0|0] "" Vector__XXX
 SG_ CP_a064_superchargingBlocked m1 : 7|1@1+ (1,0) [0|0] "" Vector__XXX
 SG_ CP_a124_ivledFault m2 : 7|1@1+ (1,0) [0|0] "" Vector__XXX
 SG_ CP_a184_certChangeEvent m3 : 7|1@1+ (1,0) [0|0] "" Vector__XXX
 SG_ CP_a003_canError m0 : 6|1@1+ (1,0) [0|0] "" Vector__XXX
 SG_ CP_a063_scUpdateInProgress m1 : 6|1@1+ (1,0) [0|0] "" Vector__XXX
 SG_ CP_a123_latchPotIrrational m2 : 6|1@1+ (1,0) [0|0] "" Vector__XXX
 SG_ CP_a183_certManagerError m3 : 6|1@1+ (1,0) [0|0] "" Vector__XXX
 SG_ CP_a002_canTx m0 : 5|1@1+ (1,0) [0|0] "" Vector__XXX
 SG_ CP_a062_scOutOfService m1 : 5|1@1+ (1,0) [0|0] "" Vector__XXX
 SG_ CP_a122_plcModemFailure m2 : 5|1@1+ (1,0) [0|0] "" Vector__XXX
 SG_ CP_a182_pncdCommsError m3 : 5|1@1+ (1,0) [0|0] "" Vector__XXX
 SG_ CP_a001_canRx m0 : 4|1@1+ (1,0) [0|0] "" Vector__XXX
 SG_ CP_a061_uhfReceiverMIA m1 : 4|1@1+ (1,0) [0|0] "" Vector__XXX
 SG_ CP_a121_PLCRLY_lostCommsCP m2 : 4|1@1+ (1,0) [0|0] "" Vector__XXX
 SG_ CP_matrixIndex M : 0|4@1+ (1,0) [0|0] "" Vector__XXX

BO_ 317 CP_chargeStatus: 6 VEH
 SG_ CP_acChargeCurrentLimit : 8|8@1+ (0.5,0) [0|127.5] "A"  Receiver
 SG_ CP_chargeShutdownRequest : 3|2@1+ (1,0) [0|2] ""  Receiver
 SG_ CP_evseChargeType : 40|2@1+ (1,0) [0|2] ""  Receiver
 SG_ CP_hvChargeStatus : 0|3@1+ (1,0) [0|6] ""  Receiver
 SG_ CP_internalMaxAcCurrentLimit : 32|8@1+ (0.5,0) [0|127.5] "A"  Receiver
 SG_ CP_internalMaxDcCurrentLimit : 16|13@1+ (0.146502,0) [0|1200] "A"  Receiver
 SG_ CP_vehicleIsoCheckRequired : 29|1@1+ (1,0) [0|1] ""  Receiver
 SG_ CP_vehiclePrechargeRequired : 30|1@1+ (1,0) [0|1] ""  Receiver

BO_ 541 CP_evseStatus: 8 VEH
 SG_ CP_acChargeRetriesExceeded: 41|1@1+ (1,0) [0|0] "" X
 SG_ CP_acChargeState: 60|2@1+ (1,0) [0|0] "" X
 SG_ CP_acNumRetries: 42|2@1+ (1,0) [0|0] "" X
 SG_ CP_cableCurrentLimit: 24|7@1+ (1,0) [0|0] "A" X
 SG_ CP_cableType: 16|3@1+ (1,0) [0|0] "" X
 SG_ CP_digitalCommsAttempts: 32|2@1+ (1,0) [0|0] "" X
 SG_ CP_digitalCommsEstablished: 37|1@1+ (1,0) [0|0] "" X
 SG_ CP_evseAccept: 0|1@1+ (1,0) [0|0] "" X
 SG_ CP_evseChargeType: 38|2@1+ (1,0) [0|0] "" X
 SG_ CP_evseRequest: 1|1@1+ (1,0) [0|0] "" X
 SG_ CP_gbState: 48|5@1+ (1,0) [0|0] "" X
 SG_ CP_gbdcChargeAttempts: 58|2@1+ (1,0) [0|0] "" X
 SG_ CP_gbdcFailureReason: 56|2@1+ (1,0) [0|0] "" X
 SG_ CP_gbdcStopChargeReason: 53|3@1+ (1,0) [0|0] "" X
 SG_ CP_lineVoltageRequested: 2|1@1+ (1,0) [0|0] "" X
 SG_ CP_pilot: 5|3@1+ (1,0) [0|0] "" X
 SG_ CP_pilotCurrent: 8|8@1+ (0.5,0) [0|0] "A" X
 SG_ CP_proximity: 3|2@1+ (1,0) [0|0] "" X
 SG_ CP_stopChargeRequest: 40|1@1+ (1,0) [0|0] "" X
 SG_ CP_teslaSwcanState: 34|3@1+ (1,0) [0|0] "" X
 SG_ CP_vehiclePrechargeRequired: 44|1@1+ (1,0) [0|0] "" X

BO_ 1342 CP_info: 8 VEH
 SG_ CP_infoIndex M: 0|8@1+ (1,0) [0|0] "" X
 SG_ CP_buildType m10: 8|3@1+ (1,0) [0|0] "" X
 SG_ CP_buildConfigId m10: 16|16@1+ (1,0) [0|0] "" X
 SG_ CP_hardwareId m10: 32|16@1+ (1,0) [0|0] "" X
 SG_ CP_componentId m10: 48|16@1+ (1,0) [0|0] "" X
 SG_ CP_pcbaId m11: 16|8@1+ (1,0) [0|0] "" X
 SG_ CP_assemblyId m11: 24|8@1+ (1,0) [0|0] "" X
 SG_ CP_usageId m11: 32|16@1+ (1,0) [0|0] "" X
 SG_ CP_subUsageId m11: 48|16@1+ (1,0) [0|0] "" X
 SG_ CP_platformType m13: 8|8@1+ (1,0) [0|0] "" X
 SG_ CP_appCrc m13: 32|32@1+ (1,0) [0|0] "" X
 SG_ CP_appGitHash m17: 10|54@1+ (4,0) [0|0] "" X
 SG_ CP_bootGitHash m18: 10|54@1+ (4,0) [0|0] "" X
 SG_ CP_bootUdsProtoVersion m20: 8|8@1+ (1,0) [0|0] "" X
 SG_ CP_bootCrc m20: 32|32@1+ (1,0) [0|0] "" X

BO_ 1885 CP_sensorData: 8 VEH
 SG_ CP_sensorDataSelect M : 0|4@1+ (1,0) [0|12] ""  Receiver
 SG_ CP_UHF_chipState m6 : 4|3@1+ (1,0) [0|7] ""  Receiver
 SG_ CP_UHF_fifoData m6 : 32|8@1+ (1,0) [0|255] ""  Receiver
 SG_ CP_UHF_rssi m6 : 8|8@1+ (1,0) [0|255] ""  Receiver
 SG_ CP_UHF_rxNumBytes m6 : 24|8@1+ (1,0) [0|255] ""  Receiver
 SG_ CP_UHF_rxOverflow m6 : 16|1@1+ (1,0) [0|1] ""  Receiver
 SG_ CP_UHF_selfTestRssi m6 : 40|8@1+ (1,0) [0|255] ""  Receiver
 SG_ CP_backCover2Counts m5 : 32|16@1+ (0.0015259,0) [0|100] "%"  Receiver
 SG_ CP_backCoverCounts m5 : 16|16@1+ (0.0015259,0) [0|100] "%"  Receiver
 SG_ CP_boardTemperature m1 : 32|8@1+ (1.29411764706,-50) [-50|280.0000000003] "C"  Receiver
 SG_ CP_doorCountsDebounced m0 : 24|16@1+ (0.00152590219,0) [0|100.00000002165] "%"  Receiver
 SG_ CP_doorCountsFiltered m0 : 8|16@1+ (0.00152590219,0) [0|100.00000002165] "%"  Receiver
 SG_ CP_doorI m2 : 16|12@1+ (0.0025,0) [0|10.2375] "A"  Receiver
 SG_ CP_doorLastRequestMaxI m2 : 28|12@1+ (0.0025,0) [0|10.2375] "A"  Receiver
 SG_ CP_doorPot m2 : 4|12@1+ (0.025,0) [0|100] "%"  Receiver
 SG_ CP_faultLineV m5 : 4|12@1+ (0.00114,0) [0|4.65524] "V"  Receiver
 SG_ CP_inductiveSensor_raw m4 : 4|28@1+ (1,0) [0|268435455] ""  Receiver
 SG_ CP_inlet1HarnessIdState m12 : 4|2@1+ (1,0) [0|2] ""  Receiver
 SG_ CP_inlet1HarnessIdValue m12 : 8|3@1+ (1,0) [0|7] ""  Receiver
 SG_ CP_inlet1HarnessV m12 : 16|14@1+ (0.001,0) [0|13.3] "V"  Receiver
 SG_ CP_inlet2HarnessIdState m12 : 30|2@1+ (1,0) [0|2] ""  Receiver
 SG_ CP_inlet2HarnessIdValue m12 : 32|3@1+ (1,0) [0|7] ""  Receiver
 SG_ CP_inlet2HarnessV m12 : 40|14@1+ (0.001,0) [0|13.3] "V"  Receiver
 SG_ CP_latch2I m3 : 16|12@1+ (0.0025,0) [0|10.2375] "A"  Receiver
 SG_ CP_latchI m3 : 4|12@1+ (0.0025,0) [0|10.2375] "A"  Receiver
 SG_ CP_pilotHighValue m9 : 40|12@1- (0.01,0) [-20.48|20.47] "V"  Receiver
 SG_ CP_pilotHighValue_intervalMax10s m10 : 28|12@1- (0.01,0) [-20.48|20.47] "V"  Receiver
 SG_ CP_pilotHighValue_intervalMin10s m10 : 40|12@1- (0.01,0) [-20.48|20.47] "V"  Receiver
 SG_ CP_pilotLowValue m9 : 28|12@1- (0.01,0) [-20.48|20.47] "V"  Receiver
 SG_ CP_pilotLowValue_intervalMax10s m10 : 4|12@1- (0.01,0) [-20.48|20.47] "V"  Receiver
 SG_ CP_pilotLowValue_intervalMin10s m10 : 16|12@1- (0.01,0) [-20.48|20.47] "V"  Receiver
 SG_ CP_pilotPeriod m9 : 16|12@1+ (1,0) [0|4095] ""  Receiver
 SG_ CP_pilotPulseWidth m9 : 4|12@1+ (1,0) [0|4095] ""  Receiver
 SG_ CP_pinTemperature1 m1 : 8|8@1+ (0.8039215686,-55) [-55|149.99] "C"  Receiver
 SG_ CP_pinTemperature2 m1 : 16|8@1+ (0.8039215686,-55) [-55|149.99] "C"  Receiver
 SG_ CP_pinTemperature3 m1 : 24|8@1+ (0.8039215686,-55) [-55|149.99] "C"  Receiver
 SG_ CP_proxConn1Sense m8 : 56|1@1+ (1,0) [0|1] ""  Receiver
 SG_ CP_proxEn m8 : 57|1@1+ (1,0) [0|1] ""  Receiver
 SG_ CP_proximityV m8 : 8|16@1+ (0.0001,0) [0|6.5535] "V"  Receiver
 SG_ CP_proximityV_GBCC1 m11 : 8|14@1+ (0.001,0) [0|13.3] "V"  Receiver
 SG_ CP_proximityV_GBCC2 m11 : 24|14@1+ (0.001,0) [0|13.3] "V"  Receiver
 SG_ CP_proximityV_intervalMax10s m8 : 40|16@1+ (0.0001,0) [0|6.5535] "V"  Receiver
 SG_ CP_proximityV_intervalMin10s m8 : 24|16@1+ (0.0001,0) [0|6.5535] "V"  Receiver
 SG_ CP_refVoltage m7 : 8|8@1+ (0.0070588235,0) [0|1.7999999925] "V"  Receiver

BO_ 605 DAS_road: 6 XXX
 SG_ DAS_stopLineDist : 16|8@1+ (0.5,0) [0|127.5] "m" XXX
 SG_ DAS_trafficLightColor : 26|3@0+ (1,0) [0|7] "" XXX

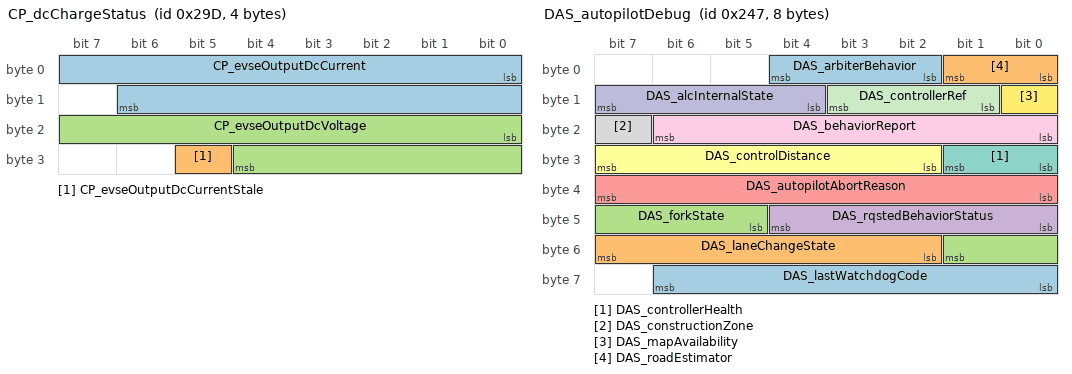
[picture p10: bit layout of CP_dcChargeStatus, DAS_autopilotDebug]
BO_ 669 CP_dcChargeStatus: 4 VEH
 SG_ CP_evseOutputDcCurrent : 0|15@1- (0.0732467,0) [-1200|1200] "A" X
 SG_ CP_evseOutputDcCurrentStale : 29|1@1+ (1,0) [0|1] "" X
 SG_ CP_evseOutputDcVoltage : 16|13@1+ (0.0732422,0) [0|599.927] "V" X

BO_ 583 DAS_autopilotDebug: 8 Vector__XXX
 SG_ DAS_lastWatchdogCode : 56|7@1+ (1,0) [0|0] "" Vector__XXX
 SG_ DAS_laneChangeState : 50|6@1+ (1,0) [0|0] "" Vector__XXX
 SG_ DAS_forkState : 45|5@1+ (1,0) [0|0] "" Vector__XXX
 SG_ DAS_rqstedBehaviorStatus : 40|5@1+ (1,0) [0|0] "" Vector__XXX
 SG_ DAS_autopilotAbortReason : 32|8@1+ (1,0) [0|0] "" Vector__XXX
 SG_ DAS_controlDistance : 26|6@1+ (2,0) [0|0] "" Vector__XXX
 SG_ DAS_controllerHealth : 24|2@1+ (1,0) [0|0] "" Vector__XXX
 SG_ DAS_constructionZone : 23|1@1+ (1,0) [0|0] "" Vector__XXX
 SG_ DAS_behaviorReport : 16|7@1+ (1,0) [0|0] "" Vector__XXX
 SG_ DAS_alcInternalState : 12|4@1+ (1,0) [0|0] "" Vector__XXX
 SG_ DAS_controllerRef : 9|3@1+ (1,0) [0|0] "" Vector__XXX
 SG_ DAS_mapAvailability : 8|1@1+ (1,0) [0|0] "" Vector__XXX
 SG_ DAS_arbiterBehavior : 2|3@1+ (1,0) [0|0] "" Vector__XXX
 SG_ DAS_roadEstimator : 0|2@1+ (1,0) [0|0] "" Vector__XXX

BO_ 1001 DAS_bodyControls: 8 Vector__XXX
 SG_ DAS_bodyControlsChecksum : 56|8@1+ (1,0) [0|0] "" Vector__XXX
 SG_ DAS_bodyControlsCounter : 52|4@1+ (1,0) [0|0] "" Vector__XXX
 SG_ DAS_restrictDoorReleaseRight : 51|1@1+ (1,0) [0|0] "" Vector__XXX
 SG_ DAS_restrictDoorReleaseLeft : 50|1@1+ (1,0) [0|0] "" Vector__XXX
 SG_ DAS_adaptiveHighBeamIsFaulted : 49|1@1+ (1,0) [0|0] "" Vector__XXX
 SG_ DAS_rPillarCamHeaterDutyCycle : 45|4@1+ (0.06666666666666667,0) [0|0] "" Vector__XXX
 SG_ DAS_enableIcrDataCollection : 44|1@1+ (1,0) [0|0] "" Vector__XXX
 SG_ DAS_drivePowerStateRequest : 43|1@1+ (1,0) [0|0] "" Vector__XXX
 SG_ DAS_driverDomeLightRequest : 39|1@1+ (1,0) [0|0] "" Vector__XXX
 SG_ DAS_forwardRadarPowerRequest : 38|1@1+ (1,0) [0|0] "" Vector__XXX
 SG_ DAS_turnIndicatorRequestReason : 33|5@1+ (1,0) [0|0] "" Vector__XXX
 SG_ DAS_autoWiperState : 30|3@1+ (1,0) [0|0] "" Vector__XXX
 SG_ DAS_overrideWiperSetting : 29|1@1+ (1,0) [0|0] "" Vector__XXX
 SG_ DAS_ulcConfirmationRequestActive : 28|1@1+ (1,0) [0|0] "" Vector__XXX
 SG_ DAS_wiperWashRequest : 27|1@1+ (1,0) [0|0] "" Vector__XXX
 SG_ DAS_mirrorFoldRequest : 25|2@1+ (1,0) [0|0] "" Vector__XXX
 SG_ DAS_ahlbOverride : 24|1@1+ (1,0) [0|0] "" Vector__XXX
 SG_ DAS_radarHeaterRequest : 23|1@1+ (1,0) [0|0] "" Vector__XXX
 SG_ DAS_dynamicBrakeLightRequest : 22|1@1+ (1,0) [0|0] "" Vector__XXX
 SG_ DAS_forwardCamHeaterDutyCycle : 18|4@1+ (0.06666666666666667,0) [0|0] "" Vector__XXX
 SG_ DAS_highLowBeamOffReason : 15|3@1+ (1,0) [0|0] "" Vector__XXX
 SG_ DAS_heaterRequest : 13|2@1+ (1,0) [0|0] "" Vector__XXX
 SG_ DAS_highLowBeamDecision : 11|2@1+ (1,0) [0|0] "" Vector__XXX
 SG_ DAS_turnIndicatorRequest : 8|3@1+ (1,0) [0|0] "" Vector__XXX
 SG_ DAS_wiperSpeed : 4|4@1+ (1,0) [0|0] "" Vector__XXX
 SG_ DAS_hazardLightRequest : 2|2@1+ (1,0) [0|0] "" Vector__XXX
 SG_ DAS_headlightRequest : 0|2@1+ (1,0) [0|0] "" Vector__XXX

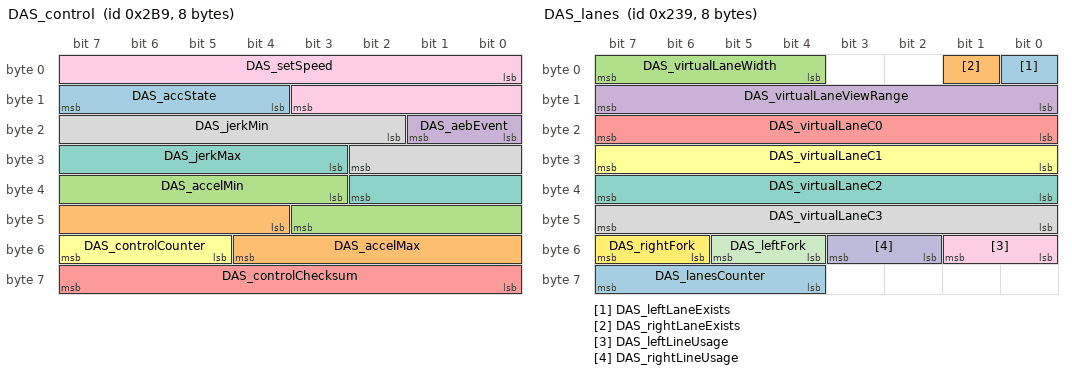
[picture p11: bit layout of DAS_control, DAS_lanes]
BO_ 697 DAS_control: 8 CH
 SG_ DAS_accState: 12|4@1+ (1,0) [0|0] "" X
 SG_ DAS_accelMax: 44|9@1+ (0.04,-15) [0|0] "m/s^2" X
 SG_ DAS_accelMin: 35|9@1+ (0.04,-15) [0|0] "m/s^2" X
 SG_ DAS_aebEvent: 16|2@1+ (1,0) [0|0] "" X
 SG_ DAS_controlChecksum: 56|8@1+ (1,0) [0|0] "" X
 SG_ DAS_controlCounter: 53|3@1+ (1,0) [0|0] "" X
 SG_ DAS_jerkMax: 27|8@1+ (0.034,0) [0|0] "m/s^3" X
 SG_ DAS_jerkMin: 18|9@1+ (0.018,-9.1) [0|0] "m/s^3" X
 SG_ DAS_setSpeed: 0|12@1+ (0.1,0) [0|0] "kph" X

BO_ 1337 DAS_info: 8 CH
 SG_ DAS_infoIndex M: 0|8@1+ (1,0) [0|0] "" X
 SG_ DAS_infoBuildType m10: 8|8@1+ (1,0) [0|0] "" X
 SG_ DAS_infoBuildConfigID m10: 16|16@1+ (1,0) [0|0] "" X
 SG_ DAS_infoHardwareID m10: 32|16@1+ (1,0) [0|0] "" X
 SG_ DAS_infoComponentID m10: 48|16@1+ (1,0) [0|0] "" X
 SG_ DAS_infoPcbaID m11: 16|8@1+ (1,0) [0|0] "" X
 SG_ DAS_infoAssemblyID m11: 24|8@1+ (1,0) [0|0] "" X
 SG_ DAS_infoUsageID m11: 32|16@1+ (1,0) [0|0] "" X
 SG_ DAS_infoSubUsageID m11: 48|16@1+ (1,0) [0|0] "" X
 SG_ DAS_infoApplicationCRC m13: 32|32@1+ (1,0) [0|0] "" X
 SG_ DAS_infoBootloaderSvnRevision m14: 8|24@1+ (1,0) [0|0] "" X
 SG_ DAS_infoEyeQBootCRC m16: 16|32@1+ (1,0) [0|0] "" X
 SG_ DAS_infoAppGitHashBytes m17: 10|54@1+ (4,0) [0|0] "" X
 SG_ DAS_infoBootGitHashBytes m18: 10|54@1+ (4,0) [0|0] "" X
 SG_ DAS_infoPlatformType m19: 8|8@1+ (1,0) [0|0] "" X
 SG_ DAS_infoMajorVersion m19: 16|8@1+ (1,0) [0|0] "" X
 SG_ DAS_infoBranchOrigin m19: 24|8@1+ (1,0) [0|0] "" X
 SG_ DAS_infoMaturity m19: 32|8@1+ (1,0) [0|0] "" X
 SG_ DAS_infoHardwareRevision m19: 40|8@1+ (1,0) [0|0] "" X
 SG_ DAS_infoBootUdsProtoVersion m20: 8|8@1+ (1,0) [0|0] "" X
 SG_ DAS_infoBootloaderCRC m20: 32|32@1+ (1,0) [0|0] "" X
 SG_ DAS_infoEyeQAppCRC m23: 16|32@1+ (1,0) [0|0] "" X
 SG_ DAS_infoEyeQFfsCRC m24: 16|32@1+ (1,0) [0|0] "" X

BO_ 569 DAS_lanes: 8 CH
 SG_ DAS_leftLaneExists: 0|1@1+ (1,0) [0|0] "" X
 SG_ DAS_rightLaneExists: 1|1@1+ (1,0) [0|0] "" X
 SG_ DAS_virtualLaneWidth: 4|4@1+ (0.3125,2) [0|0] "m" X
 SG_ DAS_virtualLaneViewRange: 8|8@1+ (1,0) [0|0] "m" X
 SG_ DAS_virtualLaneC0: 16|8@1+ (3.5,-350) [0|0] "cm" X
 SG_ DAS_virtualLaneC1: 24|8@1+ (0.092,-11.46) [0|0] "deg" X
 SG_ DAS_virtualLaneC2: 32|8@1+ (2e-05,-0.0025) [0|0] "m-1" X
 SG_ DAS_virtualLaneC3: 40|8@1+ (2.4e-07,-3e-05) [0|0] "m-2" X
 SG_ DAS_leftLineUsage: 48|2@1+ (1,0) [0|0] "" X
 SG_ DAS_rightLineUsage: 50|2@1+ (1,0) [0|0] "" X
 SG_ DAS_leftFork: 52|2@1+ (1,0) [0|0] "" X
 SG_ DAS_rightFork: 54|2@1+ (1,0) [0|0] "" X
 SG_ DAS_lanesCounter: 60|4@1+ (1,0) [0|0] "" X

BO_ 777 DAS_object: 8 CH
 SG_ DAS_objectId M: 0|3@1+ (1,0) [0|0] "" X
 SG_ DAS_leadVehType m0: 3|3@1+ (1,0) [0|0] "" X
 SG_ DAS_leadVehRelevantForControl m0: 7|1@1+ (1,0) [0|0] "" X
 SG_ DAS_leadVehDx m0: 8|8@1+ (0.5,0) [0|0] "m" X
 SG_ DAS_leadVehVxRel m0: 16|4@1+ (4,-30) [0|0] "m/s" X
 SG_ DAS_leadVehDy m0: 20|7@1+ (0.35,-22.05) [0|0] "m" X
 SG_ DAS_leadVehId m0: 27|7@1+ (1,0) [0|0] "" X
 SG_ DAS_leadVeh2Type m0: 34|3@1+ (1,0) [0|0] "" X
 SG_ DAS_leadVeh2RelevantForControl m0: 38|1@1+ (1,0) [0|0] "" X
 SG_ DAS_leadVeh2Dx m0: 39|8@1+ (0.5,0) [0|0] "m" X
 SG_ DAS_leadVeh2VxRel m0: 47|4@1+ (4,-30) [0|0] "m/s" X
 SG_ DAS_leadVeh2Dy m0: 51|7@1+ (0.35,-22.05) [0|0] "m" X
 SG_ DAS_leadVeh2Id m0: 58|6@1+ (1,0) [0|0] "" X
 SG_ DAS_leftVehType m1: 3|3@1+ (1,0) [0|0] "" X
 SG_ DAS_leftVehRelevantForControl m1: 7|1@1+ (1,0) [0|0] "" X
 SG_ DAS_leftVehDx m1: 8|8@1+ (0.5,0) [0|0] "m" X
 SG_ DAS_leftVehVxRel m1: 16|4@1+ (4,-30) [0|0] "m/s" X
 SG_ DAS_leftVehDy m1: 20|7@1+ (0.35,-22.05) [0|0] "m" X
 SG_ DAS_leftVehId m1: 27|7@1+ (1,0) [0|0] "" X
 SG_ DAS_leftVeh2Type m1: 34|3@1+ (1,0) [0|0] "" X
 SG_ DAS_leftVeh2RelevantForControl m1: 38|1@1+ (1,0) [0|0] "" X
 SG_ DAS_leftVeh2Dx m1: 39|8@1+ (0.5,0) [0|0] "m" X
 SG_ DAS_leftVeh2VxRel m1: 47|4@1+ (4,-30) [0|0] "m/s" X
 SG_ DAS_leftVeh2Dy m1: 51|7@1+ (0.35,-22.05) [0|0] "m" X
 SG_ DAS_leftVeh2Id m1: 58|6@1+ (1,0) [0|0] "" X
 SG_ DAS_rightVehType m2: 3|3@1+ (1,0) [0|0] "" X
 SG_ DAS_rightVehRelevantForControl m2: 7|1@1+ (1,0) [0|0] "" X
 SG_ DAS_rightVehDx m2: 8|8@1+ (0.5,0) [0|0] "m" X
 SG_ DAS_rightVehVxRel m2: 16|4@1+ (4,-30) [0|0] "m/s" X
 SG_ DAS_rightVehDy m2: 20|7@1+ (0.35,-22.05) [0|0] "m" X
 SG_ DAS_rightVehId m2: 27|7@1+ (1,0) [0|0] "" X
 SG_ DAS_rightVeh2Type m2: 34|3@1+ (1,0) [0|0] "" X
 SG_ DAS_rightVeh2RelevantForControl m2: 38|1@1+ (1,0) [0|0] "" X
 SG_ DAS_rightVeh2Dx m2: 39|8@1+ (0.5,0) [0|0] "m" X
 SG_ DAS_rightVeh2VxRel m2: 47|4@1+ (4,-30) [0|0] "m/s" X
 SG_ DAS_rightVeh2Dy m2: 51|7@1+ (0.35,-22.05) [0|0] "m" X
 SG_ DAS_rightVeh2Id m2: 58|6@1+ (1,0) [0|0] "" X
 SG_ DAS_cutinVehType m3: 3|3@1+ (1,0) [0|0] "" X
 SG_ DAS_cutinVehRelevantForControl m3: 7|1@1+ (1,0) [0|0] "" X
 SG_ DAS_cutinVehDx m3: 8|8@1+ (0.5,0) [0|0] "m" X
 SG_ DAS_cutinVehVxRel m3: 16|4@1+ (4,-30) [0|0] "m/s" X
 SG_ DAS_cutinVehDy m3: 20|7@1+ (0.35,-22.05) [0|0] "m" X
 SG_ DAS_cutinVehId m3: 27|7@1+ (1,0) [0|0] "" X
 SG_ DAS_roadSignColor m4: 3|3@1+ (1,0) [0|0] "" X
 SG_ DAS_roadSignId m4: 6|8@1+ (1,0) [0|0] "" X
 SG_ DAS_roadSignStopLineDist m4: 14|10@1+ (0.2,-20) [0|0] "m" X
 SG_ DAS_roadSignControlActive m4: 24|1@1+ (1,0) [0|0] "" X
 SG_ DAS_roadSignSource m4: 25|2@1+ (1,0) [0|0] "" X
 SG_ DAS_roadSignArrow m4: 27|3@1+ (1,0) [0|0] "" X
 SG_ DAS_roadSignOrientation m4: 30|2@1+ (1,0) [0|0] "" X
 SG_ DAS_leadVehHeading m5: 8|8@1+ (0.0245437,-3.14159) [0|0] "rad" X
 SG_ DAS_leadVeh2Heading m5: 16|8@1+ (0.0245437,-3.14159) [0|0] "rad" X
 SG_ DAS_leftVehHeading m5: 24|8@1+ (0.0245437,-3.14159) [0|0] "rad" X
 SG_ DAS_leftVeh2Heading m5: 32|8@1+ (0.0245437,-3.14159) [0|0] "rad" X
 SG_ DAS_rightVehHeading m5: 40|8@1+ (0.0245437,-3.14159) [0|0] "rad" X
 SG_ DAS_rightVeh2Heading m5: 48|8@1+ (0.0245437,-3.14159) [0|0] "rad" X
 SG_ DAS_cutinVehHeading m5: 56|8@1+ (0.0245437,-3.14159) [0|0] "rad" X

BO_ 921 DAS_status: 8 CH
 SG_ DAS_autoLaneChangeState: 46|5@1+ (1,0) [0|0] "" X
 SG_ DAS_autoParked: 25|1@1+ (1,0) [0|0] "" X
 SG_ DAS_autoparkReady: 24|1@1+ (1,0) [0|0] "" X
 SG_ DAS_autoparkWaitingForBrake: 26|1@1+ (1,0) [0|0] "" X
 SG_ DAS_autopilotHandsOnState: 42|4@1+ (1,0) [0|0] "" X
 SG_ DAS_autopilotState: 0|4@1+ (1,0) [0|0] "" X
 SG_ DAS_blindSpotRearLeft: 4|2@1+ (1,0) [0|0] "" X
 SG_ DAS_blindSpotRearRight: 6|2@1+ (1,0) [0|0] "" X
 SG_ DAS_csaState: 35|2@1+ (1,0) [0|0] "" X
 SG_ DAS_fleetSpeedState: 40|2@1+ (1,0) [0|0] "" X
 SG_ DAS_forwardCollisionWarning: 22|2@1+ (1,0) [0|0] "" X
 SG_ DAS_fusedSpeedLimit: 8|5@1+ (5,0) [0|0] "kph/mph" X
 SG_ DAS_heaterState: 21|1@1+ (1,0) [0|0] "" X
 SG_ DAS_laneDepartureWarning: 37|3@1+ (1,0) [0|0] "" X
 SG_ DAS_sideCollisionAvoid: 30|2@1+ (1,0) [0|0] "" X
 SG_ DAS_sideCollisionInhibit: 34|1@1+ (1,0) [0|0] "" X
 SG_ DAS_sideCollisionWarning: 32|2@1+ (1,0) [0|0] "" X
 SG_ DAS_statusChecksum: 56|8@1+ (1,0) [0|0] "" X
 SG_ DAS_statusCounter: 52|4@1+ (1,0) [0|0] "" X
 SG_ DAS_summonAvailable: 51|1@1+ (1,0) [0|0] "" X
 SG_ DAS_summonClearedGate: 15|1@1+ (1,0) [0|0] "" X
 SG_ DAS_summonFwdLeashReached: 28|1@1+ (1,0) [0|0] "" X
 SG_ DAS_summonObstacle: 14|1@1+ (1,0) [0|0] "" X
 SG_ DAS_summonRvsLeashReached: 29|1@1+ (1,0) [0|0] "" X
 SG_ DAS_suppressSpeedWarning: 13|1@1+ (1,0) [0|0] "" X
 SG_ DAS_visionOnlySpeedLimit: 16|5@1+ (5,0) [0|0] "kph/mph" X

BO_ 905 DAS_status2: 8 CH
 SG_ DAS_ACC_report: 26|5@1+ (1,0) [0|0] "" X
 SG_ DAS_accSpeedLimit: 0|10@1+ (0.2,0) [0|0] "mph" X
 SG_ DAS_activationFailureStatus: 14|2@1+ (1,0) [0|0] "" X
 SG_ DAS_driverInteractionLevel: 38|2@1+ (1,0) [0|0] "" X
 SG_ DAS_longCollisionWarning: 48|4@1+ (1,0) [0|0] "" X
 SG_ DAS_lssState: 31|3@1+ (1,0) [0|0] "" X
 SG_ DAS_pmmCameraFaultReason: 24|2@1+ (1,0) [0|0] "" X
 SG_ DAS_pmmLoggingRequest: 13|1@1+ (1,0) [0|0] "" X
 SG_ DAS_pmmObstacleSeverity: 10|3@1+ (1,0) [0|0] "" X
 SG_ DAS_pmmRadarFaultReason: 19|2@1+ (1,0) [0|0] "" X
 SG_ DAS_pmmSysFaultReason: 21|3@1+ (1,0) [0|0] "" X
 SG_ DAS_pmmUltrasonicsFaultReason: 16|3@1+ (1,0) [0|0] "" X
 SG_ DAS_ppOffsetDesiredRamp: 40|8@1+ (0.01,-1.28) [0|0] "m" X
 SG_ DAS_radarTelemetry: 34|2@1+ (1,0) [0|0] "" X
 SG_ DAS_robState: 36|2@1+ (1,0) [0|0] "" X
 SG_ DAS_status2Checksum: 56|8@1+ (1,0) [0|0] "" X
 SG_ DAS_status2Counter: 52|4@1+ (1,0) [0|0] "" X

BO_ 937 DAS_telemetry: 8 VEH
 SG_ DAS_telemetryMultiplexer M: 0|8@1+ (1,0) [0|0] "" X
 SG_ DAS_telLeftLaneType m0: 8|3@1+ (1,0) [0|0] "" X
 SG_ DAS_telRightLaneType m0: 11|3@1+ (1,0) [0|0] "" X
 SG_ DAS_telLeftMarkerQuality m0: 14|2@1+ (1,0) [0|0] "" X
 SG_ DAS_telRightMarkerQuality m0: 16|2@1+ (1,0) [0|0] "" X
 SG_ DAS_telLeftMarkerColor m0: 18|2@1+ (1,0) [0|0] "" X
 SG_ DAS_telRightMarkerColor m0: 20|2@1+ (1,0) [0|0] "" X
 SG_ DAS_telLeftLaneCrossing m0: 22|1@1+ (1,0) [0|0] "" X
 SG_ DAS_telRightLaneCrossing m0: 23|1@1+ (1,0) [0|0] "" X
 SG_ DAS_MCPObserved m1: 8|1@1+ (1,0) [0|0] "" X
 SG_ DAS_accReengaged m1: 9|1@1+ (1,0) [0|0] "" X
 SG_ DAS_pedestrianInFOVBeforeIntr m1: 10|1@1+ (1,0) [0|0] "" X
 SG_ DAS_pedestrianInFOVAfterIntr m1: 11|1@1+ (1,0) [0|0] "" X
 SG_ DAS_camFreeSpaceBeforeIntr m1: 12|1@1+ (1,0) [0|0] "" X
 SG_ DAS_camFreeSpaceAfterIntr m1: 13|1@1+ (1,0) [0|0] "" X
 SG_ DAS_timeOfIntervention m1: 14|6@1+ (0.25,0) [0|0] "s" X
 SG_ DAS_timeOfFirstPedestrian m1: 20|6@1+ (0.25,0) [0|0] "s" X
 SG_ DAS_timeOfACCReengaging m1: 26|6@1+ (0.25,0) [0|0] "s" X
 SG_ DAS_durationOfPrevACCStandstill m1: 32|6@1+ (0.5,0) [0|0] "s" X
 SG_ DAS_maxAbsSteeringWheelAngle m1: 38|7@1+ (2,0) [0|0] "degrees" X
 SG_ DAS_targetRelvelAtIntervention m1: 45|6@1+ (0.25,-2) [0|0] "m/s" X
 SG_ DAS_targetDistAtIntervention m1: 51|6@1+ (0.5,0) [0|0] "m" X
 SG_ DAS_egoSpeedAtIntervention m1: 57|6@1+ (0.5,0) [0|0] "m/s" X
 SG_ DAS_stopSignLongitudinalDist m2: 8|10@1+ (0.1,0) [0|0] "m" X
 SG_ DAS_stopSignLateralDist m2: 18|8@1+ (0.25,-32) [0|0] "m" X
 SG_ DAS_stopSignHeight m2: 26|6@1+ (0.1,0) [0|0] "m" X
 SG_ DAS_stopSignStopLineDistance m2: 32|10@1+ (0.1,-20) [0|0] "m" X
 SG_ DAS_stopSignCIPVDistance m2: 42|6@1+ (0.5,0) [0|0] "m" X
 SG_ DAS_stopSignHostAccel m2: 48|10@1+ (0.01,-5) [0|0] "m/s^2" X
 SG_ DAS_stopSignCrossingWarning m2: 58|1@1+ (1,0) [0|0] "" X
 SG_ DAS_stopSignIndex m2: 59|4@1+ (1,0) [0|0] "" X
 SG_ DAS_csaOverride m7: 10|1@1+ (1,0) [0|0] "" X
 SG_ DAS_csaIntState m7: 11|3@1+ (1,0) [0|0] "" X
 SG_ DAS_csaEnableSpeed m7: 14|12@1+ (0.05,-25) [0|0] "MPH" X
 SG_ DAS_csaDisableSpeed m7: 26|12@1+ (0.05,-25) [0|0] "MPH" X
 SG_ DAS_csaFiltCurv m7: 40|16@1- (1e-06,0) [0|0] "1/m" X
 SG_ DAS_csaMeasLatAccel m7: 56|8@1+ (0.08,-10.24) [0|0] "m/s^2" X
 SG_ DAS_soCamCipvStatus m8: 8|2@1+ (1,0) [0|0] "" X
 SG_ DAS_soRad5Status m8: 10|2@1+ (1,0) [0|0] "" X
 SG_ DAS_soRad1Status m8: 12|2@1+ (1,0) [0|0] "" X
 SG_ DAS_soCamCipvDx m8: 14|6@1+ (2,0) [0|0] "m" X
 SG_ DAS_soRad1Dx m8: 20|6@1+ (2,0) [0|0] "m" X
 SG_ DAS_soRad5Dx m8: 26|6@1+ (2,0) [0|0] "m" X
 SG_ DAS_soCamCipvDy m8: 32|5@1+ (0.4,-6.4) [0|0] "m" X
 SG_ DAS_soRad5Dy m8: 37|5@1+ (0.4,-6.4) [0|0] "m" X
 SG_ DAS_soCamCipvVx m8: 42|5@1+ (1,0) [0|0] "m/s" X
 SG_ DAS_soRad5ObstProb m8: 47|4@1+ (0.0625,0) [0|0] "probability" X
 SG_ DAS_soRad5Dz m8: 51|6@1+ (0.25,-5) [0|0] "m" X
 SG_ DAS_soRad5powerdB m8: 57|7@1+ (2,0) [0|0] "dB" X
 SG_ DAS_assPrevSetSpeed m9: 8|8@1+ (0.25,0) [0|0] "m/s" X
 SG_ DAS_assNewSetSpeed m9: 16|8@1+ (0.25,0) [0|0] "m/s" X
 SG_ DAS_assFusedSpeedLimit m9: 24|6@1+ (1,0) [0|0] "m/s" X
 SG_ DAS_assAutosteerActive m9: 30|1@1+ (1,0) [0|0] "" X
 SG_ DAS_assSmartSpeedActive m9: 31|1@1+ (1,0) [0|0] "" X

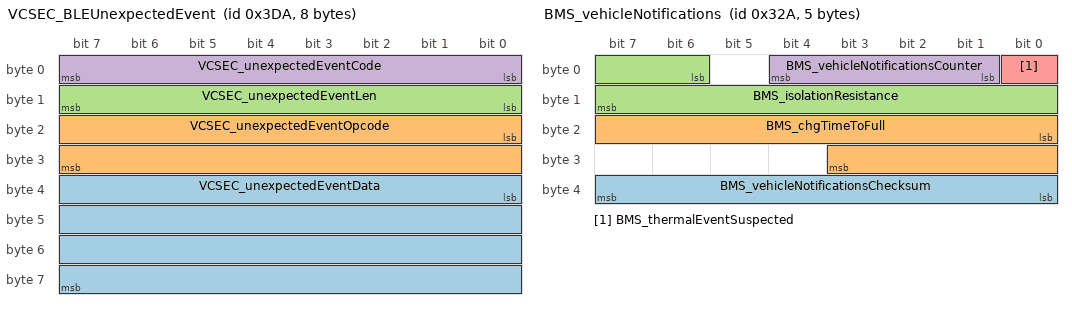
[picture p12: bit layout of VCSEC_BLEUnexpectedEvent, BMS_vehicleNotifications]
BO_ 986 VCSEC_BLEUnexpectedEvent: 8 Vector__XXX
 SG_ VCSEC_unexpectedEventData : 32|32@1+ (1,0) [0|0] "" Vector__XXX
 SG_ VCSEC_unexpectedEventOpcode : 16|16@1+ (1,0) [0|0] "" Vector__XXX
 SG_ VCSEC_unexpectedEventLen : 8|8@1+ (1,0) [0|0] "" Vector__XXX
 SG_ VCSEC_unexpectedEventCode : 0|8@1+ (1,0) [0|0] "" Vector__XXX

BO_ 945 DAS_telemetryFurniture: 8 VEH
 SG_ DAS_TF_multiplexer M: 0|5@1+ (1,0) [0|0] "" X
 SG_ DAS_TF_furnitureIndex0 m0: 5|8@1+ (1,0) [0|0] "" X
 SG_ DAS_TF_distTraveled m0: 13|11@1+ (0.1,0) [0|0] "m" X
 SG_ DAS_TF_llType m0: 24|3@1+ (1,0) [0|0] "" X
 SG_ DAS_TF_rlType m0: 27|3@1+ (1,0) [0|0] "" X
 SG_ DAS_TF_cipvDist m0: 30|9@1+ (0.1,0) [0|0] "m" X
 SG_ DAS_TF_timeOfDay m0: 39|3@1+ (1,0) [0|0] "" X
 SG_ DAS_TF_furnitureType m0: 42|3@1+ (1,0) [0|0] "" X
 SG_ DAS_TF_furnitureIndex1 m1: 5|8@1+ (1,0) [0|0] "" X
 SG_ DAS_TF_longitudinalDist m1: 13|12@1+ (0.1,0) [0|0] "m" X
 SG_ DAS_TF_lateralDist m1: 25|12@1+ (0.1,-204.8) [0|0] "m" X
 SG_ DAS_TF_height m1: 37|12@1+ (0.05,0) [0|0] "m" X
 SG_ DAS_TF_color m1: 49|3@1+ (1,0) [0|0] "" X
 SG_ DAS_TF_shape m1: 52|3@1+ (1,0) [0|0] "" X
 SG_ DAS_TF_orientation m1: 55|2@1+ (1,0) [0|0] "" X
 SG_ DAS_TF_transmissionStatus m1: 57|2@1+ (1,0) [0|0] "" X
 SG_ DAS_TF_isMain m1: 59|1@1+ (1,0) [0|0] "" X
 SG_ DAS_TF_isTeslaMain m1: 60|1@1+ (1,0) [0|0] "" X
 SG_ DAS_TF_furnitureIndex2 m2: 5|8@1+ (1,0) [0|0] "" X
 SG_ DAS_TF_juncStatus m2: 13|4@1+ (1,0) [0|0] "" X
 SG_ DAS_TF_juncDist m2: 17|11@1+ (0.2,-20) [0|0] "m" X
 SG_ DAS_TF_stopLineDist m2: 28|11@1+ (0.1,-10) [0|0] "m" X
 SG_ DAS_TF_ttc m2: 39|7@1+ (0.1,0) [0|0] "s" X

BO_ 890 VCSEC_ConnectionMonitor: 8 Vector__XXX
 SG_ VCSEC_CMTimeSyncFailL0 m2 : 56|8@1+ (1,0) [0|0] "" Vector__XXX
 SG_ VCSEC_CMTimeSyncFailR0 m1 : 56|8@1+ (1,0) [0|0] "" Vector__XXX
 SG_ VCSEC_CMTimeSyncFailRi0 m0 : 56|8@1+ (1,0) [0|0] "" Vector__XXX
 SG_ VCSEC_CMEventOutsideWinL0 m2 : 48|8@1+ (1,0) [0|0] "" Vector__XXX
 SG_ VCSEC_CMEventOutsideWinR0 m1 : 48|8@1+ (1,0) [0|0] "" Vector__XXX
 SG_ VCSEC_CMEventOutsideWinRi0 m0 : 48|8@1+ (1,0) [0|0] "" Vector__XXX
 SG_ VCSEC_CMEventIncorrectChannelL0 m2 : 40|8@1+ (1,0) [0|0] "" Vector__XXX
 SG_ VCSEC_CMEventIncorrectChannelR0 m1 : 40|8@1+ (1,0) [0|0] "" Vector__XXX
 SG_ VCSEC_CMEventIncorrectChannelRi0 m0 : 40|8@1+ (1,0) [0|0] "" Vector__XXX
 SG_ VCSEC_CMEventNonMatchingPktCountL0 m2 : 32|8@1+ (1,0) [0|0] "" Vector__XXX
 SG_ VCSEC_CMEventNonMatchingPktCountR0 m1 : 32|8@1+ (1,0) [0|0] "" Vector__XXX
 SG_ VCSEC_CMEventNonMatchingPktCountRi0 m0 : 32|8@1+ (1,0) [0|0] "" Vector__XXX
 SG_ VCSEC_CMEventSNNESNDeassertL0 m2 : 24|8@1+ (1,0) [0|0] "" Vector__XXX
 SG_ VCSEC_CMEventSNNESNDeassertR0 m1 : 24|8@1+ (1,0) [0|0] "" Vector__XXX
 SG_ VCSEC_CMEventSNNESNDeassertRi0 m0 : 24|8@1+ (1,0) [0|0] "" Vector__XXX
 SG_ VCSEC_BLE2ConnInterval m3 : 22|10@1+ (1,0) [0|0] "" Vector__XXX
 SG_ VCSEC_CMEventNonEmptyPacketsL0 m2 : 16|8@1+ (1,0) [0|0] "" Vector__XXX
 SG_ VCSEC_CMEventNonEmptyPacketsR0 m1 : 16|8@1+ (1,0) [0|0] "" Vector__XXX
 SG_ VCSEC_CMEventNonEmptyPacketsRi0 m0 : 16|8@1+ (1,0) [0|0] "" Vector__XXX
 SG_ VCSEC_BLE1ConnInterval m3 : 12|10@1+ (1,0) [0|0] "" Vector__XXX
 SG_ VCSEC_BLERSSITrackingPercentL2 m2 : 12|4@1+ (8,0) [0|0] "" Vector__XXX
 SG_ VCSEC_BLERSSITrackingPercentR2 m0 : 12|4@1+ (8,0) [0|0] "" Vector__XXX
 SG_ VCSEC_BLERSSITrackingPercentRe2 m1 : 12|4@1+ (8,0) [0|0] "" Vector__XXX
 SG_ VCSEC_BLERSSITrackingPercentL1 m2 : 8|4@1+ (8,0) [0|0] "" Vector__XXX
 SG_ VCSEC_BLERSSITrackingPercentR1 m0 : 8|4@1+ (8,0) [0|0] "" Vector__XXX
 SG_ VCSEC_BLERSSITrackingPercentRe1 m1 : 8|4@1+ (8,0) [0|0] "" Vector__XXX
 SG_ VCSEC_BLERSSITrackingPercentL0 m2 : 4|4@1+ (8,0) [0|0] "" Vector__XXX
 SG_ VCSEC_BLERSSITrackingPercentR0 m0 : 4|4@1+ (8,0) [0|0] "" Vector__XXX
 SG_ VCSEC_BLERSSITrackingPercentRe0 m1 : 4|4@1+ (8,0) [0|0] "" Vector__XXX
 SG_ VCSEC_BLE0ConnInterval m3 : 2|10@1+ (1,0) [0|0] "" Vector__XXX
 SG_ VCSEC_BLEConnectionMonitorIndex M : 0|2@1+ (1,0) [0|0] "" Vector__XXX

BO_ 1548 DAS_telemetryRadar: 8 VEH
 SG_ DAS_TR_Counter: 54|2@1+ (1,0) [0|0] "" X
 SG_ DAS_TR_ObjIndex M: 0|5@1+ (1,0) [0|0] "" X
 SG_ DAS_TR_Obj00_Class m0: 5|3@1+ (1,0) [0|0] "" X
 SG_ DAS_TR_Obj00_Dx m0: 8|10@1+ (0.15625,0) [0|0] "m" X
 SG_ DAS_TR_Obj00_Dy m0: 18|6@1+ (0.5,-15.5) [0|0] "m" X
 SG_ DAS_TR_Obj00_Vx m0: 24|8@1+ (0.5,-63.5) [0|0] "m/s" X
 SG_ DAS_TR_Obj00_RCS m0: 32|8@1+ (0.25,-14) [0|0] "dB" X
 SG_ DAS_TR_Obj00_Length m0: 40|6@1+ (0.125,0) [0|0] "m" X
 SG_ DAS_TR_Obj00_MovingState m0: 46|2@1+ (1,0) [0|0] "" X
 SG_ DAS_TR_Obj00_Dz m0: 48|6@1+ (0.25,-5) [0|0] "m" X
 SG_ DAS_TR_Obj00_Exist m0: 56|5@1+ (3.125,0) [0|0] "%" X
 SG_ DAS_TR_Obj01_Class m1: 5|3@1+ (1,0) [0|0] "" X
 SG_ DAS_TR_Obj01_Dx m1: 8|10@1+ (0.15625,0) [0|0] "m" X
 SG_ DAS_TR_Obj01_Dy m1: 18|6@1+ (0.5,-15.5) [0|0] "m" X
 SG_ DAS_TR_Obj01_Vx m1: 24|8@1+ (0.5,-63.5) [0|0] "m/s" X
 SG_ DAS_TR_Obj01_RCS m1: 32|8@1+ (0.25,-14) [0|0] "dB" X
 SG_ DAS_TR_Obj01_Length m1: 40|6@1+ (0.125,0) [0|0] "m" X
 SG_ DAS_TR_Obj01_MovingState m1: 46|2@1+ (1,0) [0|0] "" X
 SG_ DAS_TR_Obj01_Dz m1: 48|6@1+ (0.25,-5) [0|0] "m" X
 SG_ DAS_TR_Obj01_Exist m1: 56|5@1+ (3.125,0) [0|0] "%" X
 SG_ DAS_TR_Obj02_Class m2: 5|3@1+ (1,0) [0|0] "" X
 SG_ DAS_TR_Obj02_Dx m2: 8|10@1+ (0.15625,0) [0|0] "m" X
 SG_ DAS_TR_Obj02_Dy m2: 18|6@1+ (0.5,-15.5) [0|0] "m" X
 SG_ DAS_TR_Obj02_Vx m2: 24|8@1+ (0.5,-63.5) [0|0] "m/s" X
 SG_ DAS_TR_Obj02_RCS m2: 32|8@1+ (0.25,-14) [0|0] "dB" X
 SG_ DAS_TR_Obj02_Length m2: 40|6@1+ (0.125,0) [0|0] "m" X
 SG_ DAS_TR_Obj02_MovingState m2: 46|2@1+ (1,0) [0|0] "" X
 SG_ DAS_TR_Obj02_Dz m2: 48|6@1+ (0.25,-5) [0|0] "m" X
 SG_ DAS_TR_Obj02_Exist m2: 56|5@1+ (3.125,0) [0|0] "%" X
 SG_ DAS_TR_Obj03_Class m3: 5|3@1+ (1,0) [0|0] "" X
 SG_ DAS_TR_Obj03_Dx m3: 8|10@1+ (0.15625,0) [0|0] "m" X
 SG_ DAS_TR_Obj03_Dy m3: 18|6@1+ (0.5,-15.5) [0|0] "m" X
 SG_ DAS_TR_Obj03_Vx m3: 24|8@1+ (0.5,-63.5) [0|0] "m/s" X
 SG_ DAS_TR_Obj03_RCS m3: 32|8@1+ (0.25,-14) [0|0] "dB" X
 SG_ DAS_TR_Obj03_Length m3: 40|6@1+ (0.125,0) [0|0] "m" X
 SG_ DAS_TR_Obj03_MovingState m3: 46|2@1+ (1,0) [0|0] "" X
 SG_ DAS_TR_Obj03_Dz m3: 48|6@1+ (0.25,-5) [0|0] "m" X
 SG_ DAS_TR_Obj03_Exist m3: 56|5@1+ (3.125,0) [0|0] "%" X
 SG_ DAS_TR_Obj04_Class m4: 5|3@1+ (1,0) [0|0] "" X
 SG_ DAS_TR_Obj04_Dx m4: 8|10@1+ (0.15625,0) [0|0] "m" X
 SG_ DAS_TR_Obj04_Dy m4: 18|6@1+ (0.5,-15.5) [0|0] "m" X
 SG_ DAS_TR_Obj04_Vx m4: 24|8@1+ (0.5,-63.5) [0|0] "m/s" X
 SG_ DAS_TR_Obj04_RCS m4: 32|8@1+ (0.25,-14) [0|0] "dB" X
 SG_ DAS_TR_Obj04_Length m4: 40|6@1+ (0.125,0) [0|0] "m" X
 SG_ DAS_TR_Obj04_MovingState m4: 46|2@1+ (1,0) [0|0] "" X
 SG_ DAS_TR_Obj04_Dz m4: 48|6@1+ (0.25,-5) [0|0] "m" X
 SG_ DAS_TR_Obj04_Exist m4: 56|5@1+ (3.125,0) [0|0] "%" X
 SG_ DAS_TR_Obj05_Class m5: 5|3@1+ (1,0) [0|0] "" X
 SG_ DAS_TR_Obj05_Dx m5: 8|10@1+ (0.15625,0) [0|0] "m" X
 SG_ DAS_TR_Obj05_Dy m5: 18|6@1+ (0.5,-15.5) [0|0] "m" X
 SG_ DAS_TR_Obj05_Vx m5: 24|8@1+ (0.5,-63.5) [0|0] "m/s" X
 SG_ DAS_TR_Obj05_RCS m5: 32|8@1+ (0.25,-14) [0|0] "dB" X
 SG_ DAS_TR_Obj05_Length m5: 40|6@1+ (0.125,0) [0|0] "m" X
 SG_ DAS_TR_Obj05_MovingState m5: 46|2@1+ (1,0) [0|0] "" X
 SG_ DAS_TR_Obj05_Dz m5: 48|6@1+ (0.25,-5) [0|0] "m" X
 SG_ DAS_TR_Obj05_Exist m5: 56|5@1+ (3.125,0) [0|0] "%" X
 SG_ DAS_TR_Obj06_Class m6: 5|3@1+ (1,0) [0|0] "" X
 SG_ DAS_TR_Obj06_Dx m6: 8|10@1+ (0.15625,0) [0|0] "m" X
 SG_ DAS_TR_Obj06_Dy m6: 18|6@1+ (0.5,-15.5) [0|0] "m" X
 SG_ DAS_TR_Obj06_Vx m6: 24|8@1+ (0.5,-63.5) [0|0] "m/s" X
 SG_ DAS_TR_Obj06_RCS m6: 32|8@1+ (0.25,-14) [0|0] "dB" X
 SG_ DAS_TR_Obj06_Length m6: 40|6@1+ (0.125,0) [0|0] "m" X
 SG_ DAS_TR_Obj06_MovingState m6: 46|2@1+ (1,0) [0|0] "" X
 SG_ DAS_TR_Obj06_Dz m6: 48|6@1+ (0.25,-5) [0|0] "m" X
 SG_ DAS_TR_Obj06_Exist m6: 56|5@1+ (3.125,0) [0|0] "%" X
 SG_ DAS_TR_Obj07_Class m7: 5|3@1+ (1,0) [0|0] "" X
 SG_ DAS_TR_Obj07_Dx m7: 8|10@1+ (0.15625,0) [0|0] "m" X
 SG_ DAS_TR_Obj07_Dy m7: 18|6@1+ (0.5,-15.5) [0|0] "m" X
 SG_ DAS_TR_Obj07_Vx m7: 24|8@1+ (0.5,-63.5) [0|0] "m/s" X
 SG_ DAS_TR_Obj07_RCS m7: 32|8@1+ (0.25,-14) [0|0] "dB" X
 SG_ DAS_TR_Obj07_Length m7: 40|6@1+ (0.125,0) [0|0] "m" X
 SG_ DAS_TR_Obj07_MovingState m7: 46|2@1+ (1,0) [0|0] "" X
 SG_ DAS_TR_Obj07_Dz m7: 48|6@1+ (0.25,-5) [0|0] "m" X
 SG_ DAS_TR_Obj07_Exist m7: 56|5@1+ (3.125,0) [0|0] "%" X
 SG_ DAS_TR_Obj08_Class m8: 5|3@1+ (1,0) [0|0] "" X
 SG_ DAS_TR_Obj08_Dx m8: 8|10@1+ (0.15625,0) [0|0] "m" X
 SG_ DAS_TR_Obj08_Dy m8: 18|6@1+ (0.5,-15.5) [0|0] "m" X
 SG_ DAS_TR_Obj08_Vx m8: 24|8@1+ (0.5,-63.5) [0|0] "m/s" X
 SG_ DAS_TR_Obj08_RCS m8: 32|8@1+ (0.25,-14) [0|0] "dB" X
 SG_ DAS_TR_Obj08_Length m8: 40|6@1+ (0.125,0) [0|0] "m" X
 SG_ DAS_TR_Obj08_MovingState m8: 46|2@1+ (1,0) [0|0] "" X
 SG_ DAS_TR_Obj08_Dz m8: 48|6@1+ (0.25,-5) [0|0] "m" X
 SG_ DAS_TR_Obj08_Exist m8: 56|5@1+ (3.125,0) [0|0] "%" X
 SG_ DAS_TR_Obj09_Class m9: 5|3@1+ (1,0) [0|0] "" X
 SG_ DAS_TR_Obj09_Dx m9: 8|10@1+ (0.15625,0) [0|0] "m" X
 SG_ DAS_TR_Obj09_Dy m9: 18|6@1+ (0.5,-15.5) [0|0] "m" X
 SG_ DAS_TR_Obj09_Vx m9: 24|8@1+ (0.5,-63.5) [0|0] "m/s" X
 SG_ DAS_TR_Obj09_RCS m9: 32|8@1+ (0.25,-14) [0|0] "dB" X
 SG_ DAS_TR_Obj09_Length m9: 40|6@1+ (0.125,0) [0|0] "m" X
 SG_ DAS_TR_Obj09_MovingState m9: 46|2@1+ (1,0) [0|0] "" X
 SG_ DAS_TR_Obj09_Dz m9: 48|6@1+ (0.25,-5) [0|0] "m" X
 SG_ DAS_TR_Obj09_Exist m9: 56|5@1+ (3.125,0) [0|0] "%" X
 SG_ DAS_TR_Obj10_Class m10: 5|3@1+ (1,0) [0|0] "" X
 SG_ DAS_TR_Obj10_Dx m10: 8|10@1+ (0.15625,0) [0|0] "m" X
 SG_ DAS_TR_Obj10_Dy m10: 18|6@1+ (0.5,-15.5) [0|0] "m" X
 SG_ DAS_TR_Obj10_Vx m10: 24|8@1+ (0.5,-63.5) [0|0] "m/s" X
 SG_ DAS_TR_Obj10_RCS m10: 32|8@1+ (0.25,-14) [0|0] "dB" X
 SG_ DAS_TR_Obj10_Length m10: 40|6@1+ (0.125,0) [0|0] "m" X
 SG_ DAS_TR_Obj10_MovingState m10: 46|2@1+ (1,0) [0|0] "" X
 SG_ DAS_TR_Obj10_Dz m10: 48|6@1+ (0.25,-5) [0|0] "m" X
 SG_ DAS_TR_Obj10_Exist m10: 56|5@1+ (3.125,0) [0|0] "%" X
 SG_ DAS_TR_Obj11_Class m11: 5|3@1+ (1,0) [0|0] "" X
 SG_ DAS_TR_Obj11_Dx m11: 8|10@1+ (0.15625,0) [0|0] "m" X
 SG_ DAS_TR_Obj11_Dy m11: 18|6@1+ (0.5,-15.5) [0|0] "m" X
 SG_ DAS_TR_Obj11_Vx m11: 24|8@1+ (0.5,-63.5) [0|0] "m/s" X
 SG_ DAS_TR_Obj11_RCS m11: 32|8@1+ (0.25,-14) [0|0] "dB" X
 SG_ DAS_TR_Obj11_Length m11: 40|6@1+ (0.125,0) [0|0] "m" X
 SG_ DAS_TR_Obj11_MovingState m11: 46|2@1+ (1,0) [0|0] "" X
 SG_ DAS_TR_Obj11_Dz m11: 48|6@1+ (0.25,-5) [0|0] "m" X
 SG_ DAS_TR_Obj11_Exist m11: 56|5@1+ (3.125,0) [0|0] "%" X
 SG_ DAS_TR_Obj12_Class m12: 5|3@1+ (1,0) [0|0] "" X
 SG_ DAS_TR_Obj12_Dx m12: 8|10@1+ (0.15625,0) [0|0] "m" X
 SG_ DAS_TR_Obj12_Dy m12: 18|6@1+ (0.5,-15.5) [0|0] "m" X
 SG_ DAS_TR_Obj12_Vx m12: 24|8@1+ (0.5,-63.5) [0|0] "m/s" X
 SG_ DAS_TR_Obj12_RCS m12: 32|8@1+ (0.25,-14) [0|0] "dB" X
 SG_ DAS_TR_Obj12_Length m12: 40|6@1+ (0.125,0) [0|0] "m" X
 SG_ DAS_TR_Obj12_MovingState m12: 46|2@1+ (1,0) [0|0] "" X
 SG_ DAS_TR_Obj12_Dz m12: 48|6@1+ (0.25,-5) [0|0] "m" X
 SG_ DAS_TR_Obj12_Exist m12: 56|5@1+ (3.125,0) [0|0] "%" X
 SG_ DAS_TR_Obj13_Class m13: 5|3@1+ (1,0) [0|0] "" X
 SG_ DAS_TR_Obj13_Dx m13: 8|10@1+ (0.15625,0) [0|0] "m" X
 SG_ DAS_TR_Obj13_Dy m13: 18|6@1+ (0.5,-15.5) [0|0] "m" X
 SG_ DAS_TR_Obj13_Vx m13: 24|8@1+ (0.5,-63.5) [0|0] "m/s" X
 SG_ DAS_TR_Obj13_RCS m13: 32|8@1+ (0.25,-14) [0|0] "dB" X
 SG_ DAS_TR_Obj13_Length m13: 40|6@1+ (0.125,0) [0|0] "m" X
 SG_ DAS_TR_Obj13_MovingState m13: 46|2@1+ (1,0) [0|0] "" X
 SG_ DAS_TR_Obj13_Dz m13: 48|6@1+ (0.25,-5) [0|0] "m" X
 SG_ DAS_TR_Obj13_Exist m13: 56|5@1+ (3.125,0) [0|0] "%" X
 SG_ DAS_TR_Obj14_Class m14: 5|3@1+ (1,0) [0|0] "" X
 SG_ DAS_TR_Obj14_Dx m14: 8|10@1+ (0.15625,0) [0|0] "m" X
 SG_ DAS_TR_Obj14_Dy m14: 18|6@1+ (0.5,-15.5) [0|0] "m" X
 SG_ DAS_TR_Obj14_Vx m14: 24|8@1+ (0.5,-63.5) [0|0] "m/s" X
 SG_ DAS_TR_Obj14_RCS m14: 32|8@1+ (0.25,-14) [0|0] "dB" X
 SG_ DAS_TR_Obj14_Length m14: 40|6@1+ (0.125,0) [0|0] "m" X
 SG_ DAS_TR_Obj14_MovingState m14: 46|2@1+ (1,0) [0|0] "" X
 SG_ DAS_TR_Obj14_Dz m14: 48|6@1+ (0.25,-5) [0|0] "m" X
 SG_ DAS_TR_Obj14_Exist m14: 56|5@1+ (3.125,0) [0|0] "%" X
 SG_ DAS_TR_Obj15_Class m15: 5|3@1+ (1,0) [0|0] "" X
 SG_ DAS_TR_Obj15_Dx m15: 8|10@1+ (0.15625,0) [0|0] "m" X
 SG_ DAS_TR_Obj15_Dy m15: 18|6@1+ (0.5,-15.5) [0|0] "m" X
 SG_ DAS_TR_Obj15_Vx m15: 24|8@1+ (0.5,-63.5) [0|0] "m/s" X
 SG_ DAS_TR_Obj15_RCS m15: 32|8@1+ (0.25,-14) [0|0] "dB" X
 SG_ DAS_TR_Obj15_Length m15: 40|6@1+ (0.125,0) [0|0] "m" X
 SG_ DAS_TR_Obj15_MovingState m15: 46|2@1+ (1,0) [0|0] "" X
 SG_ DAS_TR_Obj15_Dz m15: 48|6@1+ (0.25,-5) [0|0] "m" X
 SG_ DAS_TR_Obj15_Exist m15: 56|5@1+ (3.125,0) [0|0] "%" X
 SG_ DAS_TR_Obj16_Class m16: 5|3@1+ (1,0) [0|0] "" X
 SG_ DAS_TR_Obj16_Dx m16: 8|10@1+ (0.15625,0) [0|0] "m" X
 SG_ DAS_TR_Obj16_Dy m16: 18|6@1+ (0.5,-15.5) [0|0] "m" X
 SG_ DAS_TR_Obj16_Vx m16: 24|8@1+ (0.5,-63.5) [0|0] "m/s" X
 SG_ DAS_TR_Obj16_RCS m16: 32|8@1+ (0.25,-14) [0|0] "dB" X
 SG_ DAS_TR_Obj16_Length m16: 40|6@1+ (0.125,0) [0|0] "m" X
 SG_ DAS_TR_Obj16_MovingState m16: 46|2@1+ (1,0) [0|0] "" X
 SG_ DAS_TR_Obj16_Dz m16: 48|6@1+ (0.25,-5) [0|0] "m" X
 SG_ DAS_TR_Obj16_Exist m16: 56|5@1+ (3.125,0) [0|0] "%" X
 SG_ DAS_TR_Obj17_Class m17: 5|3@1+ (1,0) [0|0] "" X
 SG_ DAS_TR_Obj17_Dx m17: 8|10@1+ (0.15625,0) [0|0] "m" X
 SG_ DAS_TR_Obj17_Dy m17: 18|6@1+ (0.5,-15.5) [0|0] "m" X
 SG_ DAS_TR_Obj17_Vx m17: 24|8@1+ (0.5,-63.5) [0|0] "m/s" X
 SG_ DAS_TR_Obj17_RCS m17: 32|8@1+ (0.25,-14) [0|0] "dB" X
 SG_ DAS_TR_Obj17_Length m17: 40|6@1+ (0.125,0) [0|0] "m" X
 SG_ DAS_TR_Obj17_MovingState m17: 46|2@1+ (1,0) [0|0] "" X
 SG_ DAS_TR_Obj17_Dz m17: 48|6@1+ (0.25,-5) [0|0] "m" X
 SG_ DAS_TR_Obj17_Exist m17: 56|5@1+ (3.125,0) [0|0] "%" X
 SG_ DAS_TR_Obj18_Class m18: 5|3@1+ (1,0) [0|0] "" X
 SG_ DAS_TR_Obj18_Dx m18: 8|10@1+ (0.15625,0) [0|0] "m" X
 SG_ DAS_TR_Obj18_Dy m18: 18|6@1+ (0.5,-15.5) [0|0] "m" X
 SG_ DAS_TR_Obj18_Vx m18: 24|8@1+ (0.5,-63.5) [0|0] "m/s" X
 SG_ DAS_TR_Obj18_RCS m18: 32|8@1+ (0.25,-14) [0|0] "dB" X
 SG_ DAS_TR_Obj18_Length m18: 40|6@1+ (0.125,0) [0|0] "m" X
 SG_ DAS_TR_Obj18_MovingState m18: 46|2@1+ (1,0) [0|0] "" X
 SG_ DAS_TR_Obj18_Dz m18: 48|6@1+ (0.25,-5) [0|0] "m" X
 SG_ DAS_TR_Obj18_Exist m18: 56|5@1+ (3.125,0) [0|0] "%" X
 SG_ DAS_TR_Obj19_Class m19: 5|3@1+ (1,0) [0|0] "" X
 SG_ DAS_TR_Obj19_Dx m19: 8|10@1+ (0.15625,0) [0|0] "m" X
 SG_ DAS_TR_Obj19_Dy m19: 18|6@1+ (0.5,-15.5) [0|0] "m" X
 SG_ DAS_TR_Obj19_Vx m19: 24|8@1+ (0.5,-63.5) [0|0] "m/s" X
 SG_ DAS_TR_Obj19_RCS m19: 32|8@1+ (0.25,-14) [0|0] "dB" X
 SG_ DAS_TR_Obj19_Length m19: 40|6@1+ (0.125,0) [0|0] "m" X
 SG_ DAS_TR_Obj19_MovingState m19: 46|2@1+ (1,0) [0|0] "" X
 SG_ DAS_TR_Obj19_Dz m19: 48|6@1+ (0.25,-5) [0|0] "m" X
 SG_ DAS_TR_Obj19_Exist m19: 56|5@1+ (3.125,0) [0|0] "%" X
 SG_ DAS_TR_Obj20_Class m20: 5|3@1+ (1,0) [0|0] "" X
 SG_ DAS_TR_Obj20_Dx m20: 8|10@1+ (0.15625,0) [0|0] "m" X
 SG_ DAS_TR_Obj20_Dy m20: 18|6@1+ (0.5,-15.5) [0|0] "m" X
 SG_ DAS_TR_Obj20_Vx m20: 24|8@1+ (0.5,-63.5) [0|0] "m/s" X
 SG_ DAS_TR_Obj20_RCS m20: 32|8@1+ (0.25,-14) [0|0] "dB" X
 SG_ DAS_TR_Obj20_Length m20: 40|6@1+ (0.125,0) [0|0] "m" X
 SG_ DAS_TR_Obj20_MovingState m20: 46|2@1+ (1,0) [0|0] "" X
 SG_ DAS_TR_Obj20_Dz m20: 48|6@1+ (0.25,-5) [0|0] "m" X
 SG_ DAS_TR_Obj20_Exist m20: 56|5@1+ (3.125,0) [0|0] "%" X
 SG_ DAS_TR_Obj21_Class m21: 5|3@1+ (1,0) [0|0] "" X
 SG_ DAS_TR_Obj21_Dx m21: 8|10@1+ (0.15625,0) [0|0] "m" X
 SG_ DAS_TR_Obj21_Dy m21: 18|6@1+ (0.5,-15.5) [0|0] "m" X
 SG_ DAS_TR_Obj21_Vx m21: 24|8@1+ (0.5,-63.5) [0|0] "m/s" X
 SG_ DAS_TR_Obj21_RCS m21: 32|8@1+ (0.25,-14) [0|0] "dB" X
 SG_ DAS_TR_Obj21_Length m21: 40|6@1+ (0.125,0) [0|0] "m" X
 SG_ DAS_TR_Obj21_MovingState m21: 46|2@1+ (1,0) [0|0] "" X
 SG_ DAS_TR_Obj21_Dz m21: 48|6@1+ (0.25,-5) [0|0] "m" X
 SG_ DAS_TR_Obj21_Exist m21: 56|5@1+ (3.125,0) [0|0] "%" X
 SG_ DAS_TR_Obj22_Class m22: 5|3@1+ (1,0) [0|0] "" X
 SG_ DAS_TR_Obj22_Dx m22: 8|10@1+ (0.15625,0) [0|0] "m" X
 SG_ DAS_TR_Obj22_Dy m22: 18|6@1+ (0.5,-15.5) [0|0] "m" X
 SG_ DAS_TR_Obj22_Vx m22: 24|8@1+ (0.5,-63.5) [0|0] "m/s" X
 SG_ DAS_TR_Obj22_RCS m22: 32|8@1+ (0.25,-14) [0|0] "dB" X
 SG_ DAS_TR_Obj22_Length m22: 40|6@1+ (0.125,0) [0|0] "m" X
 SG_ DAS_TR_Obj22_MovingState m22: 46|2@1+ (1,0) [0|0] "" X
 SG_ DAS_TR_Obj22_Dz m22: 48|6@1+ (0.25,-5) [0|0] "m" X
 SG_ DAS_TR_Obj22_Exist m22: 56|5@1+ (3.125,0) [0|0] "%" X
 SG_ DAS_TR_Obj23_Class m23: 5|3@1+ (1,0) [0|0] "" X
 SG_ DAS_TR_Obj23_Dx m23: 8|10@1+ (0.15625,0) [0|0] "m" X
 SG_ DAS_TR_Obj23_Dy m23: 18|6@1+ (0.5,-15.5) [0|0] "m" X
 SG_ DAS_TR_Obj23_Vx m23: 24|8@1+ (0.5,-63.5) [0|0] "m/s" X
 SG_ DAS_TR_Obj23_RCS m23: 32|8@1+ (0.25,-14) [0|0] "dB" X
 SG_ DAS_TR_Obj23_Length m23: 40|6@1+ (0.125,0) [0|0] "m" X
 SG_ DAS_TR_Obj23_MovingState m23: 46|2@1+ (1,0) [0|0] "" X
 SG_ DAS_TR_Obj23_Dz m23: 48|6@1+ (0.25,-5) [0|0] "m" X
 SG_ DAS_TR_Obj23_Exist m23: 56|5@1+ (3.125,0) [0|0] "%" X
 SG_ DAS_TR_Obj24_Class m24: 5|3@1+ (1,0) [0|0] "" X
 SG_ DAS_TR_Obj24_Dx m24: 8|10@1+ (0.15625,0) [0|0] "m" X
 SG_ DAS_TR_Obj24_Dy m24: 18|6@1+ (0.5,-15.5) [0|0] "m" X
 SG_ DAS_TR_Obj24_Vx m24: 24|8@1+ (0.5,-63.5) [0|0] "m/s" X
 SG_ DAS_TR_Obj24_RCS m24: 32|8@1+ (0.25,-14) [0|0] "dB" X
 SG_ DAS_TR_Obj24_Length m24: 40|6@1+ (0.125,0) [0|0] "m" X
 SG_ DAS_TR_Obj24_MovingState m24: 46|2@1+ (1,0) [0|0] "" X
 SG_ DAS_TR_Obj24_Dz m24: 48|6@1+ (0.25,-5) [0|0] "m" X
 SG_ DAS_TR_Obj24_Exist m24: 56|5@1+ (3.125,0) [0|0] "%" X
 SG_ DAS_TR_Obj25_Class m25: 5|3@1+ (1,0) [0|0] "" X
 SG_ DAS_TR_Obj25_Dx m25: 8|10@1+ (0.15625,0) [0|0] "m" X
 SG_ DAS_TR_Obj25_Dy m25: 18|6@1+ (0.5,-15.5) [0|0] "m" X
 SG_ DAS_TR_Obj25_Vx m25: 24|8@1+ (0.5,-63.5) [0|0] "m/s" X
 SG_ DAS_TR_Obj25_RCS m25: 32|8@1+ (0.25,-14) [0|0] "dB" X
 SG_ DAS_TR_Obj25_Length m25: 40|6@1+ (0.125,0) [0|0] "m" X
 SG_ DAS_TR_Obj25_MovingState m25: 46|2@1+ (1,0) [0|0] "" X
 SG_ DAS_TR_Obj25_Dz m25: 48|6@1+ (0.25,-5) [0|0] "m" X
 SG_ DAS_TR_Obj25_Exist m25: 56|5@1+ (3.125,0) [0|0] "%" X
 SG_ DAS_TR_Obj26_Class m26: 5|3@1+ (1,0) [0|0] "" X
 SG_ DAS_TR_Obj26_Dx m26: 8|10@1+ (0.15625,0) [0|0] "m" X
 SG_ DAS_TR_Obj26_Dy m26: 18|6@1+ (0.5,-15.5) [0|0] "m" X
 SG_ DAS_TR_Obj26_Vx m26: 24|8@1+ (0.5,-63.5) [0|0] "m/s" X
 SG_ DAS_TR_Obj26_RCS m26: 32|8@1+ (0.25,-14) [0|0] "dB" X
 SG_ DAS_TR_Obj26_Length m26: 40|6@1+ (0.125,0) [0|0] "m" X
 SG_ DAS_TR_Obj26_MovingState m26: 46|2@1+ (1,0) [0|0] "" X
 SG_ DAS_TR_Obj26_Dz m26: 48|6@1+ (0.25,-5) [0|0] "m" X
 SG_ DAS_TR_Obj26_Exist m26: 56|5@1+ (3.125,0) [0|0] "%" X
 SG_ DAS_TR_Obj27_Class m27: 5|3@1+ (1,0) [0|0] "" X
 SG_ DAS_TR_Obj27_Dx m27: 8|10@1+ (0.15625,0) [0|0] "m" X
 SG_ DAS_TR_Obj27_Dy m27: 18|6@1+ (0.5,-15.5) [0|0] "m" X
 SG_ DAS_TR_Obj27_Vx m27: 24|8@1+ (0.5,-63.5) [0|0] "m/s" X
 SG_ DAS_TR_Obj27_RCS m27: 32|8@1+ (0.25,-14) [0|0] "dB" X
 SG_ DAS_TR_Obj27_Length m27: 40|6@1+ (0.125,0) [0|0] "m" X
 SG_ DAS_TR_Obj27_MovingState m27: 46|2@1+ (1,0) [0|0] "" X
 SG_ DAS_TR_Obj27_Dz m27: 48|6@1+ (0.25,-5) [0|0] "m" X
 SG_ DAS_TR_Obj27_Exist m27: 56|5@1+ (3.125,0) [0|0] "%" X
 SG_ DAS_TR_Obj28_Class m28: 5|3@1+ (1,0) [0|0] "" X
 SG_ DAS_TR_Obj28_Dx m28: 8|10@1+ (0.15625,0) [0|0] "m" X
 SG_ DAS_TR_Obj28_Dy m28: 18|6@1+ (0.5,-15.5) [0|0] "m" X
 SG_ DAS_TR_Obj28_Vx m28: 24|8@1+ (0.5,-63.5) [0|0] "m/s" X
 SG_ DAS_TR_Obj28_RCS m28: 32|8@1+ (0.25,-14) [0|0] "dB" X
 SG_ DAS_TR_Obj28_Length m28: 40|6@1+ (0.125,0) [0|0] "m" X
 SG_ DAS_TR_Obj28_MovingState m28: 46|2@1+ (1,0) [0|0] "" X
 SG_ DAS_TR_Obj28_Dz m28: 48|6@1+ (0.25,-5) [0|0] "m" X
 SG_ DAS_TR_Obj28_Exist m28: 56|5@1+ (3.125,0) [0|0] "%" X
 SG_ DAS_TR_Obj29_Class m29: 5|3@1+ (1,0) [0|0] "" X
 SG_ DAS_TR_Obj29_Dx m29: 8|10@1+ (0.15625,0) [0|0] "m" X
 SG_ DAS_TR_Obj29_Dy m29: 18|6@1+ (0.5,-15.5) [0|0] "m" X
 SG_ DAS_TR_Obj29_Vx m29: 24|8@1+ (0.5,-63.5) [0|0] "m/s" X
 SG_ DAS_TR_Obj29_RCS m29: 32|8@1+ (0.25,-14) [0|0] "dB" X
 SG_ DAS_TR_Obj29_Length m29: 40|6@1+ (0.125,0) [0|0] "m" X
 SG_ DAS_TR_Obj29_MovingState m29: 46|2@1+ (1,0) [0|0] "" X
 SG_ DAS_TR_Obj29_Dz m29: 48|6@1+ (0.25,-5) [0|0] "m" X
 SG_ DAS_TR_Obj29_Exist m29: 56|5@1+ (3.125,0) [0|0] "%" X
 SG_ DAS_TR_Obj30_Class m30: 5|3@1+ (1,0) [0|0] "" X
 SG_ DAS_TR_Obj30_Dx m30: 8|10@1+ (0.15625,0) [0|0] "m" X
 SG_ DAS_TR_Obj30_Dy m30: 18|6@1+ (0.5,-15.5) [0|0] "m" X
 SG_ DAS_TR_Obj30_Vx m30: 24|8@1+ (0.5,-63.5) [0|0] "m/s" X
 SG_ DAS_TR_Obj30_RCS m30: 32|8@1+ (0.25,-14) [0|0] "dB" X
 SG_ DAS_TR_Obj30_Length m30: 40|6@1+ (0.125,0) [0|0] "m" X
 SG_ DAS_TR_Obj30_MovingState m30: 46|2@1+ (1,0) [0|0] "" X
 SG_ DAS_TR_Obj30_Dz m30: 48|6@1+ (0.25,-5) [0|0] "m" X
 SG_ DAS_TR_Obj30_Exist m30: 56|5@1+ (3.125,0) [0|0] "%" X
 SG_ DAS_TR_Obj31_Class m31: 5|3@1+ (1,0) [0|0] "" X
 SG_ DAS_TR_Obj31_Dx m31: 8|10@1+ (0.15625,0) [0|0] "m" X
 SG_ DAS_TR_Obj31_Dy m31: 18|6@1+ (0.5,-15.5) [0|0] "m" X
 SG_ DAS_TR_Obj31_Vx m31: 24|8@1+ (0.5,-63.5) [0|0] "m/s" X
 SG_ DAS_TR_Obj31_RCS m31: 32|8@1+ (0.25,-14) [0|0] "dB" X
 SG_ DAS_TR_Obj31_Length m31: 40|6@1+ (0.125,0) [0|0] "m" X
 SG_ DAS_TR_Obj31_MovingState m31: 46|2@1+ (1,0) [0|0] "" X
 SG_ DAS_TR_Obj31_Dz m31: 48|6@1+ (0.25,-5) [0|0] "m" X
 SG_ DAS_TR_Obj31_Exist m31: 56|5@1+ (3.125,0) [0|0] "%" X

BO_ 586 DAS_visualDebug: 8 CH
 SG_ DAS_accSmartSpeedActive: 48|1@1+ (1,0) [0|0] "" X
 SG_ DAS_accSmartSpeedState: 49|3@1+ (1,0) [0|0] "" X
 SG_ DAS_autosteerBottsDotsUsage: 12|2@1+ (1,0) [0|0] "" X
 SG_ DAS_autosteerHPPUsage: 6|2@1+ (1,0) [0|0] "" X
 SG_ DAS_autosteerHealthAnomalyLevel: 18|3@1+ (1,0) [0|0] "" X
 SG_ DAS_autosteerHealthState: 21|3@1+ (1,0) [0|0] "" X
 SG_ DAS_autosteerModelUsage: 10|2@1+ (1,0) [0|0] "" X
 SG_ DAS_autosteerNavigationUsage: 8|2@1+ (1,0) [0|0] "" X
 SG_ DAS_autosteerVehiclesUsage: 4|2@1+ (1,0) [0|0] "" X
 SG_ DAS_behaviorType: 56|2@1+ (1,0) [0|0] "" X
 SG_ DAS_devAppInterfaceEnabled: 38|1@1+ (1,0) [0|0] "" X
 SG_ DAS_lastAutosteerAbortReason: 32|6@1+ (1,0) [0|0] "" X
 SG_ DAS_lastLinePreferenceReason: 24|4@1+ (1,0) [0|0] "" X
 SG_ DAS_navAvailable: 39|1@1+ (1,0) [0|0] "" X
 SG_ DAS_navDistance: 40|8@1+ (100,0) [0|0] "km" X
 SG_ DAS_offsetSide: 14|2@1+ (1,0) [0|0] "" X
 SG_ DAS_plannerState: 28|4@1+ (1,0) [0|0] "" X
 SG_ DAS_roadSurfaceType: 16|2@1+ (1,0) [0|0] "" X
 SG_ DAS_ulcInProgress: 52|1@1+ (1,0) [0|0] "" X
 SG_ DAS_ulcType: 58|1@1+ (1,0) [0|0] "" X

BO_ 810 BMS_vehicleNotifications: 5 Vector__XXX
 SG_ BMS_vehicleNotificationsChecksum : 32|8@1+ (1,0) [0|0] "" Vector__XXX
 SG_ BMS_chgTimeToFull : 16|12@1+ (0.01666667,0) [0|0] "" Vector__XXX
 SG_ BMS_isolationResistance : 6|10@1+ (10,0) [0|0] "" Vector__XXX
 SG_ BMS_vehicleNotificationsCounter : 1|4@1+ (1,0) [0|0] "" Vector__XXX
 SG_ BMS_thermalEventSuspected : 0|1@1+ (1,0) [0|0] "" Vector__XXX

BO_ 874 DAS_warningMatrix1: 8 VEH
 SG_ DAS_w065_deserializerOvercurrent: 0|1@1+ (1,0) [0|0] "" X
 SG_ DAS_w066_deserializerLockLost: 1|1@1+ (1,0) [0|0] "" X
 SG_ DAS_w067_steeringAlignment: 2|1@1+ (1,0) [0|0] "" X
 SG_ DAS_w068_vlInconsistency: 3|1@1+ (1,0) [0|0] "" X
 SG_ DAS_w069_apcSpaceMasked: 4|1@1+ (1,0) [0|0] "" X
 SG_ DAS_w070_apcIncompleteCal: 5|1@1+ (1,0) [0|0] "" X
 SG_ DAS_w071_selfparkStarted: 6|1@1+ (1,0) [0|0] "" X
 SG_ DAS_w072_selfparkComplete: 7|1@1+ (1,0) [0|0] "" X
 SG_ DAS_w073_issueEscalatedLDW: 8|1@1+ (1,0) [0|0] "" X
 SG_ DAS_w074_inPathStationaryObst: 9|1@1+ (1,0) [0|0] "" X
 SG_ DAS_w075_scMia: 10|1@1+ (1,0) [0|0] "" X
 SG_ DAS_w076_mobilEyeSetC: 11|1@1+ (1,0) [0|0] "" X
 SG_ DAS_w077_pmmActive: 12|1@1+ (1,0) [0|0] "" X
 SG_ DAS_w078_pmmActive2: 13|1@1+ (1,0) [0|0] "" X
 SG_ DAS_w079_edrAvailable: 14|1@1+ (1,0) [0|0] "" X
 SG_ DAS_w080_accFailedActivation: 15|1@1+ (1,0) [0|0] "" X
 SG_ DAS_w081_pmmActiveBraking: 16|1@1+ (1,0) [0|0] "" X
 SG_ DAS_w082_inPathFSviolation: 17|1@1+ (1,0) [0|0] "" X
 SG_ DAS_w083_inPathRADObject: 18|1@1+ (1,0) [0|0] "" X
 SG_ DAS_w084_pmmIPSO: 19|1@1+ (1,0) [0|0] "" X
 SG_ DAS_w085_pmmSteering: 20|1@1+ (1,0) [0|0] "" X
 SG_ DAS_w086_robCollision: 21|1@1+ (1,0) [0|0] "" X
 SG_ DAS_w087_DEPRECATED: 22|1@1+ (1,0) [0|0] "" X
 SG_ DAS_w088_DEPRECATED: 23|1@1+ (1,0) [0|0] "" X
 SG_ DAS_w089_DEPRECATED: 24|1@1+ (1,0) [0|0] "" X
 SG_ DAS_w090_DEPRECATED: 25|1@1+ (1,0) [0|0] "" X
 SG_ DAS_w091_DEPRECATED: 26|1@1+ (1,0) [0|0] "" X
 SG_ DAS_w092_DEPRECATED: 27|1@1+ (1,0) [0|0] "" X
 SG_ DAS_w093_DEPRECATED: 28|1@1+ (1,0) [0|0] "" X
 SG_ DAS_w094_DEPRECATED: 29|1@1+ (1,0) [0|0] "" X
 SG_ DAS_w095_DEPRECATED: 30|1@1+ (1,0) [0|0] "" X
 SG_ DAS_w096_DEPRECATED: 31|1@1+ (1,0) [0|0] "" X
 SG_ DAS_w097_DEPRECATED: 32|1@1+ (1,0) [0|0] "" X
 SG_ DAS_w098_DEPRECATED: 33|1@1+ (1,0) [0|0] "" X
 SG_ DAS_w099_DEPRECATED: 34|1@1+ (1,0) [0|0] "" X
 SG_ DAS_w100_DEPRECATED: 35|1@1+ (1,0) [0|0] "" X
 SG_ DAS_w101_DEPRECATED: 36|1@1+ (1,0) [0|0] "" X
 SG_ DAS_w102_DEPRECATED: 37|1@1+ (1,0) [0|0] "" X
 SG_ DAS_w103_robExperimentalAEB: 38|1@1+ (1,0) [0|0] "" X
 SG_ DAS_w104_DEPRECATED: 39|1@1+ (1,0) [0|0] "" X
 SG_ DAS_w105_DEPRECATED: 40|1@1+ (1,0) [0|0] "" X
 SG_ DAS_w106_torsionBarCalibrated: 41|1@1+ (1,0) [0|0] "" X

CM_ "Generated by Tesla Firmware Decode @ version 923e442d6230241a259eeb3f415525373d40325c";

BA_DEF_ BO_ "GenMsgSendType" ENUM "Cyclic";
BA_DEF_ BO_ "GenMsgCycleTime" INT 0 10000;

BA_ "GenMsgSendType" BO_ 600 0;
BA_ "GenMsgCycleTime" BO_ 600 100;

BA_ "GenMsgSendType" BO_ 1020 0;
BA_ "GenMsgCycleTime" BO_ 1020 1000;

BA_ "GenMsgSendType" BO_ 1012 0;
BA_ "GenMsgCycleTime" BO_ 1012 1000;

BA_ "GenMsgSendType" BO_ 1018 0;
BA_ "GenMsgCycleTime" BO_ 1018 500;

BA_ "GenMsgSendType" BO_ 1040 0;
BA_ "GenMsgCycleTime" BO_ 1040 500;

BA_ "GenMsgSendType" BO_ 1353 0;
BA_ "GenMsgCycleTime" BO_ 1353 1000;

BA_ "GenMsgSendType" BO_ 601 0;
BA_ "GenMsgCycleTime" BO_ 601 100;

BA_ "GenMsgSendType" BO_ 809 0;
BA_ "GenMsgCycleTime" BO_ 809 1000;

BA_ "GenMsgSendType" BO_ 873 0;
BA_ "GenMsgCycleTime" BO_ 873 1000;

BA_ "GenMsgSendType" BO_ 1065 0;
BA_ "GenMsgCycleTime" BO_ 1065 1000;

BA_ "GenMsgSendType" BO_ 1081 0;
BA_ "GenMsgCycleTime" BO_ 1081 1000;

BA_ "GenMsgSendType" BO_ 1097 0;
BA_ "GenMsgCycleTime" BO_ 1097 1000;

BA_ "GenMsgSendType" BO_ 637 0;
BA_ "GenMsgCycleTime" BO_ 637 100;

BA_ "GenMsgSendType" BO_ 970 0;
BA_ "GenMsgCycleTime" BO_ 970 500;

BA_ "GenMsgSendType" BO_ 811 0;
BA_ "GenMsgCycleTime" BO_ 811 1000;

BA_ "GenMsgSendType" BO_ 876 0;
BA_ "GenMsgCycleTime" BO_ 876 1000;

BA_ "GenMsgSendType" BO_ 1113 0;
BA_ "GenMsgCycleTime" BO_ 1113 1000;

BA_ "GenMsgSendType" BO_ 848 0;
BA_ "GenMsgCycleTime" BO_ 848 1000;

BA_ "GenMsgSendType" BO_ 800 0;
BA_ "GenMsgCycleTime" BO_ 800 1000;

BA_ "GenMsgSendType" BO_ 818 0;
BA_ "GenMsgCycleTime" BO_ 818 1000;

BA_ "GenMsgSendType" BO_ 690 0;
BA_ "GenMsgCycleTime" BO_ 690 100;

BA_ "GenMsgSendType" BO_ 722 0;
BA_ "GenMsgCycleTime" BO_ 722 100;

BA_ "GenMsgSendType" BO_ 850 0;
BA_ "GenMsgCycleTime" BO_ 850 1000;

BA_ "GenMsgSendType" BO_ 306 0;
BA_ "GenMsgCycleTime" BO_ 306 10;

BA_ "GenMsgSendType" BO_ 768 0;
BA_ "GenMsgCycleTime" BO_ 768 1000;

BA_ "GenMsgSendType" BO_ 978 0;
BA_ "GenMsgCycleTime" BO_ 978 1000;

BA_ "GenMsgSendType" BO_ 1010 0;
BA_ "GenMsgCycleTime" BO_ 1010 1000;

BA_ "GenMsgSendType" BO_ 594 0;
BA_ "GenMsgCycleTime" BO_ 594 100;

BA_ "GenMsgSendType" BO_ 658 0;
BA_ "GenMsgCycleTime" BO_ 658 100;

BA_ "GenMsgSendType" BO_ 530 0;
BA_ "GenMsgCycleTime" BO_ 530 100;

BA_ "GenMsgSendType" BO_ 786 0;
BA_ "GenMsgCycleTime" BO_ 786 1000;

BA_ "GenMsgSendType" BO_ 754 0;
BA_ "GenMsgCycleTime" BO_ 754 100;

BA_ "GenMsgSendType" BO_ 1132 0;
BA_ "GenMsgCycleTime" BO_ 1132 1000;

BA_ "GenMsgSendType" BO_ 796 0;
BA_ "GenMsgCycleTime" BO_ 796 100;

BA_ "GenMsgSendType" BO_ 797 0;
BA_ "GenMsgCycleTime" BO_ 797 100;

BA_ "GenMsgSendType" BO_ 812 0;
BA_ "GenMsgCycleTime" BO_ 812 1000;

BA_ "GenMsgSendType" BO_ 867 0;
BA_ "GenMsgCycleTime" BO_ 867 1000;

BA_ "GenMsgSendType" BO_ 798 0;
BA_ "GenMsgCycleTime" BO_ 798 1000;

BA_ "GenMsgSendType" BO_ 541 0;
BA_ "GenMsgCycleTime" BO_ 541 100;

BA_ "GenMsgSendType" BO_ 1342 0;
BA_ "GenMsgCycleTime" BO_ 1342 1000;

BA_ "GenMsgSendType" BO_ 1885 0;
BA_ "GenMsgCycleTime" BO_ 1885 200;

BA_ "GenMsgSendType" BO_ 583 0;
BA_ "GenMsgCycleTime" BO_ 583 100;

BA_ "GenMsgSendType" BO_ 1001 0;
BA_ "GenMsgCycleTime" BO_ 1001 500;

BA_ "GenMsgSendType" BO_ 697 0;
BA_ "GenMsgCycleTime" BO_ 697 40;

BA_ "GenMsgSendType" BO_ 1337 0;
BA_ "GenMsgCycleTime" BO_ 1337 1000;

BA_ "GenMsgSendType" BO_ 569 0;
BA_ "GenMsgCycleTime" BO_ 569 100;

BA_ "GenMsgSendType" BO_ 777 0;
BA_ "GenMsgCycleTime" BO_ 777 30;

BA_ "GenMsgSendType" BO_ 921 0;
BA_ "GenMsgCycleTime" BO_ 921 500;

BA_ "GenMsgSendType" BO_ 905 0;
BA_ "GenMsgCycleTime" BO_ 905 500;

BA_ "GenMsgSendType" BO_ 937 0;
BA_ "GenMsgCycleTime" BO_ 937 100;

BA_ "GenMsgSendType" BO_ 986 0;
BA_ "GenMsgCycleTime" BO_ 986 100;

BA_ "GenMsgSendType" BO_ 945 0;
BA_ "GenMsgCycleTime" BO_ 945 40;

BA_ "GenMsgSendType" BO_ 890 0;
BA_ "GenMsgCycleTime" BO_ 890 40;

BA_ "GenMsgSendType" BO_ 1548 0;
BA_ "GenMsgCycleTime" BO_ 1548 5;

BA_ "GenMsgSendType" BO_ 586 0;
BA_ "GenMsgCycleTime" BO_ 586 100;

BA_ "GenMsgSendType" BO_ 810 0;
BA_ "GenMsgCycleTime" BO_ 810 1000;

BA_ "GenMsgSendType" BO_ 874 0;
BA_ "GenMsgCycleTime" BO_ 874 1000;

BA_ "GenMsgSendType" BO_ 994 0;
BA_ "GenMsgCycleTime" BO_ 994 100;

VAL_ 600 APB_watchdogState 0 "UNKNOWN" 1 "DEGRADED" 2 "CRITICAL" 3 "HEALTHY" 7 "SNA";

VAL_ 1020 APP_decisionTemperature 0 "UNKNOWN";
VAL_ 1020 APP_parkerATemperature 0 "UNKNOWN";
VAL_ 1020 APP_parkerBTemperature 0 "UNKNOWN";
VAL_ 1020 APP_parkerExtTemperature 0 "UNKNOWN";
VAL_ 1020 APP_pascalExtTemperature 0 "UNKNOWN";
VAL_ 1020 APP_pascalHeaterDecision 0 "OFF" 1 "ON";
VAL_ 1020 APP_pascalTemperature 0 "UNKNOWN";

VAL_ 1012 APP_cameraPosition 0 "INVALID" 1 "MAIN" 2 "NARROW" 3 "FISHEYE" 4 "L_PILLAR" 5 "R_PILLAR" 6 "L_REPEATER" 7 "R_REPEATER" 8 "BACKUP";
VAL_ 1012 APP_mainCamExtPitchCal 511 "SNA";
VAL_ 1012 APP_mainCamExtYawCal 511 "SNA";
VAL_ 1012 APP_mainCalibTime 127 "SNA";
VAL_ 1012 APP_mainCalibProgress 127 "SNA";
VAL_ 1012 APP_narrowCamExtPitchCal 511 "SNA";
VAL_ 1012 APP_narrowCamExtYawCal 511 "SNA";
VAL_ 1012 APP_narrowCalibTime 127 "SNA";
VAL_ 1012 APP_narrowCalibProgress 127 "SNA";
VAL_ 1012 APP_fisheyeCamExtPitchCal 511 "SNA";
VAL_ 1012 APP_fisheyeCamExtYawCal 511 "SNA";
VAL_ 1012 APP_fisheyeCalibTime 127 "SNA";
VAL_ 1012 APP_fisheyeCalibProgress 127 "SNA";
VAL_ 1012 APP_lPillarCamExtPitchCal 511 "SNA";
VAL_ 1012 APP_lPillarCamExtYawCal 511 "SNA";
VAL_ 1012 APP_lPillarCalibTime 127 "SNA";
VAL_ 1012 APP_lPillarCalibProgress 127 "SNA";
VAL_ 1012 APP_rPillarCamExtPitchCal 511 "SNA";
VAL_ 1012 APP_rPillarCamExtYawCal 511 "SNA";
VAL_ 1012 APP_rPillarCalibTime 127 "SNA";
VAL_ 1012 APP_rPillarCalibProgress 127 "SNA";
VAL_ 1012 APP_lRepeatCamExtPitchCal 511 "SNA";
VAL_ 1012 APP_lRepeatCamExtYawCal 511 "SNA";
VAL_ 1012 APP_lRepeatCalibTime 127 "SNA";
VAL_ 1012 APP_lRepeatCalibProgress 127 "SNA";
VAL_ 1012 APP_rRepeatCamExtPitchCal 511 "SNA";
VAL_ 1012 APP_rRepeatCamExtYawCal 511 "SNA";
VAL_ 1012 APP_rRepeatCalibTime 127 "SNA";
VAL_ 1012 APP_rRepeatCalibProgress 127 "SNA";
VAL_ 1012 APP_backupCamExtPitchCal 511 "SNA";
VAL_ 1012 APP_backupCamExtYawCal 511 "SNA";
VAL_ 1012 APP_backupCalibTime 127 "SNA";
VAL_ 1012 APP_backupCalibProgress 127 "SNA";

VAL_ 1018 APP_backupCameraLUX 254 "SATURATED" 255 "SNA";
VAL_ 1018 APP_fisheyeCameraLUX 254 "SATURATED" 255 "SNA";
VAL_ 1018 APP_lPillarCameraLUX 254 "SATURATED" 255 "SNA";
VAL_ 1018 APP_lRepeatCameraLUX 254 "SATURATED" 255 "SNA";
VAL_ 1018 APP_mainCameraLUX 254 "SATURATED" 255 "SNA";
VAL_ 1018 APP_narrowCameraLUX 254 "SATURATED" 255 "SNA";
VAL_ 1018 APP_rPillarCameraLUX 254 "SATURATED" 255 "SNA";
VAL_ 1018 APP_rRepeatCameraLUX 254 "SATURATED" 255 "SNA";

VAL_ 637 APS_eacAllow 0 "INHIBIT" 1 "ALLOW" 2 "RESERVED" 3 "SNA";

VAL_ 818 BMS_bmbMinMaxMultiplexer 0 "THERM_MUX0" 1 "VOLT_MUX1" 2 "END";

VAL_ 306 BMS_chgTimeToFull 4095 "BMS_chgTimeToFull_SNA";
VAL_ 306 BMS_currentUnfiltered -16384 "SNA";
VAL_ 306 BMS_packCurrent -16384 "SNA";

VAL_ 768 BMS_infoIndex 0 "DEPRECATED_0" 1 "DEPRECATED_1" 2 "DEPRECATED_2" 3 "DEPRECATED_3" 4 "DEPRECATED_4" 5 "DEPRECATED_5" 6 "DEPRECATED_6" 7 "DEPRECATED_7" 8 "DEPRECATED_8" 9 "DEPRECATED_9" 10 "BUILD_HWID_COMPONENTID" 11 "PCBAID_ASSYID_USAGEID" 13 "APP_CRC" 14 "BOOTLOADER_SVN" 15 "BOOTLOADER_CRC" 16 "SUBCOMPONENT" 17 "APP_GITHASH" 18 "BOOTLOADER_GITHASH" 19 "VERSION_DEPRECATED" 20 "UDS_PROTOCOL_BOOTCRC" 22 "VARIANTCRC" 25 "PACKAGE_PN_1_7" 26 "PACKAGE_PN_8_14" 27 "PACKAGE_PN_15_20" 29 "PACKAGE_SN_1_7" 30 "PACKAGE_SN_8_14" 31 "SUBCOMPONENT_GITHASH" 255 "END";
VAL_ 768 BMS_buildType 0 "UNKNOWN_BUILD" 1 "PLATFORM_BUILD" 2 "LOCAL_BUILD" 3 "TRACEABLE_CI_BUILD" 4 "MFG_BUILD";

VAL_ 594 BMS_powerLimitsState 0 "NOT_CALCULATED_FOR_DRIVE" 1 "CALCULATED_FOR_DRIVE";

VAL_ 754 BMS_nmKeepAwakeReason 0 "NONE_SNA" 1 "CTRS_CLOSED" 2 "CRITICAL_ALERT" 3 "FC_CTR_CLEANING" 4 "HVP_ACTIVE" 5 "BMS_ACTIVE" 6 "CP_ACTIVE";
VAL_ 754 BMS_nmWakeUpReason 0 "NONE" 1 "CAN_VEH" 2 "CAN_HVS" 3 "WANTTOCHARGE" 4 "CRITICALALERT" 5 "WANTTOWARM";

VAL_ 796 CC_currentLimit 255 "SNA";
VAL_ 796 CC_gridGrounding 0 "TN_TT" 1 "IT_SplitPhase" 2 "SNA";
VAL_ 796 CC_line1Voltage 511 "SNA";
VAL_ 796 CC_line2Voltage 511 "SNA";
VAL_ 796 CC_line3Voltage 511 "SNA";
VAL_ 796 CC_numPhases 0 "SNA";
VAL_ 796 CC_pilotState 0 "READY" 1 "IDLE" 2 "FAULTED" 3 "SNA";

VAL_ 797 CC_chgStatus2Index 0 "Mux0";
VAL_ 797 CC_buttonState 0 "RELEASED" 1 "PRESSED";

VAL_ 812 CC_logIndex 0 "Mux0" 1 "Mux1" 2 "Mux2" 3 "Mux3" 4 "Mux4" 10 "Mux10" 11 "Mux11" 12 "Mux12" 13 "Mux13";
VAL_ 812 CC_activeConnectorID 255 "SNA";
VAL_ 812 CC_temperature1 127 "SNA";
VAL_ 812 CC_temperature2 127 "SNA";
VAL_ 812 CC_temperature3 127 "SNA";
VAL_ 812 CC_contactor1Closed 0 "OPEN" 1 "CLOSED" 3 "SNA";
VAL_ 812 CC_contactor2Closed 0 "OPEN" 1 "CLOSED" 3 "SNA";
VAL_ 812 CC_temperature4 127 "SNA";
VAL_ 812 CC_conn1Current 255 "SNA";
VAL_ 812 CC_conn2Current 255 "SNA";
VAL_ 812 CC_conn3Current 255 "SNA";
VAL_ 812 CC_conn4Current 255 "SNA";

VAL_ 867 CMP_infoIndex 0 "DEPRECATED_0" 1 "DEPRECATED_1" 2 "DEPRECATED_2" 3 "DEPRECATED_3" 4 "DEPRECATED_4" 5 "DEPRECATED_5" 6 "DEPRECATED_6" 7 "DEPRECATED_7" 8 "DEPRECATED_8" 9 "DEPRECATED_9" 10 "BUILD_HWID_COMPONENTID" 11 "PCBAID_ASSYID_USAGEID" 13 "APP_CRC" 14 "BOOTLOADER_SVN" 15 "BOOTLOADER_CRC" 16 "SUBCOMPONENT" 17 "APP_GITHASH" 18 "BOOTLOADER_GITHASH" 19 "VERSION_DEPRECATED" 20 "UDS_PROTOCOL_BOOTCRC" 22 "VARIANTCRC" 25 "PACKAGE_PN_1_7" 26 "PACKAGE_PN_8_14" 27 "PACKAGE_PN_15_20" 29 "PACKAGE_SN_1_7" 30 "PACKAGE_SN_8_14" 31 "SUBCOMPONENT_GITHASH" 255 "END";
VAL_ 867 CMP_infoBuildType 0 "UNKNOWN_BUILD" 1 "PLATFORM_BUILD" 2 "LOCAL_BUILD" 3 "TRACEABLE_CI_BUILD" 4 "MFG_BUILD";
VAL_ 867 CMP_infoAssemblyId 1 "ASSEMBLY1" 255 "ASSEMBLY_SNA";

VAL_ 541 CP_acChargeState 0 "INACTIVE" 1 "ACTIVE" 2 "SHUTDOWN";
VAL_ 541 CP_cableType 0 "IEC" 1 "SAE" 2 "GB_AC" 3 "GB_DC" 4 "SNA";
VAL_ 541 CP_evseChargeType 0 "NO_CHARGER_PRESENT" 1 "DC_CHARGER_PRESENT" 2 "AC_CHARGER_PRESENT";
VAL_ 541 CP_gbState 0 "IDLE" 1 "WAIT_FOR_HANDSHAKE" 2 "HANDSHAKING" 3 "RECOGNITION" 4 "CHARGE_CONFIG" 5 "VEH_PACK_PRECHARGE" 6 "READY_TO_CHARGE" 7 "CHARGING_START" 8 "CHARGING" 9 "STOP_CHARGE" 10 "NORMAL_SHUTDOWN" 11 "END_OF_CHARGE" 12 "EVSE_READY_TO_RESTART" 13 "EVSE_ERROR" 14 "WAIT_FOR_ERROR_SHUTDOWN" 15 "RESTART_CHARGE" 16 "FAILURE";
VAL_ 541 CP_gbdcFailureReason 0 "FAILURE_NONE" 1 "ATTEMPTS_EXPIRED" 2 "SHUTDOWN_FAILURE" 3 "CRITICAL_FAILURE";
VAL_ 541 CP_gbdcStopChargeReason 0 "STOP_REASON_NONE" 1 "VEH_REQUESTED" 2 "EVSE_REQUESTED" 3 "COMMS_TIMEOUT" 4 "EVSE_FAULT" 5 "EVSE_CRITICAL_FAULT" 6 "LIVE_DISCONNECT";
VAL_ 541 CP_pilot 0 "NONE" 1 "FAULTED" 2 "LINE_CHARGE" 3 "FAST_CHARGE" 4 "IDLE" 5 "INVALID" 6 "UNUSED_6" 7 "SNA";
VAL_ 541 CP_proximity 0 "SNA" 1 "DISCONNECTED" 2 "UNLATCHED" 3 "LATCHED";
VAL_ 541 CP_teslaSwcanState 0 "INACTIVE" 1 "ACCEPT" 2 "RECEIVE" 3 "ESTABLISHED" 4 "FAULT" 5 "GO_TO_SLEEP" 6 "OFFBOARD_UPDATE_IN_PROGRESS";

VAL_ 1342 CP_infoIndex 0 "DEPRECATED_0" 1 "DEPRECATED_1" 2 "DEPRECATED_2" 3 "DEPRECATED_3" 4 "DEPRECATED_4" 5 "DEPRECATED_5" 6 "DEPRECATED_6" 7 "DEPRECATED_7" 8 "DEPRECATED_8" 9 "DEPRECATED_9" 10 "BUILD_HWID_COMPONENTID" 11 "PCBAID_ASSYID_USAGEID" 13 "APP_CRC" 14 "BOOTLOADER_SVN" 15 "BOOTLOADER_CRC" 16 "SUBCOMPONENT" 17 "APP_GITHASH" 18 "BOOTLOADER_GITHASH" 19 "VERSION_DEPRECATED" 20 "UDS_PROTOCOL_BOOTCRC" 22 "VARIANTCRC" 25 "PACKAGE_PN_1_7" 26 "PACKAGE_PN_8_14" 27 "PACKAGE_PN_15_20" 29 "PACKAGE_SN_1_7" 30 "PACKAGE_SN_8_14" 31 "SUBCOMPONENT_GITHASH" 255 "END";
VAL_ 1342 CP_buildType 0 "UNKNOWN_BUILD" 1 "PLATFORM_BUILD" 2 "LOCAL_BUILD" 3 "TRACEABLE_CI_BUILD" 4 "MFG_BUILD";

VAL_ 1885 CP_sensorDataSelect 0 "DOOR_COUNTS" 1 "PIN_TEMP" 2 "DOOR" 3 "LATCH" 4 "INDUCTIVE_DOOR" 5 "FAULT_LINE" 6 "UHF" 7 "RAILS" 8 "PROX" 9 "PILOT";
VAL_ 1885 CP_inlet1HarnessIdState 1 "INVALID" 0 "SNA" 2 "VALID";
VAL_ 1885 CP_inlet2HarnessIdState 1 "INVALID" 0 "SNA" 2 "VALID";

VAL_ 605 DAS_trafficLightColor 0 "NONE" 1 "RED" 2 "GREEN" 3 "YELLOW" ;

VAL_ 697 DAS_accState 0 "ACC_CANCEL_GENERIC" 1 "ACC_CANCEL_CAMERA_BLIND" 2 "ACC_CANCEL_RADAR_BLIND" 3 "ACC_HOLD" 4 "ACC_ON" 5 "APC_BACKWARD" 6 "APC_FORWARD" 7 "APC_COMPLETE" 8 "APC_ABORT" 9 "APC_PAUSE" 10 "APC_UNPARK_COMPLETE" 11 "APC_SELFPARK_START" 12 "ACC_CANCEL_PATH_NOT_CLEAR" 13 "ACC_CANCEL_GENERIC_SILENT" 14 "ACC_CANCEL_OUT_OF_CALIBRATION" 15 "FAULT_SNA";
VAL_ 697 DAS_accelMax 511 "SNA";
VAL_ 697 DAS_accelMin 511 "SNA";
VAL_ 697 DAS_aebEvent 0 "NOT_ACTIVE" 1 "ACTIVE" 2 "FAULT" 3 "SNA";
VAL_ 697 DAS_jerkMax 255 "SNA";
VAL_ 697 DAS_jerkMin 511 "SNA";
VAL_ 697 DAS_setSpeed 4095 "SNA";

VAL_ 1337 DAS_infoIndex 0 "DEPRECATED_0" 1 "DEPRECATED_1" 2 "DEPRECATED_2" 3 "DEPRECATED_3" 4 "DEPRECATED_4" 5 "DEPRECATED_5" 6 "DEPRECATED_6" 7 "DEPRECATED_7" 8 "DEPRECATED_8" 9 "DEPRECATED_9" 10 "BUILD_HWID_COMPONENTID" 11 "PCBAID_ASSYID_USAGEID" 13 "APP_CRC" 14 "BOOTLOADER_SVN" 15 "BOOTLOADER_CRC" 16 "EYEQ_BOOT" 17 "APP_GITHASH" 18 "BOOTLOADER_GITHASH" 19 "VERSION_DEPRECATED" 20 "UDS_PROTOCOL_BOOTCRC" 23 "EYEQ_APP" 24 "EYEQ_FFS" 255 "END";
VAL_ 1337 DAS_infoBuildType 0 "UNKNOWN_BUILD" 1 "PLATFORM_BUILD" 2 "LOCAL_BUILD" 3 "TRACEABLE_CI_BUILD" 4 "MFG_BUILD";
VAL_ 1337 DAS_infoHardwareRevision 252 "CONFIGURABLE_HWID_PLACEHOLDER";

VAL_ 569 DAS_leftFork 0 "NONE" 1 "AVAILABLE" 2 "SELECTED" 3 "UNAVAILABLE";
VAL_ 569 DAS_leftLineUsage 0 "REJECTED_UNAVAILABLE" 1 "AVAILABLE" 2 "FUSED" 3 "BLACKLISTED";
VAL_ 569 DAS_rightFork 0 "NONE" 1 "AVAILABLE" 2 "SELECTED" 3 "UNAVAILABLE";
VAL_ 569 DAS_rightLineUsage 0 "REJECTED_UNAVAILABLE" 1 "AVAILABLE" 2 "FUSED" 3 "BLACKLISTED";

VAL_ 777 DAS_objectId 0 "LEAD_VEHICLES" 1 "LEFT_VEHICLES" 2 "RIGHT_VEHICLES" 3 "CUTIN_VEHICLE" 4 "ROAD_SIGN" 5 "VEHICLE_HEADINGS";
VAL_ 777 DAS_leadVehType 0 "UNKNOWN" 1 "TRUCK" 2 "CAR" 3 "MOTORCYCLE" 4 "BICYCLE" 5 "PEDESTRIAN" 6 "IPSO";
VAL_ 777 DAS_leadVehDx 255 "SNA";
VAL_ 777 DAS_leadVehVxRel 15 "SNA";
VAL_ 777 DAS_leadVehId 127 "SNA";
VAL_ 777 DAS_leadVeh2Type 0 "UNKNOWN" 1 "TRUCK" 2 "CAR" 3 "MOTORCYCLE" 4 "BICYCLE" 5 "PEDESTRIAN";
VAL_ 777 DAS_leadVeh2Dx 255 "SNA";
VAL_ 777 DAS_leadVeh2VxRel 15 "SNA";
VAL_ 777 DAS_leadVeh2Id 0 "SNA";
VAL_ 777 DAS_leftVehType 0 "UNKNOWN" 1 "TRUCK" 2 "CAR" 3 "MOTORCYCLE" 4 "BICYCLE" 5 "PEDESTRIAN";
VAL_ 777 DAS_leftVehDx 255 "SNA";
VAL_ 777 DAS_leftVehVxRel 15 "SNA";
VAL_ 777 DAS_leftVehId 127 "SNA";
VAL_ 777 DAS_leftVeh2Type 0 "UNKNOWN" 1 "TRUCK" 2 "CAR" 3 "MOTORCYCLE" 4 "BICYCLE" 5 "PEDESTRIAN";
VAL_ 777 DAS_leftVeh2Dx 255 "SNA";
VAL_ 777 DAS_leftVeh2VxRel 15 "SNA";
VAL_ 777 DAS_leftVeh2Id 0 "SNA";
VAL_ 777 DAS_rightVehType 0 "UNKNOWN" 1 "TRUCK" 2 "CAR" 3 "MOTORCYCLE" 4 "BICYCLE" 5 "PEDESTRIAN";
VAL_ 777 DAS_rightVehDx 255 "SNA";
VAL_ 777 DAS_rightVehVxRel 15 "SNA";
VAL_ 777 DAS_rightVehId 127 "SNA";
VAL_ 777 DAS_rightVeh2Type 0 "UNKNOWN" 1 "TRUCK" 2 "CAR" 3 "MOTORCYCLE" 4 "BICYCLE" 5 "PEDESTRIAN";
VAL_ 777 DAS_rightVeh2Dx 255 "SNA";
VAL_ 777 DAS_rightVeh2VxRel 15 "SNA";
VAL_ 777 DAS_rightVeh2Id 0 "SNA";
VAL_ 777 DAS_cutinVehType 0 "UNKNOWN" 1 "TRUCK" 2 "CAR" 3 "MOTORCYCLE" 4 "BICYCLE" 5 "PEDESTRIAN";
VAL_ 777 DAS_cutinVehDx 255 "SNA";
VAL_ 777 DAS_cutinVehVxRel 15 "SNA";
VAL_ 777 DAS_cutinVehId 127 "SNA";
VAL_ 777 DAS_roadSignColor 0 "NONE" 1 "RED" 2 "YELLOW" 3 "GREEN" 4 "RED_YELLOW";
VAL_ 777 DAS_roadSignId 0 "STOP_SIGN" 1 "TRAFFIC_LIGHT" 255 "SNA";
VAL_ 777 DAS_roadSignStopLineDist 1023 "SNA";
VAL_ 777 DAS_roadSignSource 0 "NONE" 1 "NAV" 2 "VISION";
VAL_ 777 DAS_roadSignArrow 0 "CIRCLE" 1 "LEFT" 2 "RIGHT" 3 "STRAIGHT" 4 "UNKNOWN";
VAL_ 777 DAS_roadSignOrientation 0 "UNKNOWN" 1 "VERTICAL_3_LIGHT" 2 "HORIZONTAL_3_LIGHT";
VAL_ 777 DAS_leadVehHeading 255 "SNA";
VAL_ 777 DAS_leadVeh2Heading 255 "SNA";
VAL_ 777 DAS_leftVehHeading 255 "SNA";
VAL_ 777 DAS_leftVeh2Heading 255 "SNA";
VAL_ 777 DAS_rightVehHeading 255 "SNA";
VAL_ 777 DAS_rightVeh2Heading 255 "SNA";
VAL_ 777 DAS_cutinVehHeading 255 "SNA";

VAL_ 921 DAS_autoLaneChangeState 0 "UNAVAILABLE_DISABLED" 1 "UNAVAILABLE_NO_LANES" 2 "UNAVAILABLE_SONICS_INVALID" 3 "UNAVAILABLE_TP_FOLLOW" 4 "UNAVAILABLE_EXITING_HIGHWAY" 5 "UNAVAILABLE_VEHICLE_SPEED" 6 "AVAILABLE_ONLY_L" 7 "AVAILABLE_ONLY_R" 8 "AVAILABLE_BOTH" 9 "IN_PROGRESS_L" 10 "IN_PROGRESS_R" 11 "WAITING_FOR_SIDE_OBST_TO_PASS_L" 12 "WAITING_FOR_SIDE_OBST_TO_PASS_R" 13 "WAITING_FOR_FWD_OBST_TO_PASS_L" 14 "WAITING_FOR_FWD_OBST_TO_PASS_R" 15 "ABORT_SIDE_OBSTACLE_PRESENT_L" 16 "ABORT_SIDE_OBSTACLE_PRESENT_R" 17 "ABORT_POOR_VIEW_RANGE" 18 "ABORT_LC_HEALTH_BAD" 19 "ABORT_BLINKER_TURNED_OFF" 20 "ABORT_OTHER_REASON" 21 "UNAVAILABLE_SOLID_LANE_LINE" 22 "BLOCKED_VEH_TTC_L" 23 "BLOCKED_VEH_TTC_AND_USS_L" 24 "BLOCKED_VEH_TTC_R" 25 "BLOCKED_VEH_TTC_AND_USS_R" 26 "BLOCKED_LANE_TYPE_L" 27 "BLOCKED_LANE_TYPE_R" 28 "WAITING_HANDS_ON" 29 "ABORT_TIMEOUT" 30 "ABORT_MISSION_PLAN_INVALID" 31 "SNA";
VAL_ 921 DAS_autoparkReady 0 "UNAVAILABLE" 1 "READY";
VAL_ 921 DAS_autopilotHandsOnState 0 "NOT_REQD" 1 "REQD_DETECTED" 2 "REQD_NOT_DETECTED" 3 "REQD_VISUAL" 4 "REQD_CHIME_1" 5 "REQD_CHIME_2" 6 "REQD_SLOWING" 7 "REQD_STRUCK_OUT" 8 "SUSPENDED" 15 "SNA";
VAL_ 921 DAS_autopilotState 0 "DISABLED" 1 "UNAVAILABLE" 2 "AVAILABLE" 3 "ACTIVE_NOMINAL" 4 "ACTIVE_RESTRICTED" 5 "ACTIVE_NAV" 8 "ABORTING" 9 "ABORTED" 14 "FAULT" 15 "SNA";
VAL_ 921 DAS_blindSpotRearLeft 0 "NO_WARNING" 1 "WARNING_LEVEL_1" 2 "WARNING_LEVEL_2" 3 "SNA";
VAL_ 921 DAS_blindSpotRearRight 0 "NO_WARNING" 1 "WARNING_LEVEL_1" 2 "WARNING_LEVEL_2" 3 "SNA";
VAL_ 921 DAS_csaState 0 "UNAVAILABLE" 1 "AVAILABLE" 2 "ENABLE" 3 "HOLD";
VAL_ 921 DAS_fleetSpeedState 0 "UNAVAILABLE" 1 "AVAILABLE" 2 "ACTIVE" 3 "HOLD";
VAL_ 921 DAS_forwardCollisionWarning 0 "NONE" 1 "FORWARD_COLLISION_WARNING" 3 "SNA";
VAL_ 921 DAS_fusedSpeedLimit 0 "UNKNOWN_SNA" 31 "NONE";
VAL_ 921 DAS_heaterState 0 "OFF_SNA" 1 "ON";
VAL_ 921 DAS_laneDepartureWarning 0 "NONE" 1 "LEFT_WARNING" 2 "RIGHT_WARNING" 3 "LEFT_WARNING_SEVERE" 4 "RIGHT_WARNING_SEVERE" 5 "SNA";
VAL_ 921 DAS_sideCollisionAvoid 0 "NONE" 1 "AVOID_LEFT" 2 "AVOID_RIGHT" 3 "SNA";
VAL_ 921 DAS_sideCollisionInhibit 0 "NO_INHIBIT" 1 "INHIBIT";
VAL_ 921 DAS_sideCollisionWarning 0 "NONE" 1 "WARN_LEFT" 2 "WARN_RIGHT" 3 "WARN_LEFT_RIGHT";
VAL_ 921 DAS_suppressSpeedWarning 0 "Do_Not_Suppress" 1 "Suppress_Speed_Warning";
VAL_ 921 DAS_visionOnlySpeedLimit 0 "UNKNOWN_SNA" 31 "NONE";

VAL_ 905 DAS_ACC_report 0 "TARGET_NONE" 1 "TARGET_CIPV" 2 "TARGET_IN_FRONT_OF_CIPV" 3 "TARGET_MCVL" 4 "TARGET_MCVR" 5 "TARGET_CUTIN" 6 "TARGET_TYPE_STOP_SIGN" 7 "TARGET_TYPE_TRAFFIC_LIGHT" 8 "TARGET_TYPE_IPSO" 9 "TARGET_TYPE_FAULT" 10 "CSA" 11 "LC_HANDS_ON_REQD_STRUCK_OUT" 12 "LC_EXTERNAL_STATE_ABORTING" 13 "LC_EXTERNAL_STATE_ABORTED" 14 "LC_EXTERNAL_STATE_ACTIVE_RESTRICTED" 15 "RADAR_OBJ_ONE" 16 "RADAR_OBJ_TWO" 17 "TARGET_MCP" 18 "FLEET_SPEEDS" 19 "MCVLR_DPP" 20 "MCVLR_IN_PATH" 21 "CIPV_CUTTING_OUT" 22 "RADAR_OBJ_FIVE" 23 "CAMERA_ONLY" 24 "BEHAVIOR_REPORT";
VAL_ 905 DAS_accSpeedLimit 0 "NONE" 1023 "SNA";
VAL_ 905 DAS_activationFailureStatus 0 "IDLE" 1 "FAILED_1" 2 "FAILED_2";
VAL_ 905 DAS_driverInteractionLevel 0 "DRIVER_INTERACTING" 1 "DRIVER_NOT_INTERACTING" 2 "CONTINUED_DRIVER_NOT_INTERACTING";
VAL_ 905 DAS_longCollisionWarning 0 "NONE" 1 "VEHICLE_UNKNOWN" 2 "PEDESTRIAN" 3 "IPSO" 4 "STOPSIGN_STOPLINE" 5 "TFL_STOPLINE" 6 "VEHICLE_CIPV" 7 "VEHICLE_CUTIN" 8 "VEHICLE_MCVL" 9 "VEHICLE_MCVL2" 10 "VEHICLE_MCVR" 11 "VEHICLE_MCVR2" 12 "VEHICLE_CIPV2" 15 "SNA";
VAL_ 905 DAS_lssState 0 "FAULT" 1 "LDW" 2 "LKA" 3 "ELK" 4 "MONITOR" 5 "BLINDSPOT" 6 "ABORT" 7 "OFF";
VAL_ 905 DAS_pmmCameraFaultReason 0 "NO_FAULT" 1 "BLOCKED_FRONT" 2 "INVALID_MIA";
VAL_ 905 DAS_pmmLoggingRequest 0 "FALSE" 1 "TRUE";
VAL_ 905 DAS_pmmObstacleSeverity 0 "NONE" 1 "IMMINENT_REAR" 2 "IMMINENT_FRONT" 3 "BRAKE_REQUEST" 4 "CRASH_REAR" 5 "CRASH_FRONT" 6 "ACCEL_LIMIT" 7 "SNA";
VAL_ 905 DAS_pmmRadarFaultReason 0 "NO_FAULT" 1 "BLOCKED_FRONT" 2 "INVALID_MIA";
VAL_ 905 DAS_pmmSysFaultReason 0 "NONE" 1 "DAS_DISABLED" 2 "SPEED" 3 "DI_FAULT" 4 "STEERING_ANGLE_RATE" 5 "DISABLED_BY_USER" 6 "ROAD_TYPE" 7 "BRAKE_PEDAL_INHIBIT";
VAL_ 905 DAS_pmmUltrasonicsFaultReason 0 "NO_FAULT" 1 "BLOCKED_FRONT" 2 "BLOCKED_REAR" 3 "BLOCKED_BOTH" 4 "INVALID_MIA";
VAL_ 905 DAS_ppOffsetDesiredRamp 128 "PP_NO_OFFSET";
VAL_ 905 DAS_radarTelemetry 0 "IDLE" 1 "NORMAL" 2 "URGENT";
VAL_ 905 DAS_robState 0 "INHIBITED" 1 "MEASURE" 2 "ACTIVE" 3 "MAPLESS";

VAL_ 937 DAS_telemetryMultiplexer 0 "ROAD_INFORMATION" 1 "ACC_DRIVER_MONITOR" 2 "TRAFFIC_SIGNS" 7 "CSA_EVENT" 8 "STATIONARY_OBST" 9 "CRUISE_STALK_INPUT";
VAL_ 937 DAS_telLeftLaneType 0 "UNDECIDED" 1 "SOLID" 2 "ROAD_EDGE" 3 "DASHED" 4 "DOUBLE" 5 "BOTTS_DOTS" 6 "BARRIER";
VAL_ 937 DAS_telRightLaneType 0 "UNDECIDED" 1 "SOLID" 2 "ROAD_EDGE" 3 "DASHED" 4 "DOUBLE" 5 "BOTTS_DOTS" 6 "BARRIER";
VAL_ 937 DAS_telLeftMarkerQuality 0 "LOWEST" 1 "LOW" 2 "MEDIUM" 3 "HIGH";
VAL_ 937 DAS_telRightMarkerQuality 0 "LOWEST" 1 "LOW" 2 "MEDIUM" 3 "HIGH";
VAL_ 937 DAS_telLeftMarkerColor 0 "UNKNOWN" 1 "WHITE" 2 "YELLOW" 3 "BLUE";
VAL_ 937 DAS_telRightMarkerColor 0 "UNKNOWN" 1 "WHITE" 2 "YELLOW" 3 "BLUE";
VAL_ 937 DAS_telLeftLaneCrossing 0 "NOT_CROSSING" 1 "CROSSING";
VAL_ 937 DAS_telRightLaneCrossing 0 "NOT_CROSSING" 1 "CROSSING";
VAL_ 937 DAS_soCamCipvStatus 0 "INVALID" 1 "UNFUSED" 2 "FUSED_W_OTHER_RAD_OBJ" 3 "FUSED_W_RAD5";
VAL_ 937 DAS_soRad5Status 0 "INVALID" 1 "UNFUSED" 2 "FUSED_W_CIPV" 3 "FUSED_W_OTHER_CAMOBJ";
VAL_ 937 DAS_soRad1Status 0 "INVALID" 1 "UNFUSED" 2 "FUSED_W_CIPV" 3 "FUSED_W_OTHER_CAMOBJ";

VAL_ 945 DAS_TF_multiplexer 0 "Mux0" 1 "Mux1" 2 "Mux2";

VAL_ 1548 DAS_TR_ObjIndex 0 "Mux0" 1 "Mux1" 2 "Mux2" 3 "Mux3" 4 "Mux4" 5 "Mux5" 6 "Mux6" 7 "Mux7" 8 "Mux8" 9 "Mux9" 10 "Mux10" 11 "Mux11" 12 "Mux12" 13 "Mux13" 14 "Mux14" 15 "Mux15" 16 "Mux16" 17 "Mux17" 18 "Mux18" 19 "Mux19" 20 "Mux20" 21 "Mux21" 22 "Mux22" 23 "Mux23" 24 "Mux24" 25 "Mux25" 26 "Mux26" 27 "Mux27" 28 "Mux28" 29 "Mux29" 30 "Mux30" 31 "Mux31";
VAL_ 1548 DAS_TR_Obj00_Class 0 "UNKNOWN" 1 "MOVING_FOUR_WHEEL_VEHICLE" 2 "MOVING_TWO_WHEEL_VEHICLE" 3 "MOVING_PEDESTRIAN" 4 "CONSTRUCTION_ELEMENT";
VAL_ 1548 DAS_TR_Obj00_MovingState 0 "INDETERMINATE" 1 "MOVING" 2 "STOPPED" 3 "STANDING";

VAL_ 586 DAS_accSmartSpeedState 0 "NOT_ACTIVE" 1 "ACTIVE_OFFRAMP" 2 "ACTIVE_INTEGRATING" 3 "ACTIVE_ONRAMP" 4 "SET_SPEED_SET_REQUESTED" 5 "OFFRAMP_DELAY" 7 "SNA";
VAL_ 586 DAS_autosteerBottsDotsUsage 0 "REJECTED_UNAVAILABLE" 1 "AVAILABLE" 2 "FUSED" 3 "BLACKLISTED";
VAL_ 586 DAS_autosteerHPPUsage 0 "REJECTED_UNAVAILABLE" 1 "AVAILABLE" 2 "FUSED" 3 "BLACKLISTED";
VAL_ 586 DAS_autosteerHealthState 0 "UNAVAILABLE" 1 "NOMINAL" 2 "DEGRADED" 3 "SEVERELY_DEGRADED" 4 "ABORTING" 5 "FAULT";
VAL_ 586 DAS_autosteerModelUsage 0 "REJECTED_UNAVAILABLE" 1 "AVAILABLE" 2 "FUSED" 3 "BLACKLISTED";
VAL_ 586 DAS_autosteerNavigationUsage 0 "REJECTED_UNAVAILABLE" 1 "AVAILABLE" 2 "FUSED" 3 "BLACKLISTED";
VAL_ 586 DAS_autosteerVehiclesUsage 0 "REJECTED_UNAVAILABLE" 1 "AVAILABLE" 2 "FUSED" 3 "BLACKLISTED";
VAL_ 586 DAS_behaviorType 0 "INVALID" 1 "IN_LANE" 2 "LANE_CHANGE_LEFT" 3 "LANE_CHANGE_RIGHT";
VAL_ 586 DAS_lastAutosteerAbortReason 0 "HM_LANE_VIEW_RANGE" 1 "HM_VIRTUAL_LANE_NO_INPUTS" 2 "HM_STEERING_ERROR" 14 "APP_ME_STATE_NOT_VISION" 15 "ME_MAIN_STATE_NOT_VISION" 16 "CAM_MSG_MIA" 17 "CAM_WATCHDOG" 18 "TRAILER_MODE" 19 "SIDE_COLLISION_IMMINENT" 20 "EPAS_EAC_DENIED" 21 "COMPONENT_MIA" 22 "CRUISE_FAULT" 23 "CID_SWITCH_DISABLED" 24 "DRIVING_OFF_NAV" 25 "VEHICLE_SPEED_ABOVE_MAX" 26 "FOLLOWER_OUTPUT_INVALID" 27 "PLANNER_OUTPUT_INVALID" 28 "EPAS_ERROR_CODE" 29 "ACC_CANCEL" 30 "CAMERA_FAILSAFES" 31 "NO_ABORT" 32 "AEB";
VAL_ 586 DAS_lastLinePreferenceReason 0 "OTHER_LANE_DISAGREES_WITH_MODEL" 1 "AGREEMENT_WITH_NEIGHBOR_LANES" 2 "NEIGHBOR_LANE_PROBABILIY" 3 "NAVIGATION_BRANCH" 4 "AVOID_ONCOMING_LANES" 5 "COUNTRY_DRIVING_SIDE" 15 "NONE";
VAL_ 586 DAS_navAvailable 0 "UNAVAILABLE" 1 "AVAILABLE";
VAL_ 586 DAS_offsetSide 0 "NO_OFFSET" 1 "OFFSET_RIGHT_OBJECT" 2 "OFFSET_LEFT_OBJECT" 3 "OFFSET_BOTH_OBJECTS";
VAL_ 586 DAS_plannerState 0 "DISABLED" 1 "VL" 2 "FOLLOW" 3 "LANECHANGE_REQUESTED" 4 "LANECHANGE_IN_PROGRESS" 5 "LANECHANGE_WAIT_FOR_SIDE_OBSTACLE" 6 "LANECHANGE_WAIT_FOR_FWD_OBSTACLE" 7 "LANECHANGE_ABORT";
VAL_ 586 DAS_roadSurfaceType 0 "SNA" 1 "NORMAL" 2 "ENHANCED";
VAL_ 586 DAS_ulcInProgress 0 "INACTIVE" 1 "ACTIVE";
VAL_ 586 DAS_ulcType 0 "NAV" 1 "SPEED";

VAL_ 615 DI_massConfidence 1 "MASS_CONFIDED" 0 "MASS_NOT_CONFIDED" ;
VAL_ 615 DI_relativeTireTreadDepth -32 "SNA" ;
VAL_ 615 DI_tireFitment 3 "FITMENT_SNA" 0 "FITMENT_SQUARE" 1 "FITMENT_STAGGERED" ;
VAL_ 615 DI_trailerDetected 1 "TRAILER_DETECTED" 0 "TRAILER_NOT_DETECTED" ;

VAL_ 850 BMS_energyBuffer 255 "SNA" ;
VAL_ 850 BMS_energyToChargeComplete 2047 "SNA" ;
VAL_ 850 BMS_expectedEnergyRemaining 2047 "SNA" ;
VAL_ 850 BMS_idealEnergyRemaining 2047 "SNA" ;
VAL_ 850 BMS_nominalEnergyRemaining 2047 "SNA" ;
VAL_ 850 BMS_nominalFullPackEnergy 2047 "SNA" ;

VAL_ 317 CP_chargeShutdownRequest 2 "EMERGENCY_SHUTDOWN_REQUESTED" 1 "GRACEFUL_SHUTDOWN_REQUESTED" 0 "NO_SHUTDOWN_REQUESTED" ;
VAL_ 317 CP_evseChargeType 2 "AC_CHARGER_PRESENT" 1 "DC_CHARGER_PRESENT" 0 "NO_CHARGER_PRESENT" ;
VAL_ 317 CP_hvChargeStatus 1 "CP_CHARGE_CONNECTED" 5 "CP_CHARGE_ENABLED" 6 "CP_CHARGE_FAULTED" 0 "CP_CHARGE_INACTIVE" 2 "CP_CHARGE_STANDBY" 4 "CP_EVSE_TEST_PASSED" 3 "CP_EXT_EVSE_TEST_ACTIVE" ;

CM_ "Reference DBC for the legacy Model 3/Y, not loaded by the apps (they load the smaller vehicles/tesla/bus_1_tesla_vehicle.dbc, which this file extends with the messages of more than 64 signals and the ones the test car never sent). Both DashKit buses. Messages DashPilot reads are unchanged, except DI_speed (full layout). The others were checked against full-bus recordings of a 2023 Model Y RWD (78 min, 2026-11-20): where the ESP32-DualCAN project's definition (Model3_CH.dbc / Model3_VEH.dbc, github.com/dzid26, CERN-OHL-W v2; see each message comment) decodes more of the car's frames with no unexplained bit, it replaces the earlier one, and messages the file lacked were added below this line. An id that is a different message on each bus has the definition that fits more frames. A name the car uses for two ids has the id as a suffix on the second. UNK_ messages: seen on the car, no public definition. Messages whose comment says they were not seen were never sent by the test car (other drive units, charging, options): they are included unchecked, for other legacy Model 3/Y.";
CM_ BO_ 322 "ESP32-DualCAN Model3_VEH. Seen on this car: 8-byte frames; fit good (bits covered 100%, mux 100%, ranges 100%). read by the app or firmware.";
VAL_ 322 VCLEFT_liftgateLatchRequest 0 "NONE" 1 "CINCH" 2 "RELEASE_V2" 3 "FORCE_RELEASE" 4 "RESET" ;
VAL_ 322 VCLEFT_liftgateRequestSource 0 "NONE" 1 "MCU_SWITCH" 2 "EXTERIOR" 3 "SHUTFACE" 4 "KEY_TRUNK_BUTTON" 5 "VCSEC_COMMAND" 6 "PARTY" 7 "UDS" ;
VAL_ 322 VCLEFT_liftgatePhysicalChimeRequ 0 "NONE" 1 "ONE_SHORT" 2 "TWO_SHORT" 3 "THREE_SHORT" 4 "ONE_LONG" ;
VAL_ 322 VCLEFT_liftgateUIChimeRequest 0 "NONE" 1 "ONE_SHORT" 2 "TWO_SHORT" 3 "THREE_SHORT" 4 "ONE_LONG" ;
VAL_ 322 VCLEFT_liftgateMvmntNotAllowedCo 0 "NONE" 1 "LOW_12V" 2 "VEHICLE_AT_SPEED" 3 "UNCALIBRATED" 4 "EXTERIOR_PRESS_AT_MAX_OPEN" 5 "LOCKED" ;
VAL_ 322 VCLEFT_liftgateStoppingCondition 0 "NONE" 1 "PINCH" 2 "OBSTACLE_STALL" 3 "LOW_12V" 4 "STATE_TIMEOUT" 5 "VEHICLE_AT_SPEED" 6 "OBSTACLE_CURRENT" 7 "OBSTACLE_TRAJ_POS" 8 "OBSTACLE_TRAJ_VEL" 9 "UNCALIBRATED" 10 "LATCH_FAULT" 11 "OBSTACLE_CURRENT_SPIKE" 12 "COUNT" ;
VAL_ 322 VCLEFT_liftgateState 0 "INIT" 1 "OFF" 2 "BACKOFF" 3 "OPENING" 4 "CLOSING" 5 "CLOSED" 6 "LATCH_OPENING" 7 "LATCH_CLOSING" 8 "NOT_INSTALLED" 9 "UNKNOWN" 10 "LATCH_EXIT" 11 "END_OF_TRAVEL" 12 "LATCH_ENTRY" 13 "PARTY_DANCE" ;
VAL_ 322 VCLEFT_liftgateStatusIndex 0 "0" 1 "1" 2 "INVALID" ;
CM_ BO_ 470 "ESP32-DualCAN Model3_VEH. Seen on this car: 8-byte frames; fit good (bits covered 100%, mux 100%, ranges 100%).";
VAL_ 470 DIR_currentLimit 8191 "SNA" ;
CM_ BO_ 513 "ESP32-DualCAN Model3_VEH. Seen on this car: 8-byte frames; fit good (bits covered 100%, mux 100%, ranges 100%).";
VAL_ 513 VCFRONT_ccrExvState 0 "UNINIT" 1 "INIT_OPEN" 2 "INIT_CLOSE" 3 "READY" 4 "FAULTED" 5 "WAIT" 6 "OVERDRIVING_SHUT" 7 "READY_SHUT" 8 "CALIB_CLOSE" 9 "CALIB_CLOSE_OVERDRIVE" ;
VAL_ 513 VCFRONT_recircExvState 0 "UNINIT" 1 "INIT_OPEN" 2 "INIT_CLOSE" 3 "READY" 4 "FAULTED" 5 "WAIT" 6 "OVERDRIVING_SHUT" 7 "READY_SHUT" 8 "CALIB_CLOSE" 9 "CALIB_CLOSE_OVERDRIVE" ;
VAL_ 513 VCFRONT_cclExvState 0 "UNINIT" 1 "INIT_OPEN" 2 "INIT_CLOSE" 3 "READY" 4 "FAULTED" 5 "WAIT" 6 "OVERDRIVING_SHUT" 7 "READY_SHUT" 8 "CALIB_CLOSE" 9 "CALIB_CLOSE_OVERDRIVE" ;
VAL_ 513 VCFRONT_evapExvState 0 "UNINIT" 1 "INIT_OPEN" 2 "INIT_CLOSE" 3 "READY" 4 "FAULTED" 5 "WAIT" 6 "OVERDRIVING_SHUT" 7 "READY_SHUT" 8 "CALIB_CLOSE" 9 "CALIB_CLOSE_OVERDRIVE" ;
VAL_ 513 VCFRONT_chillerExvState 0 "UNINIT" 1 "INIT_OPEN" 2 "INIT_CLOSE" 3 "READY" 4 "FAULTED" 5 "WAIT" 6 "OVERDRIVING_SHUT" 7 "READY_SHUT" 8 "CALIB_CLOSE" 9 "CALIB_CLOSE_OVERDRIVE" ;
VAL_ 513 VCFRONT_hpReqCoolantMode 0 "ANY" 1 "SERIES_NO_BYPASS" 2 "SERIES_BYPASS" 3 "PARALLEL" 4 "AMBIENT_SOURCE" ;
VAL_ 513 VCFRONT_lccExvState 0 "UNINIT" 1 "INIT_OPEN" 2 "INIT_CLOSE" 3 "READY" 4 "FAULTED" 5 "WAIT" 6 "OVERDRIVING_SHUT" 7 "READY_SHUT" 8 "CALIB_CLOSE" 9 "CALIB_CLOSE_OVERDRIVE" ;
VAL_ 513 VCFRONT_hpBatteryLoadType 0 "NONE" 1 "BATT_HEAT" 2 "BATT_COOL" ;
VAL_ 513 VCFRONT_hpCabinLoadType 0 "NONE" 1 "CC" 2 "REHEAT" 3 "EVAP" ;
VAL_ 513 VCFRONT_pressureRefrigLiquid 511 "SNA" ;
VAL_ 513 VCFRONT_hpBlendType 0 "NONE" 1 "PARTIAL" 2 "FULL" ;
VAL_ 513 VCFRONT_hpDominantLoad 0 "NONE" 1 "EVAP" 2 "CHILLER" 3 "LOW_BOTH" 4 "LCC" 5 "CC" 6 "HIGH_BOTH" ;
VAL_ 513 VCFRONT_hpLowSideHX 0 "NONE" 1 "CHILLER" 2 "EVAP" 3 "BOTH" ;
VAL_ 513 VCFRONT_hpHighSideHX 0 "NONE" 1 "LCC" 2 "CC" 3 "BOTH" ;
VAL_ 513 VCFRONT_compFaultSeverity 0 "NONE" 1 "LOW" 2 "MEDIUM" 3 "HIGH" ;
VAL_ 513 VCFRONT_coolantValveMode 0 "SERIES" 1 "PARALLEL" 2 "BLEND" 3 "AMBIENT_SOURCE" ;
VAL_ 513 VCFRONT_radiatorFanRPMActual 1023 "SNA" ;
VAL_ 513 VCFRONT_solenoidEvapState 0 "UNDEFINED" 1 "OPENED" 2 "CLOSED" 3 "FAULTED" ;
VAL_ 513 VCFRONT_exvState 0 "UNINIT" 1 "INIT_OPEN" 2 "INIT_CLOSE" 3 "READY" 4 "FAULTED" 5 "WAIT" 6 "OVERDRIVING_SHUT" 7 "READY_SHUT" 8 "CALIB_CLOSE" 9 "CALIB_CLOSE_OVERDRIVE" ;
VAL_ 513 VCFRONT_pumpPowertrainRPMActual 1023 "SNA" ;
VAL_ 513 VCFRONT_compressorState 0 "STANDBY" 1 "READY" 2 "RUNNING" 3 "FAULT" ;
VAL_ 513 VCFRONT_pumpBatteryRPMActual 1023 "SNA" ;
VAL_ 513 VCFRONT_loggingAndVitals10HzIndex 0 "TARGETS_AND_ACTUALS_0" 1 "TARGETS_SENSORS_AND_ACTUALS_1" 2 "STATES_AND_SENSORS" 3 "EXV_FLOW" 4 "HP_AND_EXV_STATE" 5 "EXV_FLOW_TARGET" 6 "END" ;
CM_ BO_ 530 "ESP32-DualCAN Model3_VEH (dzid26, CERN-OHL-W): replaces overlapping signals; checked on 78 min of drive data (2026-11-20).";
VAL_ 530 BMS_hvState 0 "DOWN" 1 "COMING_UP" 2 "GOING_DOWN" 3 "UP_FOR_DRIVE" 4 "UP_FOR_CHARGE" 5 "UP_FOR_DC_CHARGE" 6 "UP" ;
VAL_ 530 BMS_smStateRequest 0 "STANDBY" 1 "DRIVE" 2 "SUPPORT" 3 "CHARGE" 4 "FEIM" 5 "CLEAR_FAULT" 6 "FAULT" 7 "WELD" 8 "TEST" 9 "SNA" 10 "DIAG" ;
VAL_ 530 BMS_chgPowerAvailable 2047 "SNA" ;
VAL_ 530 BMS_diLimpRequest 0 "NONE" 1 "WELDED" ;
VAL_ 530 BMS_state 0 "STANDBY" 1 "DRIVE" 2 "SUPPORT" 3 "CHARGE" 4 "FEIM" 5 "CLEAR_FAULT" 6 "FAULT" 7 "WELD" 8 "TEST" 9 "SNA" 10 "DIAG" ;
VAL_ 530 BMS_contactorState 0 "SNA" 1 "OPEN" 2 "OPENING" 3 "CLOSING" 4 "CLOSED" 5 "WELDED" 6 "BLOCKED" ;
CM_ BO_ 583 "ESP32-DualCAN Model3_CH. Seen on this car: 8-byte frames; fit good (bits covered 100%, mux 100%, ranges 100%).";
VAL_ 583 DAS_lastWatchdogCode 0 "NO_TASK_FAILED" 30 "UNKNOWN_TASK_FAILED" 39 "TELEMETRY_PACKAGER_FAILED" 40 "TELEMETRY_FAILED" 41 "SNAPSHOT_FAILED" 42 "VISION_FAILED" 43 "LEGACY_FAILED" 44 "WATCHDOG_FAILED" 45 "CAN_RX_FAILED" 46 "CAN_TX_FAILED" 47 "TEMPERATURE_MONITOR_FAILED" 48 "INERTIATOR_FAILED" 49 "GPS_FAILED" 50 "ARBITER_FAILED" 51 "AP_STATE_MACHINE_FAILED" 52 "CONTROLLER_FAILED" 53 "LOCALIZER_FAILED" 54 "MISSION_PLANNER_FAILED" 55 "PERCEPTION_FAILED" 56 "ROAD_ESTIMATOR_FAILED" 57 "ATLAS_FAILED" 58 "STAY_IN_LANE_BEHAVIOR_FAILED" 59 "SNAPSHOT_TRIGGER_CLIENT_FAILED" 60 "RAIN_LIGHT_SENSING_FAILED" 61 "IMU_FAILED" 62 "UBX_LOG_FAILED" 63 "LANE_CHANGE_BEHAVIOR_FAILED" 65 "DRIVER_MONITOR_FAILED" 66 "MAP_MANAGER_FAILED" 67 "CAMERA_FAILED" 68 "ACTIVE_SAFETY_FAILED" 69 "UI_SERVER_FAILED" 70 "DYNAMICS_FAILED" 71 "FIELD_CALIBRATION_FAILED" 72 "PARKING_BEHAVIOR_FAILED" 73 "HW_MONITOR_FAILED" 74 "CLIP_LOGGER_FAILED" 75 "DRIVABLE_SPACE_TRACKER_FAILED" 76 "SCHEDULER_FAILED" 77 "BRIDGE_FAILED" 78 "CITY_STREETS_BEHAVIOR_FAILED" 79 "BEV_GRAPH_FAILED" 80 "ULTRASONICS_FAILED" 81 "RADAR_FAILED" 82 "SYNC_PIPELINE_FAILED" 83 "X1_CLIENT_FAILED" 84 "FLEET_CONFIG_FAILED" 85 "GEO_REGION_FAILED" 86 "TELEMETRY_COMPLIANCE_FAILED" ;
VAL_ 583 DAS_laneChangeState 0 "UNAVAILABLE_DISABLED" 1 "UNAVAILABLE_ROAD_NOT_APPROPRIATE" 2 "UNAVAILABLE_SPEED" 3 "UNAVAILABLE_NO_LANES" 4 "UNAVAILABLE_INACTIVE" 5 "UNAVAILABLE_FORK_MODE" 6 "UNAVAILABLE_ULTRASONICS_NOT_READY" 7 "UNAVAILABLE_INVALID_MODE" 8 "AVAILABLE_LEFT_ONLY" 9 "AVAILABLE_RIGHT_ONLY" 10 "AVAILABLE_BOTH" 11 "ABORTING_INACTIVE" 12 "ABORTING_BLINKER" 13 "ABORTING_TIMEOUT" 14 "ABORTING_BLIND_SPOT_OCCUPIED" 15 "ABORTING_INVALID_MODE" 16 "ABORTING_LINE_TYPE" 17 "ABORTING_FORK_AVAILABLE" 18 "ABORTING_LOST_VISION_POSE" 19 "ABORTING_ACC_AUTOSTEER_ACTIVATED" 20 "ABORTING_ULC_BLINKER_TIMEOUT" 21 "ABORTING_INVALID_BEHAVIOR" 22 "ABORTING_BELOW_MIN_SPEED" 23 "ABORTING_BEHAVIOR_CHANGED" 24 "ABORTING_HIGH_ALC_PROGRESS_ERROR" 25 "ABORTING_ULC_CONFIRMATION_TIMEOUT" 26 "ABORTING_ALC_REQUEST_BEFORE_ULC_CONFIRM" 27 "IN_PROGRESS_LEFT" 28 "IN_PROGRESS_RIGHT" 29 "BLOCKED_LEFT" 30 "BLOCKED_RIGHT" 31 "ABORTING_GORE_POINT" 32 "ABORTING_CONSTRUCTION_DETECTED" 33 "ABORTING_TOLL_BOOTH_DETECTED" 34 "ABORTING_TIGHT_TURN_RADIUS" 35 "ABORTING_WEATHER" 36 "UNAVAILABLE_BLINDSPOT_RESTRICTED" 37 "ABORTING_NO_HANDS_ON" 38 "UNAVAILABLE_NO_REAR_OBJECT" 39 "ABORTING_SOURCE_AND_TARGET_LANES_MERGED" 40 "ABORTING_SNOOZED" 41 "UNAVAILABLE_BLINKER_LATCHED" 42 "UNAVAILABLE_AUTOPILOT_ABORTING" 43 "ABORTING_DESTINATION_LANE_UNSTABLE" 63 "UNKNOWN" ;
VAL_ 583 DAS_forkState 0 "INVALID" 1 "UNAVAILABLE_DISABLED" 2 "UNAVAILABLE_AP_INACTIVE" 3 "UNAVAILABLE_CONSTRUCTION" 4 "UNAVAILABLE_CONTROLLED_ACCESS_TOO_FAR" 5 "UNAVAILABLE_DON_INACTIVE" 6 "UNAVAILABLE_TOLL_BOOTH" 7 "UNAVAILABLE_OTHER" 8 "IDLE_BOTH_FORKS_AVAILABLE" 9 "IDLE_LEFT_FORK_AVAILABLE" 10 "IDLE_RIGHT_FORK_AVAILABLE" 11 "IDLE_NO_FORKS_AVAILABLE" 12 "ACTIVE_LEFT_NAV" 13 "ACTIVE_LEFT_USER" 14 "ACTIVE_RIGHT_NAV" 15 "ACTIVE_RIGHT_USER" 16 "FORK_COMPLETE" 17 "ABORT_CONTROL_INACTIVE" 18 "ABORT_BLINKER_CHANGE" 19 "ABORT_NOT_LEFT_LANE" 20 "ABORT_NOT_RIGHT_LANE" 21 "ABORT_DISALLOW" 22 "ABORT_OTHER" 23 "UNAVAILABLE_TIGHT_TURN_RADIUS" 24 "UNAVAILABLE_WEATHER" 25 "PRE_ACTIVE_LEFT_NAV" 26 "PRE_ACTIVE_RIGHT_NAV" 27 "UNAVAILABLE_INTERSECTION_ACTIVE" ;
VAL_ 583 DAS_rqstedBehaviorStatus 0 "VALID" 1 "NO_SRC_POLYLANE" 2 "NO_DEST_POLYLANE" 3 "MAP_NOT_INITIALIZED" 4 "NO_SOURCE_LANE_ON_MAP" 5 "NO_TARGET_LANE_ON_MAP" 6 "BUILD_ARGUMENT_FAIL" 7 "BLOCKED_BY_ULTRASOUND_L" 8 "BLOCKED_BY_BLINDSPOT_CAMERA_L" 9 "BLOCKED_BY_BLINDSPOT_CAMERA_INVALID_L" 10 "BLOCKED_BY_ULTRASOUND_AND_CAMERA_L" 11 "BLOCKED_BY_LANE_TYPE_L" 12 "BLOCKED_BY_ULTRASOUND_R" 13 "BLOCKED_BY_BLINDSPOT_CAMERA_R" 14 "BLOCKED_BY_BLINDSPOT_CAMERA_INVALID_R" 15 "BLOCKED_BY_ULTRASOUND_AND_CAMERA_R" 16 "BLOCKED_BY_LANE_TYPE_R" 17 "ROAD_NOT_APPROPRIATE" 18 "OUT_OF_DATE" 19 "BAD_ORIGIN_UPDATE" 20 "BLOCKED_BY_SLOW_TARGET_L" 21 "BLOCKED_BY_SLOW_TARGET_R" 22 "INVALID_PLAN" ;
VAL_ 583 DAS_autopilotAbortReason 0 "NONE" 1 "WATCHDOG_HEALTH" 2 "DI_MIA" 3 "ESP_MIA" 4 "EPAS_MIA" 5 "GTW_MIA" 6 "SCCM_MIA" 7 "RADAR_MIA" 8 "VCFRONT_MIA" 9 "VCRIGHT_MIA" 10 "CRUISE_FAULT" 11 "CRUISE_NOT_ACTIVE" 12 "USER_DISABLED" 13 "TRAILER_MODE_ACTIVE" 14 "VEHICLE_SPEED_ABOVE_MAX" 15 "EPAS_EAC_NOT_ACTIVE" 16 "EPAS_EAC_ERROR" 17 "CAMERA_FAILSAFES" 18 "CAMERA_CALIBRATION" 19 "RADAR_BLIND" 20 "RADAR_FAULT" 21 "ACC_CANCEL_GENERIC" 22 "ACC_CANCEL_SILENT" 23 "ACC_FAULT" 24 "ROAD_ESTIMATOR_HEALTH" 25 "CONTROLLER_REFERENCE" 26 "CONTROLLER_SOLVER" 27 "CONTROLLER_NOT_ALLOWED" 28 "THERMAL_ISSUE" 29 "MAP_HEALTH" 30 "CONTROLLER_STALE_REFERENCE" 31 "CONTROLLER_STALE_LOCALIZATION" 32 "CONTROLLER_BAD_REF_UPDATE" 33 "AEB" 34 "CONTROLLER_REF_TOO_SHORT" 35 "MISSION_PLANNER_NO_VISION_LANES_FOUND" 36 "GORE_INCURSION" 37 "REACHED_END_OF_NAV_STOP" 38 "STEERING_SATURATED_LANE_DEPARTURE" 39 "EPAS_STEERING_ANGLE_INVALID" 40 "W048_FEATURES_DISABLED" 41 "INVALID_DI_PEDAL_POS" 42 "INVALID_VEHICLE_SPEED" 43 "PERCEPTION_HEALTH_VISION" 44 "SEATBELT_UNBUCKLED" 45 "USER_OVERRIDE_STRIKEOUT" 46 "INTEGRATOR_HEALTH_CRITICAL" 47 "IBOOSTER_MIA" 48 "HEADLIGHT_OFF_AT_NIGHT" 49 "ONCOMING_LANE" 50 "INVALID_BEHAVIOR" 51 "CITY_STREETS_REF_TOO_SHORT" 52 "EXTENDED_COMPUTE_INACTIVE" 53 "PERCEPTION_HEALTH_POST_PROCESSING" 54 "PERCEPTION_HEALTH_STALE" 55 "DRIVER_NOT_PRESENT" 56 "AHB_MANUAL_OVERRIDE" 57 "CABIN_CAM_BLIND" 58 "EXTENDED_COMPUTE_INACTIVE_OTHER_SOC_HEALTH_UNKNOWN" 59 "EXTENDED_COMPUTE_INACTIVE_OTHER_SOC_HEALTH_CRITICAL" 60 "EXTENDED_COMPUTE_INACTIVE_ETHERNET_LINK_HEALTH" 61 "EXTENDED_COMPUTE_INACTIVE_PCIE_LINK_HEALTH" 255 "REASON_MAX" ;
VAL_ 583 DAS_controllerHealth 0 "HEALTHY" 1 "DEGRADED" 2 "CRITICAL" 3 "SOLVER_FAILURE" ;
VAL_ 583 DAS_behaviorReport 1 "VIEW_RANGE" 2 "CURVE_SPEED_ADAPTATION" 3 "RADAR_ONLY_BRAKING" 4 "KEEP_CALM" 5 "FLEET_SPEEDS" 6 "TRAFFIC_CONTROL_STOPPED_STATE" 7 "UNDERTAKE_ASSIST_KEEP_CALM" 8 "IN_LANE_VEHICLE" 9 "TARGET_LANE_VEHICLE" 10 "UNDERTAKE_VEHICLE" 11 "TRAFFIC_CONTROL" 12 "VISION_LANE_GEOMETRY" 13 "MAP_LANE_GEOMETRY" 14 "DRIVABLE_SPACE_VIOLATION" 15 "SLOWING_FOR_TARGET_LANE" 16 "VISION_SPEEDS" 17 "NAV_FLEET_SPEEDS" 18 "NAV_PATH_CSA" 19 "MERGE_VEHICLE_LEFT" 20 "MERGE_VEHICLE_RIGHT" 21 "CUTIN_VEHICLE_LEFT" 22 "CUTIN_VEHICLE_RIGHT" 23 "MP_AP_RESTRICTION" 24 "MP_NOT_BUCKLED" 25 "MP_DRIVER_MONITOR" 26 "MP_AP_STATE_MACHINE" 27 "MP_DI_CRUISE" 28 "MP_ULC" 29 "MP_AP_INACTIVE" 30 "ACTIVE_SAFETY_SLOWDOWN" 31 "STEERING_SATURATED" 32 "END_OF_NAV_ROUTE" 33 "LANE_SPEED_DIFF" 34 "STATIC_OBJECT" 35 "CUTIN_VEHICLE" 36 "STATIC_OBJECT_MERGE_LEFT" 37 "STATIC_OBJECT_MERGE_RIGHT" 38 "RISK_MANAGER" 39 "RELEVANT_VRU" 40 "CROSSWALK" 41 "CROSS_TRAFFIC_AVOIDANCE" 42 "TOLLBOOTH" 43 "ROUNDABOUT" 44 "SUGGESTED_VISION_SPEED" 45 "SPEED_BUMP" 46 "NARROW_CORRIDOR" 47 "TRAFFIC_CONTROL_LAUNCH" 48 "ONRAMP_BOOST" 49 "VANISHING_CIPV_KEEP_CALM" 50 "DYNAMIC_PINCH_POINT" 51 "APPROACHING_TURN" 52 "CLEAR_TO_GO" 53 "CROSSING_OBJECT" 54 "UNSUPPORTED_MANEUVER" 55 "PATH_BLOCKED" 56 "PATH_BLOCKED_BEYOND_TRAJ" 57 "REFERENCE_LENGTH" 58 "TRAJECTORY_OUTLIER_PRESSURE" 59 "CITY_MERGE_OBJECT" 60 "MAIN_CAMERA_SUN_GLARE" 61 "POOR_VISIBILITY" 62 "FORWARD_LATERAL_OBJECT" 63 "AHB_MANUAL_OVERRIDE" 64 "FAILED_LANE_CHANGE" 65 "CREEP_FOR_SHORT_REF" 66 "DRY_STEERING" 67 "CAUTION_LIGHTS" 68 "CAMERA_FAILSAFES" 69 "ROAD_SPEED" 70 "STOPPING_FOR_GEAR_CHANGE" 71 "MAX_SPEED_IN_REVERSE" ;
VAL_ 583 DAS_alcInternalState 0 "DISABLED" 1 "IDLE" 2 "ABORTING" 3 "BEHAVIOR_CHECK" 4 "PRE_ACTIVE_LEFT" 5 "PRE_ACTIVE_RIGHT" 6 "ACTIVE_LEFT" 7 "ACTIVE_RIGHT" 8 "ACTIVE_ACC_LEFT" 9 "ACTIVE_ACC_RIGHT" 10 "SOFT_ABORTING_LEFT" 11 "SOFT_ABORTING_RIGHT" 12 "RETRY" ;
VAL_ 583 DAS_controllerRef 0 "HEALTHY" 1 "UNHEALTHY" 2 "STALE_REFERENCE" 3 "STALE_LOCALIZATION" 4 "BAD_REF_UPDATE" 5 "REF_TOO_SHORT" 6 "INDETERMINATE" ;
VAL_ 583 DAS_mapAvailability 0 "NOT_AVAILABLE" 1 "AVAILABLE" ;
VAL_ 583 DAS_arbiterBehavior 0 "INVALID" 1 "IN_LANE" 2 "LANE_CHANGE_LEFT" 3 "LANE_CHANGE_RIGHT" 4 "CITY_STREETS" ;
VAL_ 583 DAS_roadEstimator 0 "HEALTHY" 1 "UNSTABLE_MEASUREMENTS" 2 "DEGRADED" 3 "CRITICAL" ;
CM_ BO_ 601 "ESP32-DualCAN Model3_CH. Seen on this car: 8-byte frames; fit good (bits covered 100%, mux 100%, ranges 100%, checksum 100%).";
VAL_ 601 APP_sentryState 0 "OFF" 1 "IDLE" 2 "ARMED" 3 "AWARE" 4 "PANIC" 5 "QUIET" 6 "SNA" ;
VAL_ 601 APP_fsdRevokeStrikeoutCount 7 "SNA" ;
VAL_ 601 APP_fsdSuspendState 0 "NOT_SUSPENDED" 1 "SUSPENDED" 3 "SNA" ;
VAL_ 601 APP_summonUnavailableReason 0 "UNKNOWN" 1 "NONE" 2 "NOT_IN_PARK" 3 "CAMERA_STREAM" 4 "CAMERA_BLOCKED" 5 "ULTRASONIC_BLOCKED" 6 "ULTRASONIC_FAULT" 7 "CRUISE_UNAVAILABLE" 8 "EAC_UNAVAILABLE" 9 "PUBLIC_ROAD" 10 "POOR_CONNECTION" 11 "PHONE_GPS_UNAVAILABLE" 12 "EGO_GPS_UNAVAILABLE" 13 "PHONE_IS_TOO_FAR" 14 "END_OF_LEASH" 15 "CAMERA_NOT_CALIBRATED" 16 "VISION_HEALTH_CRITICAL" 17 "ULTRASONIC_STALE" 18 "ALL_SENSORS_OCCLUDED" 19 "PUBLIC_ROAD_BOUNDARIES_NOT_VALID" 20 "NO_CONTEXT" ;
VAL_ 601 APP_clipRecordingStatus 0 "NO_DRIVE" 1 "IDLE" 2 "RECORDING" 3 "TRIGGERED" 4 "FAULTED" ;
VAL_ 601 APP_factorySummonStatus 0 "SNA" 1 "ACTIVE" 2 "AVAILABLE" 3 "UNAVAILABLE_NO_QR_INSTRUCTION" 4 "UNAVAILABLE_GOAL_TOO_FAR" 5 "UNAVAILABLE_NO_GPS" 6 "UNAVAILABLE_VEHICLE_SPEED_INVALID" 7 "UNAVAILABLE_HEADING_NOT_INITIALIZED" 8 "END_OF_ROUTE" ;
VAL_ 601 APP_fusedState 0 "UNKNOWN" 1 "UNFUSED" 2 "FUSED" 3 "SNA" ;
VAL_ 601 APP_watchdogState 0 "UNKNOWN" 1 "DEGRADED" 2 "CRITICAL" 3 "HEALTHY" 7 "SNA" ;
CM_ BO_ 603 "ESP32-DualCAN Model3_VEH. Seen on this car: 8-byte frames; fit ok (bits covered 100%, mux 100%, ranges 100%, checksum 0%).";
VAL_ 603 APP_sentryState 0 "OFF" 1 "IDLE" 2 "ARMED" 3 "AWARE" 4 "PANIC" 5 "QUIET" 6 "SNA" ;
VAL_ 603 APP_fsdRevokeStrikeoutCount 7 "SNA" ;
VAL_ 603 APP_fsdSuspendState 0 "NOT_SUSPENDED" 1 "SUSPENDED" 3 "SNA" ;
VAL_ 603 APP_summonUnavailableReason 0 "UNKNOWN" 1 "NONE" 2 "NOT_IN_PARK" 3 "CAMERA_STREAM" 4 "CAMERA_BLOCKED" 5 "ULTRASONIC_BLOCKED" 6 "ULTRASONIC_FAULT" 7 "CRUISE_UNAVAILABLE" 8 "EAC_UNAVAILABLE" 9 "PUBLIC_ROAD" 10 "POOR_CONNECTION" 11 "PHONE_GPS_UNAVAILABLE" 12 "EGO_GPS_UNAVAILABLE" 13 "PHONE_IS_TOO_FAR" 14 "END_OF_LEASH" 15 "CAMERA_NOT_CALIBRATED" 16 "VISION_HEALTH_CRITICAL" 17 "ULTRASONIC_STALE" 18 "ALL_SENSORS_OCCLUDED" 19 "PUBLIC_ROAD_BOUNDARIES_NOT_VALID" 20 "NO_CONTEXT" ;
VAL_ 603 APP_clipRecordingStatus 0 "NO_DRIVE" 1 "IDLE" 2 "RECORDING" 3 "TRIGGERED" 4 "FAULTED" ;
VAL_ 603 APP_factorySummonStatus 0 "SNA" 1 "ACTIVE" 2 "AVAILABLE" 3 "UNAVAILABLE_NO_QR_INSTRUCTION" 4 "UNAVAILABLE_GOAL_TOO_FAR" 5 "UNAVAILABLE_NO_GPS" 6 "UNAVAILABLE_VEHICLE_SPEED_INVALID" 7 "UNAVAILABLE_HEADING_NOT_INITIALIZED" 8 "END_OF_ROUTE" ;
VAL_ 603 APP_fusedState 0 "UNKNOWN" 1 "UNFUSED" 2 "FUSED" 3 "SNA" ;
VAL_ 603 APP_watchdogState 0 "UNKNOWN" 1 "DEGRADED" 2 "CRITICAL" 3 "HEALTHY" 7 "SNA" ;
CM_ BO_ 658 "ESP32-DualCAN Model3_VEH. Seen on this car: 8-byte frames; fit good (bits covered 100%, mux 100%, ranges 100%).";
CM_ BO_ 680 "ESP32-DualCAN Model3_VEH. Seen on this car: 8-byte frames; fit good (bits covered 100%, mux 100%, ranges 100%, checksum 100%).";
VAL_ 680 EPBL_brakeDiscWipeRequest 0 "NONE" 1 "LIGHT" 2 "STRONG" 3 "SNA" ;
VAL_ 680 EPBL_cdpRequest 0 "NOT_REQUESTED" 1 "REQUESTED" ;
VAL_ 680 EPBL_telltale 0 "LAMP_OFF" 1 "LAMP_RED_ON" 2 "LAMP_AMBER_ON" 3 "LAMP_RED_FLASH" 7 "SNA" ;
VAL_ 680 EPBL_freeRollModeStatus 0 "UNAVAILABLE" 1 "AVAILABLE" 2 "ENABLED" ;
VAL_ 680 EPBL_systemStatus 0 "UNKNOWN" 1 "RELEASED" 2 "PARKED" 3 "DYNAMIC" 4 "PARKING" 5 "RELEASING" 6 "FAULT" 7 "FAULT_SECURE" 8 "MISMATCH" ;
CM_ BO_ 792 "ESP32-DualCAN Model3_VEH. Seen on this car: 8-byte frames; fit good (bits covered 100%, mux 100%, ranges 100%, checksum 100%).";
CM_ BO_ 798 "ESP32-DualCAN Model3_VEH. Seen on this car: 8-byte frames; fit good (bits covered 100%, mux 100%, ranges 100%).";
VAL_ 798 CP_matrixIndex 0 "AlertMatrix0" 1 "AlertMatrix1" 2 "AlertMatrix2" ;
CM_ BO_ 800 "ESP32-DualCAN Model3_VEH. Seen on this car: 8-byte frames; fit good (bits covered 100%, mux 100%, ranges 100%).";
VAL_ 800 BMS_matrixIndex 0 "AlertMatrix0" 1 "AlertMatrix1" 2 "AlertMatrix2" ;
CM_ BO_ 810 "ESP32-DualCAN Model3_VEH. Seen on this car: 5-byte frames; fit weak (bits covered 100%, mux 100%, ranges 100%, checksum 0%).";
VAL_ 810 BMS_chgTimeToFull 4095 "SNA" ;
VAL_ 810 BMS_isolationResistance 1023 "SNA" ;
CM_ BO_ 826 "ESP32-DualCAN Model3_VEH. Seen on this car: 8-byte frames; fit good (bits covered 100%, mux 100%, ranges 100%).";
CM_ BO_ 890 "ESP32-DualCAN Model3_VEH. Seen on this car: 8-byte frames; fit good (bits covered 100%, mux 100%, ranges 100%).";
CM_ BO_ 970 "ESP32-DualCAN Model3_CH. Seen on this car: 8-byte frames; fit good (bits covered 100%, mux 100%, ranges 100%).";
CM_ BO_ 986 "ESP32-DualCAN Model3_VEH. Seen on this car: 8-byte frames; fit good (bits covered 100%, mux 100%, ranges 100%).";
CM_ BO_ 994 "ESP32-DualCAN Model3_VEH. Seen on this car: 8-byte frames; fit good (bits covered 86%, mux 100%, ranges 100%). read by the app or firmware.";
VAL_ 994 VCLEFT_reverseTrailerLightStatus 0 "OFF" 1 "ON" 2 "FAULT" 3 "SNA" ;
VAL_ 994 VCLEFT_trailerDetected 0 "SNA" 1 "FAULT" 2 "DETECTED" 3 "NOT_DETECTED" ;
VAL_ 994 VCLEFT_rearRideHeight 4294967168 "SNA" ;
VAL_ 994 VCLEFT_frontRideHeight 4294967168 "SNA" ;
VAL_ 994 VCLEFT_fogTrailerLightStatus 0 "OFF" 1 "ON" 2 "FAULT" 3 "SNA" ;
VAL_ 994 VCLEFT_tailTrailerLightStatus 0 "OFF" 1 "ON" 2 "FAULT" 3 "SNA" ;
VAL_ 994 VCLEFT_brakeTrailerLightStatus 0 "OFF" 1 "ON" 2 "FAULT" 3 "SNA" ;
VAL_ 994 VCLEFT_rightTrnTrailerLightStatu 0 "OFF" 1 "ON" 2 "FAULT" 3 "SNA" ;
VAL_ 994 VCLEFT_leftTurnTrailerLightStatu 0 "OFF" 1 "ON" 2 "FAULT" 3 "SNA" ;
VAL_ 994 VCLEFT_RRMapLightStatus 0 "OFF" 1 "ON" 2 "FAULT" 3 "SNA" ;
VAL_ 994 VCLEFT_RLMapLightStatus 0 "OFF" 1 "ON" 2 "FAULT" 3 "SNA" ;
VAL_ 994 VCLEFT_FRMapLightStatus 0 "OFF" 1 "ON" 2 "FAULT" 3 "SNA" ;
VAL_ 994 VCLEFT_FLMapLightStatus 0 "OFF" 1 "ON" 2 "FAULT" 3 "SNA" ;
VAL_ 994 VCLEFT_turnSignalStatus 0 "OFF" 1 "ON" 2 "FAULT" 3 "SNA" ;
VAL_ 994 VCLEFT_tailLightStatus 0 "OFF" 1 "ON" 2 "FAULT" 3 "SNA" ;
VAL_ 994 VCLEFT_brakeLightStatus 0 "OFF" 1 "ON" 2 "FAULT" 3 "SNA" ;
CM_ BO_ 1001 "ESP32-DualCAN Model3_VEH. Seen on this car: 8-byte frames; fit good (bits covered 100%, mux 100%, ranges 100%, checksum 100%). read by the app or firmware.";
VAL_ 1001 DAS_turnIndicatorRequestReason 0 "NONE" 1 "ACTIVE_NAV_LANE_CHANGE" 2 "ACTIVE_SPEED_LANE_CHANGE" 3 "ACTIVE_FORK" 4 "CANCEL_LANE_CHANGE" 5 "CANCEL_FORK" 6 "ACTIVE_MERGE" 7 "CANCEL_MERGE" 8 "ACTIVE_COMMANDED_LANE_CHANGE" 9 "ACTIVE_INTERSECTION" 10 "CANCEL_INTERSECTION" 11 "ACTIVE_SUMMMON" 12 "CANCEL_SUMMMON" 13 "ACTIVE_AUTO_PARK" 14 "CANCEL_AUTO_PARK" 15 "CANCEL_MANUAL_BLINKER" 17 "ACTIVE_STATIC_OBJECT_LANE_CHANGE" 18 "ACTIVE_INCORRECT_ROAD_SIDE_LANE_CHANGE" 19 "ACTIVE_EXIT_PASSING_LANE_LANE_CHANGE" 20 "ACTIVE_EXIT_RIGHT_LANE_LANE_CHANGE" 21 "ACTIVE_AWAY_FROM_MERGE_LANE_CHANGE" 22 "ACTIVE_STAY_OUT_OF_RIGHTMOST_LANE_LANE_CHANGE" 23 "ACTIVE_INFEASIBLE_KINEMATICS_LANE_CHANGE" ;
VAL_ 1001 DAS_autoWiperState 0 "OFF" 1 "SLOW_INTERMITTENT" 2 "FAST_INTERMITTENT" 3 "SLOW_CONTINUOUS" 4 "FAST_CONTINUOUS" 5 "SNA" ;
VAL_ 1001 DAS_mirrorFoldRequest 0 "NONE" 1 "FOLD" 2 "UNFOLD" 3 "SNA" ;
VAL_ 1001 DAS_highLowBeamOffReason 0 "ON" 1 "OFF_REASON_MOVING_VISION_TARGET" 2 "OFF_REASON_MOVING_RADAR_TARGET" 3 "OFF_REASON_AMBIENT_LIGHT" 4 "OFF_REASON_HEAD_LIGHT" 5 "OFF_REASON_SNA" ;
VAL_ 1001 DAS_heaterRequest 0 "SNA" 1 "OFF" 2 "ON" ;
VAL_ 1001 DAS_highLowBeamDecision 0 "UNDECIDED" 1 "OFF" 2 "ON" 3 "SNA" ;
VAL_ 1001 DAS_turnIndicatorRequest 0 "NONE" 1 "LEFT" 2 "RIGHT" 3 "CANCEL" 4 "DEFER" ;
VAL_ 1001 DAS_wiperSpeed 0 "OFF" 1 "1" 2 "2" 3 "3" 4 "4" 5 "5" 6 "6" 7 "7" 8 "8" 9 "9" 10 "10" 11 "11" 12 "12" 13 "13" 14 "14" 15 "INVALID" ;
VAL_ 1001 DAS_hazardLightRequest 0 "OFF" 1 "ON" 2 "UNUSED" 3 "SNA" ;
VAL_ 1001 DAS_headlightRequest 0 "OFF" 1 "ON" 3 "INVALID" ;
CM_ BO_ 1010 "ESP32-DualCAN Model3_VEH. Seen on this car: 8-byte frames; fit good (bits covered 100%, mux 100%, ranges 100%).";
VAL_ 1010 BMS_kwhCounter_Id 0 "MUX0" 1 "MUX1" 2 "MUX2" 3 "MUX3" 4 "MUX4" 5 "MUX5" 6 "MUX6" 7 "MUX7" 8 "MUX8" 9 "MUX9" 10 "MUX10" 11 "MUX11" 12 "MUX12" 13 "MUX13" 14 "END" ;
CM_ BO_ 1040 "ESP32-DualCAN Model3_CH. Seen on this car: 3-byte frames; fit ok (bits covered 100%, mux 100%, ranges 100%).";
CM_ BO_ 1066 "ESP32-DualCAN Model3_VEH. Seen on this car: 8-byte frames; fit good (bits covered 100%, mux 100%, ranges 100%).";
VAL_ 1066 VCSEC_TPMSConnectionTypeDesired3 0 "FAST" 1 "SLOW" 2 "UNKNOWN" ;
VAL_ 1066 VCSEC_TPMSConnectionTypeCurrent3 0 "FAST" 1 "SLOW" 2 "UNKNOWN" ;
VAL_ 1066 VCSEC_TPMSSensorState3 0 "NOT_PAIRED" 1 "WAIT_FOR_ADV" 2 "WAIT_FOR_CONN" 3 "CONNECTED" 4 "DISCONNECTING" ;
VAL_ 1066 VCSEC_TPMSConnectionTypeDesired2 0 "FAST" 1 "SLOW" 2 "UNKNOWN" ;
VAL_ 1066 VCSEC_TPMSConnectionTypeCurrent2 0 "FAST" 1 "SLOW" 2 "UNKNOWN" ;
VAL_ 1066 VCSEC_TPMSSensorState2 0 "NOT_PAIRED" 1 "WAIT_FOR_ADV" 2 "WAIT_FOR_CONN" 3 "CONNECTED" 4 "DISCONNECTING" ;
VAL_ 1066 VCSEC_TPMSConnectionTypeDesired1 0 "FAST" 1 "SLOW" 2 "UNKNOWN" ;
VAL_ 1066 VCSEC_TPMSConnectionTypeCurrent1 0 "FAST" 1 "SLOW" 2 "UNKNOWN" ;
VAL_ 1066 VCSEC_TPMSSensorState1 0 "NOT_PAIRED" 1 "WAIT_FOR_ADV" 2 "WAIT_FOR_CONN" 3 "CONNECTED" 4 "DISCONNECTING" ;
VAL_ 1066 VCSEC_TPMSConnectionTypeDesired0 0 "FAST" 1 "SLOW" 2 "UNKNOWN" ;
VAL_ 1066 VCSEC_TPMSConnectionTypeCurrent0 0 "FAST" 1 "SLOW" 2 "UNKNOWN" ;
VAL_ 1066 VCSEC_TPMSSensorState0 0 "NOT_PAIRED" 1 "WAIT_FOR_ADV" 2 "WAIT_FOR_CONN" 3 "CONNECTED" 4 "DISCONNECTING" ;
CM_ BO_ 1113 "ESP32-DualCAN Model3_CH. Seen on this car: 8-byte frames; fit good (bits covered 100%, mux 100%, ranges 100%).";
CM_ BO_ 1320 "ESP32-DualCAN Model3_VEH. Seen on this car: 4-byte frames; fit ok (bits covered 100%, mux 100%, ranges 100%).";
CM_ BO_ 1353 "ESP32-DualCAN Model3_CH. Seen on this car: 8-byte frames; fit good (bits covered 100%, mux 100%, ranges 100%).";
VAL_ 1353 APP_buildType 0 "SIGNED" 1 "LOCAL" 3 "REPO" ;
VAL_ 1353 APP_infoIndex 0 "AP_BUILD_TYPE" 1 "FW_GITHASH" 2 "AP_GITHASH" ;
